AUTOSAR XML (schema 00050)
package /FCADT/ComponentTypes
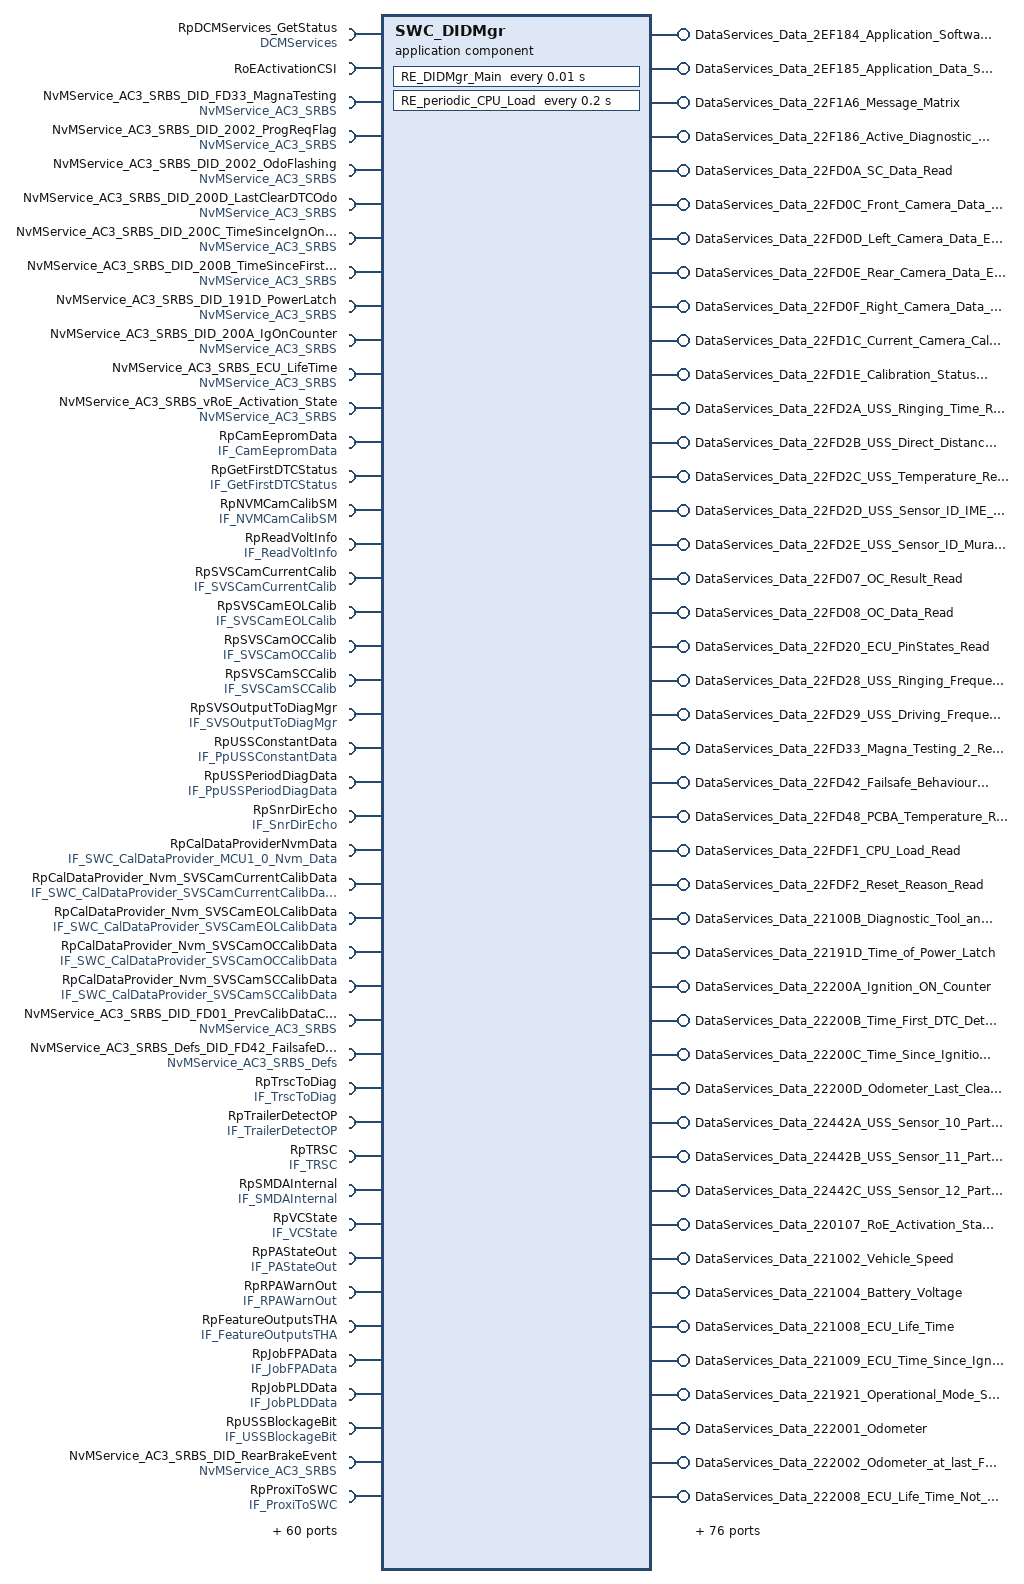
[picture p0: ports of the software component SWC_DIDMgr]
  application sw component type SWC_DIDMgr
    67 x provide port:
      DataServices_Data_2EF184_Application_Software_Fingerprint_writing_information: server-com-spec{operation=WriteData, queue-length=1}, provided-interface=DataServices_Data_2EF184_Application_Software_Fingerprint_writing_information
      DataServices_Data_2EF185_Application_Data_Software_Fingerprint_Writing_Information: server-com-spec{operation=WriteData, queue-length=1}, provided-interface=DataServices_Data_2EF185_Application_Data_Software_Fingerprint_Writing_Information
      DataServices_Data_22F1A6_Message_Matrix: server-com-spec{operation=ReadData, queue-length=1}, provided-interface=DataServices_Data_22F1A6_Message_Matrix
      DataServices_Data_22F186_Active_Diagnostic_Session: server-com-spec{operation=ReadData, queue-length=1}, provided-interface=DataServices_Data_22F186_Active_Diagnostic_Session
      DataServices_Data_22FD0A_SC_Data_Read: provided-com-specs=[{operation=ReadData, queue-length=1}, {operation=WriteData, queue-length=1}], provided-interface=DataServices_Data_22FD0A_SC_Data_Read
      DataServices_Data_22FD0C_Front_Camera_Data_EEPROM_Read: server-com-spec{operation=ReadData, queue-length=1}, provided-interface=DataServices_Data_22FD0C_Front_Camera_Data_EEPROM_Read
      DataServices_Data_22FD0D_Left_Camera_Data_EEPROM_Read: server-com-spec{operation=ReadData, queue-length=1}, provided-interface=DataServices_Data_22FD0D_Left_Camera_Data_EEPROM_Read
      DataServices_Data_22FD0E_Rear_Camera_Data_EEPROM_Read: server-com-spec{operation=ReadData, queue-length=1}, provided-interface=DataServices_Data_22FD0E_Rear_Camera_Data_EEPROM_Read
      DataServices_Data_22FD0F_Right_Camera_Data_EEPROM_Read: server-com-spec{operation=ReadData, queue-length=1}, provided-interface=DataServices_Data_22FD0F_Right_Camera_Data_EEPROM_Read
      DataServices_Data_22FD1C_Current_Camera_Calibration_Data_Read: server-com-spec{operation=ReadData, queue-length=1}, provided-interface=DataServices_Data_22FD1C_Current_Camera_Calibration_Data_Read
      DataServices_Data_22FD1E_Calibration_Status_Read: server-com-spec{operation=ReadData, queue-length=1}, provided-interface=DataServices_Data_22FD1E_Calibration_Status_Read
      DataServices_Data_22FD2A_USS_Ringing_Time_Read: server-com-spec{operation=ReadData, queue-length=1}, provided-interface=DataServices_Data_22FD2A_USS_Ringing_Time_Read
      DataServices_Data_22FD2B_USS_Direct_Distance_0xFD2B_Read: server-com-spec{operation=ReadData, queue-length=1}, provided-interface=DataServices_Data_22FD2B_USS_Direct_Distance_0xFD2B_Read
      DataServices_Data_22FD2C_USS_Temperature_Read: server-com-spec{operation=ReadData, queue-length=1}, provided-interface=DataServices_Data_22FD2C_USS_Temperature_Read
      DataServices_Data_22FD2D_USS_Sensor_ID_IME_SN_Read: server-com-spec{operation=ReadData, queue-length=1}, provided-interface=DataServices_Data_22FD2D_USS_Sensor_ID_IME_SN_Read
      DataServices_Data_22FD2E_USS_Sensor_ID_Murata_SN_Read: server-com-spec{operation=ReadData, queue-length=1}, provided-interface=DataServices_Data_22FD2E_USS_Sensor_ID_Murata_SN_Read
      DataServices_Data_22FD07_OC_Result_Read: server-com-spec{operation=ReadData, queue-length=1}, provided-interface=DataServices_Data_22FD07_OC_Result_Read
      DataServices_Data_22FD08_OC_Data_Read: provided-com-specs=[{operation=ReadData, queue-length=1}, {operation=WriteData, queue-length=1}], provided-interface=DataServices_Data_22FD08_OC_Data_Read
      DataServices_Data_22FD20_ECU_PinStates_Read: server-com-spec{operation=ReadData, queue-length=1}, provided-interface=DataServices_Data_22FD20_ECU_PinStates_Read
      DataServices_Data_22FD28_USS_Ringing_Frequency_Read: server-com-spec{operation=ReadData, queue-length=1}, provided-interface=DataServices_Data_22FD28_USS_Ringing_Frequency_Read
      DataServices_Data_22FD29_USS_Driving_Frequency_Read: server-com-spec{operation=ReadData, queue-length=1}, provided-interface=DataServices_Data_22FD29_USS_Driving_Frequency_Read
      DataServices_Data_22FD33_Magna_Testing_2_Read: provided-com-specs=[{operation=ReadData, queue-length=1}, {operation=WriteData, queue-length=1}], provided-interface=DataServices_Data_22FD33_Magna_Testing_2_Read
      DataServices_Data_22FD42_Failsafe_Behaviour_Read: provided-com-specs=[{operation=ReadData, queue-length=1}, {operation=WriteData, queue-length=1}], provided-interface=DataServices_Data_22FD42_Failsafe_Behaviour_Read
      DataServices_Data_22FD48_PCBA_Temperature_Read: server-com-spec{operation=ReadData, queue-length=1}, provided-interface=DataServices_Data_22FD48_PCBA_Temperature_Read
      DataServices_Data_22FDF1_CPU_Load_Read: server-com-spec{operation=ReadData, queue-length=1}, provided-interface=DataServices_Data_22FDF1_CPU_Load_Read
      DataServices_Data_22FDF2_Reset_Reason_Read: server-com-spec{operation=ReadData, queue-length=1}, provided-interface=DataServices_Data_22FDF2_Reset_Reason_Read
      DataServices_Data_22100B_Diagnostic_Tool_and_Session_Status: server-com-spec{operation=ReadData, queue-length=1}, provided-interface=DataServices_Data_22100B_Diagnostic_Tool_and_Session_Status
      DataServices_Data_22191D_Time_of_Power_Latch: server-com-spec{operation=ReadData, queue-length=1}, provided-interface=DataServices_Data_22191D_Time_of_Power_Latch
      DataServices_Data_22200A_Ignition_ON_Counter: server-com-spec{operation=ReadData, queue-length=1}, provided-interface=DataServices_Data_22200A_Ignition_ON_Counter
      DataServices_Data_22200B_Time_First_DTC_Detection: server-com-spec{operation=ReadData, queue-length=1}, provided-interface=DataServices_Data_22200B_Time_First_DTC_Detection
      DataServices_Data_22200C_Time_Since_Ignition_ON_of_first_DTC_Detection: server-com-spec{operation=ReadData, queue-length=1}, provided-interface=DataServices_Data_22200C_Time_Since_Ignition_ON_of_first_DTC_Detection
      DataServices_Data_22200D_Odometer_Last_Clear_Data_Trouble_Code_DTC: server-com-spec{operation=ReadData, queue-length=1}, provided-interface=DataServices_Data_22200D_Odometer_Last_Clear_Data_Trouble_Code_DTC
      DataServices_Data_22442A_USS_Sensor_10_Part_Number_Read: server-com-spec{operation=ReadData, queue-length=1}, provided-interface=DataServices_Data_22442A_USS_Sensor_10_Part_Number_Read
      DataServices_Data_22442B_USS_Sensor_11_Part_Number_Read: server-com-spec{operation=ReadData, queue-length=1}, provided-interface=DataServices_Data_22442B_USS_Sensor_11_Part_Number_Read
      DataServices_Data_22442C_USS_Sensor_12_Part_Number_Read: server-com-spec{operation=ReadData, queue-length=1}, provided-interface=DataServices_Data_22442C_USS_Sensor_12_Part_Number_Read
      DataServices_Data_220107_RoE_Activation_State: provided-com-specs=[{operation=ReadData, queue-length=1}, {operation=WriteData, queue-length=1}], provided-interface=DataServices_Data_220107_RoE_Activation_State
      DataServices_Data_221002_Vehicle_Speed: server-com-spec{operation=ReadData, queue-length=1}, provided-interface=DataServices_Data_221002_Vehicle_Speed
      DataServices_Data_221004_Battery_Voltage: server-com-spec{operation=ReadData, queue-length=1}, provided-interface=DataServices_Data_221004_Battery_Voltage
      DataServices_Data_221008_ECU_Life_Time: server-com-spec{operation=ReadData, queue-length=1}, provided-interface=DataServices_Data_221008_ECU_Life_Time
      DataServices_Data_221009_ECU_Time_Since_Ignition_ON: server-com-spec{operation=ReadData, queue-length=1}, provided-interface=DataServices_Data_221009_ECU_Time_Since_Ignition_ON
      DataServices_Data_221921_Operational_Mode_Status: server-com-spec{operation=ReadData, queue-length=1}, provided-interface=DataServices_Data_221921_Operational_Mode_Status
      DataServices_Data_222001_Odometer: server-com-spec{operation=ReadData, queue-length=1}, provided-interface=DataServices_Data_222001_Odometer
      DataServices_Data_222002_Odometer_at_last_Flash_programming: server-com-spec{operation=ReadData, queue-length=1}, provided-interface=DataServices_Data_222002_Odometer_at_last_Flash_programming
      DataServices_Data_222008_ECU_Life_Time_Not_Volatile_Memory: server-com-spec{operation=ReadData, queue-length=1}, provided-interface=DataServices_Data_222008_ECU_Life_Time_Not_Volatile_Memory
      DataServices_Data_222010_Programming_Status: server-com-spec{operation=ReadData, queue-length=1}, provided-interface=DataServices_Data_222010_Programming_Status
      DataServices_Data_222945_Flow_Control_Test: provided-com-specs=[{operation=ReadData, queue-length=1}, {operation=WriteData, queue-length=1}], provided-interface=DataServices_Data_222945_Flow_Control_Test
      DataServices_Data_224421_USS_Sensor_1_Part_Number_Read: server-com-spec{operation=ReadData, queue-length=1}, provided-interface=DataServices_Data_224421_USS_Sensor_1_Part_Number_Read
      DataServices_Data_224422_USS_Sensor2_Part_Number_Read: server-com-spec{operation=ReadData, queue-length=1}, provided-interface=DataServices_Data_224422_USS_Sensor2_Part_Number_Read
      DataServices_Data_224423_USS_Sensor_3_Part_Number_Read: server-com-spec{operation=ReadData, queue-length=1}, provided-interface=DataServices_Data_224423_USS_Sensor_3_Part_Number_Read
      DataServices_Data_224424_USS_Sensor_4_Part_Number_Read: server-com-spec{operation=ReadData, queue-length=1}, provided-interface=DataServices_Data_224424_USS_Sensor_4_Part_Number_Read
      DataServices_Data_224425_USS_Sensor_5_Part_Number_Read: server-com-spec{operation=ReadData, queue-length=1}, provided-interface=DataServices_Data_224425_USS_Sensor_5_Part_Number_Read
      DataServices_Data_224426_USS_Sensor_6_Part_Number_Read: server-com-spec{operation=ReadData, queue-length=1}, provided-interface=DataServices_Data_224426_USS_Sensor_6_Part_Number_Read
      DataServices_Data_224427_USS_Sensor_7_Part_Number_Read: server-com-spec{operation=ReadData, queue-length=1}, provided-interface=DataServices_Data_224427_USS_Sensor_7_Part_Number_Read
      DataServices_Data_224428_USS_Sensor_8_Part_Number_Read: server-com-spec{operation=ReadData, queue-length=1}, provided-interface=DataServices_Data_224428_USS_Sensor_8_Part_Number_Read
      DataServices_Data_224429_USS_Sensor_9_Part_Number_Read: server-com-spec{operation=ReadData, queue-length=1}, provided-interface=DataServices_Data_224429_USS_Sensor_9_Part_Number_Read
      DataServices_Data_224451_EOL_Calibration_State_Read: server-com-spec{operation=ReadData, queue-length=1}, provided-interface=DataServices_Data_224451_EOL_Calibration_State_Read
      DataServices_Data_225100_SPM_status_Read: server-com-spec{operation=ReadData, queue-length=1}, provided-interface=DataServices_Data_225100_SPM_status_Read
      DataServices_Data_225300_Rear_Braking_Event_1_Read: server-com-spec{operation=ReadData, queue-length=1}, provided-interface=DataServices_Data_225300_Rear_Braking_Event_1_Read
      DataServices_Data_225301_Rear_Braking_Event_2_Read: server-com-spec{operation=ReadData, queue-length=1}, provided-interface=DataServices_Data_225301_Rear_Braking_Event_2_Read
      DataServices_Data_225302_Rear_Braking_Event_3_Read: server-com-spec{operation=ReadData, queue-length=1}, provided-interface=DataServices_Data_225302_Rear_Braking_Event_3_Read
      DataServices_Data_225303_SPM_Event_Abort_1_Read: server-com-spec{operation=ReadData, queue-length=1}, provided-interface=DataServices_Data_225303_SPM_Event_Abort_1_Read
      DataServices_Data_225304_SPM_Event_Abort_2_Read: server-com-spec{operation=ReadData, queue-length=1}, provided-interface=DataServices_Data_225304_SPM_Event_Abort_2_Read
      DataServices_Data_225500_Trailer_Sense_and_Drive_Function_Data_Read: server-com-spec{operation=ReadData, queue-length=1}, provided-interface=DataServices_Data_225500_Trailer_Sense_and_Drive_Function_Data_Read
      DataServices_Data_225501_Trailer_coupler_sense_detection_Function_Data_Read: server-com-spec{operation=ReadData, queue-length=1}, provided-interface=DataServices_Data_225501_Trailer_coupler_sense_detection_Function_Data_Read
      PpECUTimeSinceIGON: nonqueued-sender-com-spec{data-element=ECUTimeStamp_IGON, init-value=0}, provided-interface=IF_ECUTimeSince_IGON
      PpECUTimeStamp: nonqueued-sender-com-spec{data-element=ECUTimeStamp, init-value=0}, provided-interface=IF_ECUTimeStamp
      PpIgOnCounter: nonqueued-sender-com-spec{data-element=IGCounter, init-value=0}, provided-interface=IF_IGON_Counter
    require port RpDCMServices_GetStatus: required-interface=DCMServices
      required-com-specs:
        GetSesCtrlType
        GetRequestKind
        SetActiveDiagnostic
        GetSecurityLevel
        ResetToDefaultSession
        GetActiveProtocol
    require port RoEActivationCSI: required-com-specs=[WriteData, ReadData], required-interface=RoEActivationCSI
    provide port DataServices_Data_22FD01_Previous_Camera_Calibration_Data: server-com-spec{operation=ReadData, queue-length=1}, provided-interface=DataServices_Data_22FD01_Previous_Camera_Calibration_Data
    provide port DataServices_Data_22FD00_Plant_Camera_Calibration_Data: provided-com-specs=[{operation=WriteData, queue-length=1}, {operation=ReadData, queue-length=1}], provided-interface=DataServices_Data_22FD00_Plant_Camera_Calibration_Data
    provide port DataServices_Data_225305_SPM_Event_Abort_3_Read: server-com-spec{operation=ReadData, queue-length=1}, provided-interface=DataServices_Data_225305_SPM_Event_Abort_3_Read
    29 x require port:
      NvMService_AC3_SRBS_DID_FD33_MagnaTesting: required-com-specs=[WriteBlock, SetRamBlockStatus, ReadBlock, InvalidateNvBlock, GetErrorStatus, EraseBlock], required-interface=NvMService_AC3_SRBS
      NvMService_AC3_SRBS_DID_2002_ProgReqFlag: required-com-specs=[WriteBlock, SetRamBlockStatus, ReadBlock, InvalidateNvBlock, GetErrorStatus, EraseBlock], required-interface=NvMService_AC3_SRBS
      NvMService_AC3_SRBS_DID_2002_OdoFlashing: required-com-specs=[WriteBlock, SetRamBlockStatus, ReadBlock, InvalidateNvBlock, GetErrorStatus, EraseBlock], required-interface=NvMService_AC3_SRBS
      NvMService_AC3_SRBS_DID_200D_LastClearDTCOdo: required-com-specs=[WriteBlock, SetRamBlockStatus, ReadBlock, InvalidateNvBlock, GetErrorStatus, EraseBlock], required-interface=NvMService_AC3_SRBS
      NvMService_AC3_SRBS_DID_200C_TimeSinceIgnOnFirstDTC: required-com-specs=[WriteBlock, SetRamBlockStatus, ReadBlock, InvalidateNvBlock, GetErrorStatus, EraseBlock], required-interface=NvMService_AC3_SRBS
      NvMService_AC3_SRBS_DID_200B_TimeSinceFirstDTC: required-com-specs=[WriteBlock, SetRamBlockStatus, ReadBlock, InvalidateNvBlock, GetErrorStatus, EraseBlock], required-interface=NvMService_AC3_SRBS
      NvMService_AC3_SRBS_DID_191D_PowerLatch: required-com-specs=[WriteBlock, SetRamBlockStatus, ReadBlock, InvalidateNvBlock, GetErrorStatus, EraseBlock], required-interface=NvMService_AC3_SRBS
      NvMService_AC3_SRBS_DID_200A_IgOnCounter: required-com-specs=[WriteBlock, SetRamBlockStatus, ReadBlock, InvalidateNvBlock, GetErrorStatus, EraseBlock], required-interface=NvMService_AC3_SRBS
      NvMService_AC3_SRBS_ECU_LifeTime: required-com-specs=[WriteBlock, SetRamBlockStatus, ReadBlock, InvalidateNvBlock, GetErrorStatus, EraseBlock], required-interface=NvMService_AC3_SRBS
      NvMService_AC3_SRBS_vRoE_Activation_State: required-com-specs=[WriteBlock, SetRamBlockStatus, ReadBlock, InvalidateNvBlock, GetErrorStatus, EraseBlock], required-interface=NvMService_AC3_SRBS
      RpCamEepromData: nonqueued-receiver-com-spec{data-element=Svs_CamEepromDataArray_t, filter=data-filter-type=ALWAYS}, required-interface=IF_CamEepromData
      RpGetFirstDTCStatus: nonqueued-receiver-com-spec{data-element=DeFirstDTCStatus, filter=data-filter-type=ALWAYS}, required-interface=IF_GetFirstDTCStatus
      RpNVMCamCalibSM: nonqueued-receiver-com-spec{data-element=TbSVS_e_SVSOutputToNVMCamCalibSM_t, filter=data-filter-type=ALWAYS}, required-interface=IF_NVMCamCalibSM
      RpReadVoltInfo: client-com-spec=GetVoltageInfo, required-interface=IF_ReadVoltInfo
      RpSVSCamCurrentCalib: nonqueued-receiver-com-spec{data-element=TbSVS_S_SVSCamCurrentCalibDataToNVM_t, filter=data-filter-type=ALWAYS}, required-interface=IF_SVSCamCurrentCalib
      RpSVSCamEOLCalib: nonqueued-receiver-com-spec{data-element=TbSVS_S_SVSCamEOLCalibDataToNVM_t, filter=data-filter-type=ALWAYS}, required-interface=IF_SVSCamEOLCalib
      RpSVSCamOCCalib: nonqueued-receiver-com-spec{data-element=TbSVS_S_SVSCamOCCalibDataToNVM_t, filter=data-filter-type=ALWAYS}, required-interface=IF_SVSCamOCCalib
      RpSVSCamSCCalib: nonqueued-receiver-com-spec{data-element=TbSVS_S_SVSCamSCCalibDataToNVM_t, filter=data-filter-type=ALWAYS}, required-interface=IF_SVSCamSCCalib
      RpSVSOutputToDiagMgr: nonqueued-receiver-com-spec{data-element=TbSVS_e_SVSOutputToDiagMgrCamCalib_t, filter=data-filter-type=ALWAYS}, required-interface=IF_SVSOutputToDiagMgr
      RpUSSConstantData: nonqueued-receiver-com-spec{data-element=US_S_USSConstantData_t, filter=data-filter-type=ALWAYS}, required-interface=IF_PpUSSConstantData
      RpUSSPeriodDiagData: nonqueued-receiver-com-spec{data-element=US_S_USSPeriodDiagData_t, filter=data-filter-type=ALWAYS}, required-interface=IF_PpUSSPeriodDiagData
      RpSnrDirEcho: nonqueued-receiver-com-spec{data-element=US_S_SnrDirEcho_t, filter=data-filter-type=ALWAYS}, required-interface=IF_SnrDirEcho
      RpCalDataProviderNvmData: nonqueued-receiver-com-spec{data-element=CalData_mcu1_0, filter=data-filter-type=ALWAYS}, required-interface=IF_SWC_CalDataProvider_MCU1_0_Nvm_Data
      RpCalDataProvider_Nvm_SVSCamCurrentCalibData: client-com-spec=WriteBlock, required-interface=IF_SWC_CalDataProvider_SVSCamCurrentCalibData
      RpCalDataProvider_Nvm_SVSCamEOLCalibData: client-com-spec=WriteBlock, required-interface=IF_SWC_CalDataProvider_SVSCamEOLCalibData
      RpCalDataProvider_Nvm_SVSCamOCCalibData: client-com-spec=WriteBlock, required-interface=IF_SWC_CalDataProvider_SVSCamOCCalibData
      RpCalDataProvider_Nvm_SVSCamSCCalibData: client-com-spec=WriteBlock, required-interface=IF_SWC_CalDataProvider_SVSCamSCCalibData
      NvMService_AC3_SRBS_DID_FD01_PrevCalibDataCopy: required-com-specs=[WriteBlock, SetRamBlockStatus, ReadBlock, InvalidateNvBlock, GetErrorStatus, EraseBlock], required-interface=NvMService_AC3_SRBS
      NvMService_AC3_SRBS_Defs_DID_FD42_FailsafeDebug: required-com-specs=[EraseBlock, InvalidateNvBlock, RestoreBlockDefaults, WriteBlock, ReadBlock, SetRamBlockStatus, GetErrorStatus], required-interface=NvMService_AC3_SRBS_Defs
    provide port PpFailsafeDebug: nonqueued-sender-com-spec{data-element=Debugflag, init-value=0}, provided-interface=IF_FailsafeDebug
    23 x require port:
      RpTrscToDiag: nonqueued-receiver-com-spec{data-element=TRSCtoDiagMgr_t, filter=data-filter-type=ALWAYS}, required-interface=IF_TrscToDiag
      RpTrailerDetectOP: nonqueued-receiver-com-spec{data-element=TrailerDetection_Output_DID_t, filter=data-filter-type=ALWAYS}, required-interface=IF_TrailerDetectOP
      RpTRSC: nonqueued-receiver-com-spec=data-element=ME_VehOut_TRSC_t, required-interface=IF_TRSC
      RpSMDAInternal: nonqueued-receiver-com-spec=data-element=TbAP_SMDAInternalOut_t, required-interface=IF_SMDAInternal
      RpVCState: nonqueued-receiver-com-spec=data-element=TbAP_VCStateOut_t, required-interface=IF_VCState
      RpPAStateOut: nonqueued-receiver-com-spec=data-element=TbAP_PAStateOut_t, required-interface=IF_PAStateOut
      RpRPAWarnOut: nonqueued-receiver-com-spec=data-element=TbAP_RPAWarnOut_t, required-interface=IF_RPAWarnOut
      RpFeatureOutputsTHA: nonqueued-receiver-com-spec=data-element=TbTHASmVc_FeatureOutputs_t, required-interface=IF_FeatureOutputsTHA
      RpJobFPAData: nonqueued-receiver-com-spec{data-element=IJobFPAOutput_t, filter=data-filter-type=ALWAYS}, required-interface=IF_JobFPAData
      RpJobPLDData: nonqueued-receiver-com-spec{data-element=IJobPLDOutput_t, filter=data-filter-type=ALWAYS}, required-interface=IF_JobPLDData
      RpUSSBlockageBit: nonqueued-receiver-com-spec{data-element=US_S_BlockageBit_t, filter=data-filter-type=ALWAYS}, required-interface=IF_USSBlockageBit
      NvMService_AC3_SRBS_DID_RearBrakeEvent: required-com-specs=[WriteBlock, SetRamBlockStatus, ReadBlock, InvalidateNvBlock, GetErrorStatus, EraseBlock], required-interface=NvMService_AC3_SRBS
      RpProxiToSWC: required-interface=IF_ProxiToSWC
        required-com-specs:
          data-element=TyreSz_u16, filter=data-filter-type=ALWAYS
          data-element=SurroundViewCam_u8, filter=data-filter-type=ALWAYS
          data-element=Fullautomaticparking, filter=data-filter-type=ALWAYS
          data-element=PRX_CanNod27_b, filter=data-filter-type=ALWAYS
          data-element=Parkwithstop_u8, filter=data-filter-type=ALWAYS
          data-element=Trailerhitchassist_u8, filter=data-filter-type=ALWAYS
          data-element=PAMConfig_u8, filter=data-filter-type=ALWAYS
          data-element=Pamtuningset, filter=data-filter-type=ALWAYS
      NvMService_AC3_SRBS_DID_SPMAbrtEvent: required-com-specs=[WriteBlock, SetRamBlockStatus, ReadBlock, InvalidateNvBlock, GetErrorStatus, EraseBlock], required-interface=NvMService_AC3_SRBS
      RpScreenRequest: nonqueued-receiver-com-spec{data-element=ScreenRequest_t, filter=data-filter-type=ALWAYS}, required-interface=IF_ScreenRequest
      RpSvsToVCAN: nonqueued-receiver-com-spec{data-element=SvsToVCAN_t, filter=data-filter-type=ALWAYS, init-value=fields=[IeSVS_b_SPMScrnReq:0, IeSVS_b_ImgDefeatReqSts:0, IeSVS_b_MoreCamsReqSts:0, IeSVS_b_AUXCamReqSts:0, IeSVS_e_DispView2:0]}, required-interface=IF_SvsToVCAN
      RpCryptoArray: client-com-spec=CryptoArray, required-interface=IF_CryptoArray
      RpCpuLoadMcu2_1: nonqueued-receiver-com-spec{data-element=CpuLoadMcu2_1_t, filter=data-filter-type=ALWAYS, init-value=fields=CpluLoad_MCU2_1_u32:0}, required-interface=IF_CpuLoadMcu2_1
      RpCpuLoadMcu2_0: nonqueued-receiver-com-spec{data-element=CpuLoadMcu2_0_t, filter=data-filter-type=ALWAYS, init-value=fields=CpluLoad_MCU2_0_u32:0}, required-interface=IF_CpuLoadMcu2_0
      RpUSSErrorDiagData: nonqueued-receiver-com-spec=data-element=US_S_USSErrorDiagData_t, required-interface=IF_USSErrorDiagData
      RpPointDistOpBuff: nonqueued-receiver-com-spec{data-element=US_S_PointDistOutputBuff_t, filter=data-filter-type=ALWAYS, init-value=fields=[timestamp:0, minDist:16 x 0, midDist:12 x 0]}, required-interface=IF_PointDistOpBuff
      RpJobTHADetOutput: nonqueued-receiver-com-spec{data-element=JobTHADetOutput_t, filter=data-filter-type=ALWAYS}, required-interface=IF_JobTHADetOutput
      RpSvsToTHA: nonqueued-receiver-com-spec{data-element=SvsToTHA_t, filter=data-filter-type=ALWAYS}, required-interface=IF_SvsToTHA
    provide port DataServices_Data_22FD86_Functional_Settings_Read: provided-com-specs=[{operation=WriteData, queue-length=1}, {operation=ReadData, queue-length=1}], provided-interface=DataServices_Data_22FD86_Functional_Settings_Read
    4 x require port:
      RpError_CS_B: client-com-spec=ReportErrorStatus1_0_B, required-interface=P_Error_CS
      RpError_CS_QM: client-com-spec=ReportErrorStatus1_0_QM, required-interface=P_Error_CS
      NvMService_AC3_SRBS_DID_FD86_FunctionalSettings: required-com-specs=[WriteBlock, SetRamBlockStatus, ReadBlock, InvalidateNvBlock, GetErrorStatus, EraseBlock], required-interface=NvMService_AC3_SRBS
      RpTbTHASmVcDiag: nonqueued-receiver-com-spec{data-element=TbTHASmVc_DiagMgr_t, filter=data-filter-type=ALWAYS}, required-interface=IF_TbTHASmVcDiag
    provide port DataServices_Data_22FD46_Camera_Power_Supply_Read: server-com-spec{operation=ReadData, queue-length=1}, provided-interface=DataServices_Data_22FD46_Camera_Power_Supply_Read
    require port RpCamCsData: nonqueued-receiver-com-spec{data-element=CAM_CS_Curr_Monitor_t, filter=data-filter-type=ALWAYS}, required-interface=IF_CamCsData
    require port RpUssPowerData: nonqueued-receiver-com-spec{data-element=UssPower, filter=data-filter-type=ALWAYS, init-value=fields=[v_USS_PWR_A_MON_f32:0, v_USS_PWR_B_MON_f32:0, v_USS_PWR_C_MON_f32:0, v_USS_PWR_IS1_MON_MON_f32:[0, 0], v_USS_PWR_IS2_MON_MON_f32:0]}, required-interface=IF_UssPowerData
    26 x provide port:
      DataServices_Data_2F5001_Gear_Position_Read: provided-interface=DataServices_Data_2F5001_Gear_Position_Read
        provided-com-specs:
          operation=ShortTermAdjustment, queue-length=1
          operation=ReturnControlToECU, queue-length=1
          operation=ReadData, queue-length=1
      DataServices_Data_225102_FD_CAN14_Rx_Signals_Read: server-com-spec{operation=ReadData, queue-length=1}, provided-interface=DataServices_Data_225102_FD_CAN14_Rx_Signals_Read
      DataServices_Data_225103_FD_CAN2_Rx_Signals_Read: server-com-spec{operation=ReadData, queue-length=1}, provided-interface=DataServices_Data_225103_FD_CAN2_Rx_Signals_Read
      DataServices_Data_225104_FD_CAN14_Tx_Signals_Read: server-com-spec{operation=ReadData, queue-length=1}, provided-interface=DataServices_Data_225104_FD_CAN14_Tx_Signals_Read
      DataServices_Data_225105_FD_CAN2_Tx_Signals_Read: server-com-spec{operation=ReadData, queue-length=1}, provided-interface=DataServices_Data_225105_FD_CAN2_Tx_Signals_Read
      DataServices_Data_2EFD4E_Reset_NVM_Write: server-com-spec{operation=WriteData, queue-length=1}, provided-interface=DataServices_Data_2EFD4E_Reset_NVM_Write
      DataServices_Data_22FD47_SoC_Temperature_0xFD47_Read: server-com-spec{operation=ReadData, queue-length=1}, provided-interface=DataServices_Data_22FD47_SoC_Temperature_0xFD47_Read
      DataServices_Data_22FD49_SoC_Die_Temperature_ID_0xFD49_Read: server-com-spec{operation=ReadData, queue-length=1}, provided-interface=DataServices_Data_22FD49_SoC_Die_Temperature_ID_0xFD49_Read
      DataServices_Data_22FD60_ECU_Software_Status_Read: server-com-spec{operation=ReadData, queue-length=1}, provided-interface=DataServices_Data_22FD60_ECU_Software_Status_Read
      DataServices_Data_22FD62_ASIL_QM_Fault_Status_Read: server-com-spec{operation=ReadData, queue-length=1}, provided-interface=DataServices_Data_22FD62_ASIL_QM_Fault_Status_Read
      DataServices_Data_22FD64_ASIL_B_Fault_Status_Read: server-com-spec{operation=ReadData, queue-length=1}, provided-interface=DataServices_Data_22FD64_ASIL_B_Fault_Status_Read
      DataServices_Data_22FDF0_ECU_shutdown_process_Read: provided-com-specs=[{operation=WriteData, queue-length=1}, {operation=ReadData, queue-length=1}], provided-interface=DataServices_Data_22FDF0_ECU_shutdown_process_Read
      DataServices_Data_222026_CAN_Overrun_Counters: server-com-spec{operation=ReadData, queue-length=1}, provided-interface=DataServices_Data_222026_CAN_Overrun_Counters
      DataServices_Data_222939_FDCAN2_BUS_Network_WakeUp_Reason: server-com-spec{operation=ReadData, queue-length=1}, provided-interface=DataServices_Data_222939_FDCAN2_BUS_Network_WakeUp_Reason
      DataServices_Data_2E2023_PROXI_Data: server-com-spec{operation=WriteData, queue-length=1}, provided-interface=DataServices_Data_2E2023_PROXI_Data
      DataServices_Data_22F1A1_Configuration_Code: server-com-spec{operation=ReadData, queue-length=1}, provided-interface=DataServices_Data_22F1A1_Configuration_Code
      DataServices_Data_22F1B0_VIN_Current: server-com-spec{operation=ReadData, queue-length=1}, provided-interface=DataServices_Data_22F1B0_VIN_Current
      DataServices_Data_22F190_VIN_Original: server-com-spec{operation=ReadData, queue-length=1}, provided-interface=DataServices_Data_22F190_VIN_Original
      DataServices_Data_22FD61_Vehicle_Variant_Coding_Data_Read: server-com-spec{operation=ReadData, queue-length=1}, provided-interface=DataServices_Data_22FD61_Vehicle_Variant_Coding_Data_Read
      DataServices_Data_22102A_Check_EOL_Configuration_Data: server-com-spec{operation=ReadData, queue-length=1}, provided-interface=DataServices_Data_22102A_Check_EOL_Configuration_Data
      DataServices_Data_22292E_PROXI_Write_Counter: server-com-spec{operation=ReadData, queue-length=1}, provided-interface=DataServices_Data_22292E_PROXI_Write_Counter
      DataServices_Data_220103_VIN_Lock_Status: server-com-spec{operation=ReadData, queue-length=1}, provided-interface=DataServices_Data_220103_VIN_Lock_Status
      DataServices_Data_222013_VIN_Lock_State_Read: server-com-spec{operation=ReadData, queue-length=1}, provided-interface=DataServices_Data_222013_VIN_Lock_State_Read
      DataServices_Data_222024_Read_ECU_PROXI_Data: provided-com-specs=[{operation=ReadDataLength, queue-length=1}, {operation=ReadData, queue-length=1}], provided-interface=DataServices_Data_222024_Read_ECU_PROXI_Data
      DataServices_Data_225201_Plant_Mode_Status_Read: server-com-spec{operation=ReadData, queue-length=1}, provided-interface=DataServices_Data_225201_Plant_Mode_Status_Read
      DataServices_Data_22F10B_ECU_Qualification: server-com-spec{operation=ReadData, queue-length=1}, provided-interface=DataServices_Data_22F10B_ECU_Qualification
    require port NvMService_AC3_SRBS_DID_FDF0_SleepProcess: required-com-specs=[WriteBlock, SetRamBlockStatus, ReadBlock, InvalidateNvBlock, GetErrorStatus, EraseBlock], required-interface=NvMService_AC3_SRBS
    require port NvMService_AC3_SRBS_DID_2939_WakeupReason: required-com-specs=[WriteBlock, SetRamBlockStatus, ReadBlock, InvalidateNvBlock, GetErrorStatus, EraseBlock], required-interface=NvMService_AC3_SRBS
    provide port PpSleepProcessState: nonqueued-sender-com-spec{data-element=status, init-value=0}, provided-interface=IF_SleepProcessState
    require port Rp2023_ProxiData: client-com-spec=WriteData, required-interface=IF_2023_ProxiData
    require port RpVariantData: nonqueued-receiver-com-spec{data-element=Variant, filter=data-filter-type=ALWAYS}, required-interface=IF_VariantData
    require port RpProxiConfigData: nonqueued-receiver-com-spec{data-element=ProxiData, filter=data-filter-type=ALWAYS}, required-interface=IF_ProxiConfigData
    provide port PpGearPosition: provided-com-specs=[{data-element=GearValue, init-value=0}, {data-element=ShortTermAdjActiveFlag_b, init-value=0}], provided-interface=IF_GearPosition
    7 x require port:
      RpVINData: required-interface=IF_VINData
        required-com-specs:
          data-element=VINOriginalData, filter=data-filter-type=ALWAYS
          data-element=VINCurrentData, filter=data-filter-type=ALWAYS
          data-element=VINOdoCounter, filter=data-filter-type=ALWAYS
          data-element=VINLockStatus, filter=data-filter-type=ALWAYS
      RpPlantMode: nonqueued-receiver-com-spec{data-element=Status, filter=data-filter-type=ALWAYS}, required-interface=IF_PlantMode
      RpProxiErrorData: nonqueued-receiver-com-spec{data-element=Error, filter=data-filter-type=ALWAYS, init-value=fields=[ErrorFound:[0, 0, 0], ByteWithError:[0, 0, 0], BitInformationMask:[0, 0, 0]]}, required-interface=IF_ProxiErrorData
      RpToSwcSafeFD02Rx: required-interface=IF_FromComSafeFD02Rx
        required-com-specs:
          data-element=Active_Park_Mode, filter=data-filter-type=ALWAYS, init-value=0
          data-element=Active_Park_Prox_Chime, filter=data-filter-type=ALWAYS, init-value=0
          data-element=APARequestSts, filter=data-filter-type=ALWAYS, init-value=0
          data-element=Backup_Cam_Delay, filter=data-filter-type=ALWAYS, init-value=0
          data-element=Brk_Stat, filter=data-filter-type=ALWAYS, init-value=0
          data-element=CmdIgnSts, filter=data-filter-type=ALWAYS, init-value=0
          data-element=DriverDoorSts, filter=data-filter-type=ALWAYS, init-value=0
          data-element=DynamicGrid, filter=data-filter-type=ALWAYS, init-value=1
          data-element=ExternalTemperature, filter=data-filter-type=ALWAYS, init-value=0
          data-element=FT_PAMRequestSts, filter=data-filter-type=ALWAYS, init-value=0
          data-element=Fwrd_Cam_Guidelines, filter=data-filter-type=ALWAYS, init-value=0
          data-element=GearEngaged, filter=data-filter-type=ALWAYS, init-value=0
          data-element=HAS_Status_C2, filter=data-filter-type=ALWAYS, init-value=0
          data-element=LanguageSelection, filter=data-filter-type=ALWAYS, init-value=0
          data-element=LatAcceleration_BSM, filter=data-filter-type=ALWAYS, init-value=4095
          data-element=LHRDoorSts, filter=data-filter-type=ALWAYS, init-value=0
          data-element=LongAcceleration_BSM, filter=data-filter-type=ALWAYS, init-value=4095
          data-element=LwsAngle, filter=data-filter-type=ALWAYS, init-value=0
          data-element=LwsAngleType, filter=data-filter-type=ALWAYS, init-value=0
          data-element=LwsSpeed, filter=data-filter-type=ALWAYS, init-value=0
          data-element=MRM_STATUS_C2, filter=data-filter-type=ALWAYS, init-value=0
          data-element=PamChimeVolumeFront, filter=data-filter-type=ALWAYS, init-value=1
          data-element=PamChimeVolumeRear, filter=data-filter-type=ALWAYS, init-value=1
          data-element=PAMRequestSts, filter=data-filter-type=ALWAYS, init-value=0
          data-element=PsngrDoorSts, filter=data-filter-type=ALWAYS, init-value=0
          data-element=Rear_Brk_Asst, filter=data-filter-type=ALWAYS, init-value=0
          data-element=RHatchSts, filter=data-filter-type=ALWAYS, init-value=0
          data-element=RHRDoorSts, filter=data-filter-type=ALWAYS, init-value=0
          data-element=ShiftLeverPosition, filter=data-filter-type=ALWAYS, init-value=0
          data-element=SVC_Guidelines, filter=data-filter-type=ALWAYS, init-value=0
          data-element=TargetGear, filter=data-filter-type=ALWAYS, init-value=15
          data-element=TCASERANGESTATUS, filter=data-filter-type=ALWAYS, init-value=0
          data-element=TGW_CAMERA_DISP_STAT, filter=data-filter-type=ALWAYS, init-value=0
          data-element=TrailerConnectionSts, filter=data-filter-type=ALWAYS, init-value=0
          data-element=TRANS_ADAS_Inhibit, filter=data-filter-type=ALWAYS, init-value=0
          data-element=TransmissionSailingSts, filter=data-filter-type=ALWAYS, init-value=0
          data-element=VehicleSpeedVSOSig, filter=data-filter-type=ALWAYS, init-value=0
          data-element=YawRate_BSM, filter=data-filter-type=ALWAYS, init-value=4095
          data-element=VIN_MSG, filter=data-filter-type=ALWAYS
          data-element=VIN_DATA, filter=data-filter-type=ALWAYS
          data-element=RR_Lvl_Adj, filter=data-filter-type=ALWAYS
          data-element=RR_Lvl, filter=data-filter-type=ALWAYS
          data-element=RL_Lvl_Adj, filter=data-filter-type=ALWAYS
          data-element=RL_Lvl, filter=data-filter-type=ALWAYS
          data-element=HU_TRSC_EnableBtn_Sts, filter=data-filter-type=ALWAYS
          data-element=GearEngagedForDisplay, filter=data-filter-type=ALWAYS
          data-element=FR_Lvl_Adj, filter=data-filter-type=ALWAYS
          data-element=FR_Lvl, filter=data-filter-type=ALWAYS
          data-element=FL_Lvl_Adj, filter=data-filter-type=ALWAYS
          data-element=FL_Lvl, filter=data-filter-type=ALWAYS
          data-element=ESS_ENG_ST_W, filter=data-filter-type=ALWAYS
          data-element=EngineSts_W, filter=data-filter-type=ALWAYS
          data-element=ECM_TRSC_Resp, filter=data-filter-type=ALWAYS
          data-element=ECM_THA_Resp, filter=data-filter-type=ALWAYS
          data-element=ASCM_SysFail, filter=data-filter-type=ALWAYS
          data-element=ASCM_Stat, filter=data-filter-type=ALWAYS
          data-element=PdlPosActual, filter=data-filter-type=ALWAYS
          data-element=THA_SteeringTouchStat, filter=data-filter-type=ALWAYS
          data-element=EPS_THA_SteeringTorqueResp, filter=data-filter-type=ALWAYS
          data-element=EPS_THA_DriverTorqueOverride, filter=data-filter-type=ALWAYS
          data-element=EPS_SteeringTouq_Resp, filter=data-filter-type=ALWAYS
          data-element=EPS_SteeringTouchStat, filter=data-filter-type=ALWAYS
          data-element=ShiftLeverPositionReq, filter=data-filter-type=ALWAYS
          data-element=Shifter_ADAS_Inhibit, filter=data-filter-type=ALWAYS
          data-element=ITBM_TrlrStat, filter=data-filter-type=ALWAYS
          data-element=CM_TCH_Y_COORD, filter=data-filter-type=ALWAYS
          data-element=CM_TCH_X_COORD, filter=data-filter-type=ALWAYS
          data-element=CM_TCH_STAT, filter=data-filter-type=ALWAYS
          data-element=CameraDisplaySts2, filter=data-filter-type=ALWAYS
      RpToSwcSafeFD14Rx: required-interface=IF_FromComSafeFD14Rx
        required-com-specs:
          data-element=FD14_ACC_Systemsts, filter=data-filter-type=ALWAYS, init-value=0
          data-element=FD14_Brk_Stat, filter=data-filter-type=ALWAYS, init-value=0
          data-element=FD14_BrkPdl_Stat, filter=data-filter-type=ALWAYS, init-value=3
          data-element=FD14_BrkTrq, filter=data-filter-type=ALWAYS, init-value=32767
          data-element=FD14_BrkTrq_Driver, filter=data-filter-type=ALWAYS, init-value=32767
          data-element=FD14_BSM_THA_Brk_Resp, filter=data-filter-type=ALWAYS, init-value=0
          data-element=FD14_EPBSts, filter=data-filter-type=ALWAYS, init-value=0
          data-element=FD14_EPS_HandsOnRecognition, filter=data-filter-type=ALWAYS, init-value=0
          data-element=FD14_ESC_TRSC_Brk_Resp, filter=data-filter-type=ALWAYS, init-value=0
          data-element=FD14_ExternalBrkRequestsDisabled, filter=data-filter-type=ALWAYS, init-value=0
          data-element=FD14_HAS_Status, filter=data-filter-type=ALWAYS, init-value=0
          data-element=FD14_LatAcceleration_BSM, filter=data-filter-type=ALWAYS, init-value=4095
          data-element=FD14_LatAccelerationFailSts_BSM, filter=data-filter-type=ALWAYS, init-value=0
          data-element=FD14_LatAccelerationOffset_BSM, filter=data-filter-type=ALWAYS, init-value=255
          data-element=FD14_LHF_FastPulseCounter, filter=data-filter-type=ALWAYS, init-value=0
          data-element=FD14_LHF_Spin, filter=data-filter-type=ALWAYS, init-value=0
          data-element=FD14_LHF_WheelSensorFailSts, filter=data-filter-type=ALWAYS, init-value=0
          data-element=FD14_LHFWheelSpeed, filter=data-filter-type=ALWAYS, init-value=0
          data-element=FD14_LHR_FastPulseCounter, filter=data-filter-type=ALWAYS, init-value=0
          data-element=FD14_LHR_Spin, filter=data-filter-type=ALWAYS, init-value=0
          data-element=FD14_LHR_WheelSensorFailSts, filter=data-filter-type=ALWAYS, init-value=0
          data-element=FD14_LHRWheelSpeed, filter=data-filter-type=ALWAYS, init-value=0
          data-element=FD14_LongAcceleration_BSM, filter=data-filter-type=ALWAYS, init-value=4095
          data-element=FD14_LongAccelerationFailSts_BSM, filter=data-filter-type=ALWAYS, init-value=0
          data-element=FD14_LongAccelerationOffset_BSM, filter=data-filter-type=ALWAYS, init-value=255
          data-element=FD14_LwsAngle, filter=data-filter-type=ALWAYS, init-value=0
          data-element=FD14_LwsAngleType, filter=data-filter-type=ALWAYS, init-value=0
          data-element=FD14_LwsSpeed, filter=data-filter-type=ALWAYS, init-value=0
          data-element=FD14_PAM_Brk_Rq_RspSts, filter=data-filter-type=ALWAYS, init-value=0
          data-element=FD14_ParkingGearShiftReq_BSM, filter=data-filter-type=ALWAYS, init-value=0
          data-element=FD14_ParkingInterventionSts, filter=data-filter-type=ALWAYS, init-value=0
          data-element=FD14_REF_VEH_SPEED, filter=data-filter-type=ALWAYS, init-value=1023
          data-element=FD14_RHF_FastPulseCounter, filter=data-filter-type=ALWAYS, init-value=0
          data-element=FD14_RHF_Spin, filter=data-filter-type=ALWAYS, init-value=0
          data-element=FD14_RHF_WheelSensorFailSts, filter=data-filter-type=ALWAYS, init-value=0
          data-element=FD14_RHFWheelSpeed, filter=data-filter-type=ALWAYS, init-value=0
          data-element=FD14_RHR_FastPulseCounter, filter=data-filter-type=ALWAYS, init-value=0
          data-element=FD14_RHR_Spin, filter=data-filter-type=ALWAYS, init-value=0
          data-element=FD14_RHR_WheelSensorFailSts, filter=data-filter-type=ALWAYS, init-value=0
          data-element=FD14_RHRWheelSpeed, filter=data-filter-type=ALWAYS, init-value=0
          data-element=FD14_Slope, filter=data-filter-type=ALWAYS, init-value=0
          data-element=FD14_SPM_Lat_Ctrl_ResponseSts, filter=data-filter-type=ALWAYS, init-value=0
          data-element=FD14_Steering_Column_Torque, filter=data-filter-type=ALWAYS, init-value=0
          data-element=FD14_VehicleSpeedVSOSig, filter=data-filter-type=ALWAYS, init-value=0
          data-element=FD14_VehicleSpeedVSOSig_B2, filter=data-filter-type=ALWAYS, init-value=0
          data-element=FD14_VehicleStandStillSts, filter=data-filter-type=ALWAYS, init-value=1
          data-element=FD14_YawRate_BSM, filter=data-filter-type=ALWAYS, init-value=4095
          data-element=FD14_YawRateFailSts_BSM, filter=data-filter-type=ALWAYS, init-value=0
          data-element=FD14_ESS_ENG_ST_W, filter=data-filter-type=ALWAYS
          data-element=FD14_EngineSts_W, filter=data-filter-type=ALWAYS
          data-element=FD14_ECM_TRSC_Resp, filter=data-filter-type=ALWAYS
          data-element=FD14_ECM_THA_Resp, filter=data-filter-type=ALWAYS
          data-element=FD14_PdlPosActual, filter=data-filter-type=ALWAYS
          data-element=FD14_THA_SteeringTouchStat, filter=data-filter-type=ALWAYS
          data-element=FD14_EPS_THA_SteeringTorqueResp, filter=data-filter-type=ALWAYS
          data-element=FD14_EPS_THA_DriverTorqueOverride, filter=data-filter-type=ALWAYS
          data-element=FD14_EPS_SteeringTouq_Resp, filter=data-filter-type=ALWAYS
          data-element=FD14_EPS_SteeringTouchStat, filter=data-filter-type=ALWAYS
      RpToSwcFD14Rx: required-interface=IF_FromComFD14Rx
        required-com-specs:
          data-element=FD14_Accel_Pedal_Override, filter=data-filter-type=ALWAYS, init-value=0
          data-element=FD14_DriverReq_AxleTrq_Enabled_BSM, filter=data-filter-type=ALWAYS, init-value=0
          data-element=FD14_PPPA_TrqEnblRq_Allowed, filter=data-filter-type=ALWAYS, init-value=0
      RpToSwcFD02Rx: required-interface=IF_FromComFD02Rx
        required-com-specs:
          data-element=Altitude_RMSE_C2, filter=data-filter-type=ALWAYS, init-value=255
          data-element=Battery_Volt_1, filter=data-filter-type=ALWAYS, init-value=0
          data-element=BSM_THA_Brk_Resp, filter=data-filter-type=ALWAYS, init-value=0
          data-element=CurrentCanNMState_FD01_BCM, filter=data-filter-type=ALWAYS, init-value=0
          data-element=CurrentCanNMState_FD01_SGW, filter=data-filter-type=ALWAYS, init-value=0
          data-element=CurrentCanNMState_FD02_BCM, filter=data-filter-type=ALWAYS, init-value=0
          data-element=CurrentCanNMState_FD02_BSM2, filter=data-filter-type=ALWAYS, init-value=0
          data-element=CurrentCanNMState_FD02_CADM2, filter=data-filter-type=ALWAYS, init-value=0
          data-element=CurrentCanNMState_FD02_EPS, filter=data-filter-type=ALWAYS, init-value=0
          data-element=CurrentCanNMState_FD02_ORC, filter=data-filter-type=ALWAYS, init-value=0
          data-element=CurrentCanNMState_FD02_SGW, filter=data-filter-type=ALWAYS, init-value=0
          data-element=CurrentCanNMState_FD02_TRLR_REV, filter=data-filter-type=ALWAYS, init-value=0
          data-element=CurrentCanNMState_FD03_BCM, filter=data-filter-type=ALWAYS, init-value=0
          data-element=CurrentCanNMState_FD03_SGW, filter=data-filter-type=ALWAYS, init-value=0
          data-element=CurrentCanNMState_FD04_BCM, filter=data-filter-type=ALWAYS, init-value=0
          data-element=CurrentCanNMState_FD08_SGW, filter=data-filter-type=ALWAYS, init-value=0
          data-element=CurrentCanNMState_FD11_SGW, filter=data-filter-type=ALWAYS, init-value=0
          data-element=CurrentFailSts_FD01_BCM, filter=data-filter-type=ALWAYS, init-value=0
          data-element=CurrentFailSts_FD01_SGW, filter=data-filter-type=ALWAYS, init-value=0
          data-element=CurrentFailSts_FD02_BCM, filter=data-filter-type=ALWAYS, init-value=0
          data-element=CurrentFailSts_FD02_BSM2, filter=data-filter-type=ALWAYS, init-value=0
          data-element=CurrentFailSts_FD02_CADM2, filter=data-filter-type=ALWAYS, init-value=0
          data-element=CurrentFailSts_FD02_EPS, filter=data-filter-type=ALWAYS, init-value=0
          data-element=CurrentFailSts_FD02_ORC, filter=data-filter-type=ALWAYS, init-value=0
          data-element=CurrentFailSts_FD02_SGW, filter=data-filter-type=ALWAYS, init-value=0
          data-element=CurrentFailSts_FD02_TRLR_REV, filter=data-filter-type=ALWAYS, init-value=0
          data-element=CurrentFailSts_FD03_BCM, filter=data-filter-type=ALWAYS, init-value=0
          data-element=CurrentFailSts_FD03_SGW, filter=data-filter-type=ALWAYS, init-value=0
          data-element=CurrentFailSts_FD04_BCM, filter=data-filter-type=ALWAYS, init-value=0
          data-element=CurrentFailSts_FD08_SGW, filter=data-filter-type=ALWAYS, init-value=0
          data-element=CurrentFailSts_FD11_SGW, filter=data-filter-type=ALWAYS, init-value=0
          data-element=DeltaTimestamp_IMUdata, filter=data-filter-type=ALWAYS, init-value=255
          data-element=DES_FD01_BCM, filter=data-filter-type=ALWAYS, init-value=0
          data-element=DES_FD01_SGW, filter=data-filter-type=ALWAYS, init-value=0
          data-element=DES_FD02_BCM, filter=data-filter-type=ALWAYS, init-value=0
          data-element=DES_FD02_BSM2, filter=data-filter-type=ALWAYS, init-value=0
          data-element=DES_FD02_CADM2, filter=data-filter-type=ALWAYS, init-value=0
          data-element=DES_FD02_EPS, filter=data-filter-type=ALWAYS, init-value=0
          data-element=DES_FD02_ORC, filter=data-filter-type=ALWAYS, init-value=0
          data-element=DES_FD02_SGW, filter=data-filter-type=ALWAYS, init-value=0
          data-element=DES_FD02_TRLR_REV, filter=data-filter-type=ALWAYS, init-value=0
          data-element=DES_FD03_BCM, filter=data-filter-type=ALWAYS, init-value=0
          data-element=DES_FD03_SGW, filter=data-filter-type=ALWAYS, init-value=0
          data-element=DES_FD04_BCM, filter=data-filter-type=ALWAYS, init-value=0
          data-element=DES_FD08_SGW, filter=data-filter-type=ALWAYS, init-value=0
          data-element=DES_FD11_SGW, filter=data-filter-type=ALWAYS, init-value=0
          data-element=Digit_{01..11}, filter=data-filter-type=ALWAYS, init-value=0
          data-element=EOL_FD01_BCM, filter=data-filter-type=ALWAYS, init-value=0
          data-element=EOL_FD01_SGW, filter=data-filter-type=ALWAYS, init-value=0
          data-element=EOL_FD02_BCM, filter=data-filter-type=ALWAYS, init-value=0
          data-element=EOL_FD02_BSM2, filter=data-filter-type=ALWAYS, init-value=0
          data-element=EOL_FD02_CADM2, filter=data-filter-type=ALWAYS, init-value=0
          data-element=EOL_FD02_EPS, filter=data-filter-type=ALWAYS, init-value=0
          data-element=EOL_FD02_ORC, filter=data-filter-type=ALWAYS, init-value=0
          data-element=EOL_FD02_SGW, filter=data-filter-type=ALWAYS, init-value=0
          data-element=EOL_FD02_TRLR_REV, filter=data-filter-type=ALWAYS, init-value=0
          data-element=EOL_FD03_BCM, filter=data-filter-type=ALWAYS, init-value=0
          data-element=EOL_FD03_SGW, filter=data-filter-type=ALWAYS, init-value=0
          data-element=EOL_FD04_BCM, filter=data-filter-type=ALWAYS, init-value=0
          data-element=EOL_FD08_SGW, filter=data-filter-type=ALWAYS, init-value=0
          data-element=EOL_FD11_SGW, filter=data-filter-type=ALWAYS, init-value=0
          data-element=EPBSts, filter=data-filter-type=ALWAYS, init-value=0
          data-element=GenericFailSts_FD01_BCM, filter=data-filter-type=ALWAYS, init-value=0
          data-element=GenericFailSts_FD01_SGW, filter=data-filter-type=ALWAYS, init-value=0
          data-element=GenericFailSts_FD02_BCM, filter=data-filter-type=ALWAYS, init-value=0
          data-element=GenericFailSts_FD02_BSM2, filter=data-filter-type=ALWAYS, init-value=0
          data-element=GenericFailSts_FD02_CADM2, filter=data-filter-type=ALWAYS, init-value=0
          data-element=GenericFailSts_FD02_EPS, filter=data-filter-type=ALWAYS, init-value=0
          data-element=GenericFailSts_FD02_ORC, filter=data-filter-type=ALWAYS, init-value=0
          data-element=GenericFailSts_FD02_SGW, filter=data-filter-type=ALWAYS, init-value=0
          data-element=GenericFailSts_FD02_TRLR_REV, filter=data-filter-type=ALWAYS, init-value=0
          data-element=GenericFailSts_FD03_BCM, filter=data-filter-type=ALWAYS, init-value=0
          data-element=GenericFailSts_FD03_SGW, filter=data-filter-type=ALWAYS, init-value=0
          data-element=GenericFailSts_FD04_BCM, filter=data-filter-type=ALWAYS, init-value=0
          data-element=GenericFailSts_FD08_SGW, filter=data-filter-type=ALWAYS, init-value=0
          data-element=GenericFailSts_FD11_SGW, filter=data-filter-type=ALWAYS, init-value=0
          data-element=Heading_Angle_C2, filter=data-filter-type=ALWAYS, init-value=65535
          data-element=IgnitionOnCounter, filter=data-filter-type=ALWAYS, init-value=0
          data-element=LatAcceleration_C2, filter=data-filter-type=ALWAYS, init-value=4095
          data-element=LatAccelerationOffset_BSM, filter=data-filter-type=ALWAYS, init-value=255
          data-element=Latitude_RMSE_C2, filter=data-filter-type=ALWAYS, init-value=255
          data-element=LHF_FastPulseCounter, filter=data-filter-type=ALWAYS, init-value=0
          data-element=LHF_Spin, filter=data-filter-type=ALWAYS, init-value=0
          data-element=LHFWheelSpeed, filter=data-filter-type=ALWAYS, init-value=0
          data-element=LHR_FastPulseCounter, filter=data-filter-type=ALWAYS, init-value=0
          data-element=LHR_Spin, filter=data-filter-type=ALWAYS, init-value=0
          data-element=LHRWheelSpeed, filter=data-filter-type=ALWAYS, init-value=0
          data-element=LongAcceleration_C2, filter=data-filter-type=ALWAYS, init-value=4095
          data-element=LongAccelerationOffset_BSM, filter=data-filter-type=ALWAYS, init-value=255
          data-element=Longitude_RMSE_C2, filter=data-filter-type=ALWAYS, init-value=255
          data-element=OperationalModeSts, filter=data-filter-type=ALWAYS, init-value=0
          data-element=Pitch_RMSE_C2, filter=data-filter-type=ALWAYS, init-value=255
          data-element=PitchRate_C2, filter=data-filter-type=ALWAYS, init-value=4095
          data-element=PreviousCanNMState_FD01_BCM, filter=data-filter-type=ALWAYS, init-value=0
          data-element=PreviousCanNMState_FD01_SGW, filter=data-filter-type=ALWAYS, init-value=0
          data-element=PreviousCanNMState_FD02_BCM, filter=data-filter-type=ALWAYS, init-value=0
          data-element=PreviousCanNMState_FD02_BSM2, filter=data-filter-type=ALWAYS, init-value=0
          data-element=PreviousCanNMState_FD02_CADM2, filter=data-filter-type=ALWAYS, init-value=0
          data-element=PreviousCanNMState_FD02_EPS, filter=data-filter-type=ALWAYS, init-value=0
          data-element=PreviousCanNMState_FD02_ORC, filter=data-filter-type=ALWAYS, init-value=0
          data-element=PreviousCanNMState_FD02_SGW, filter=data-filter-type=ALWAYS, init-value=0
          data-element=PreviousCanNMState_FD02_TRLR_REV, filter=data-filter-type=ALWAYS, init-value=0
          data-element=PreviousCanNMState_FD03_BCM, filter=data-filter-type=ALWAYS, init-value=0
          data-element=PreviousCanNMState_FD03_SGW, filter=data-filter-type=ALWAYS, init-value=0
          data-element=PreviousCanNMState_FD04_BCM, filter=data-filter-type=ALWAYS, init-value=0
          data-element=PreviousCanNMState_FD08_SGW, filter=data-filter-type=ALWAYS, init-value=0
          data-element=PreviousCanNMState_FD11_SGW, filter=data-filter-type=ALWAYS, init-value=0
          data-element=REF_VEH_SPEED, filter=data-filter-type=ALWAYS, init-value=1023
          data-element=RemStActvSts, filter=data-filter-type=ALWAYS, init-value=0
          data-element=RHF_FastPulseCounter, filter=data-filter-type=ALWAYS, init-value=0
          data-element=RHF_Spin, filter=data-filter-type=ALWAYS, init-value=0
          data-element=RHFWheelSpeed, filter=data-filter-type=ALWAYS, init-value=0
          data-element=RHR_FastPulseCounter, filter=data-filter-type=ALWAYS, init-value=0
          data-element=RHR_Spin, filter=data-filter-type=ALWAYS, init-value=0
          data-element=RHRWheelSpeed, filter=data-filter-type=ALWAYS, init-value=0
          data-element=Roll_RMSE_C2, filter=data-filter-type=ALWAYS, init-value=255
          data-element=RollRate_C2, filter=data-filter-type=ALWAYS, init-value=4095
          data-element=SBR1RowDriverSeatSts, filter=data-filter-type=ALWAYS, init-value=3
          data-element=StayActiveSource_FD01_BCM, filter=data-filter-type=ALWAYS, init-value=0
          data-element=StayActiveSource_FD01_SGW, filter=data-filter-type=ALWAYS, init-value=0
          data-element=StayActiveSource_FD02_BCM, filter=data-filter-type=ALWAYS, init-value=0
          data-element=StayActiveSource_FD02_BSM2, filter=data-filter-type=ALWAYS, init-value=0
          data-element=StayActiveSource_FD02_CADM2, filter=data-filter-type=ALWAYS, init-value=0
          data-element=StayActiveSource_FD02_EPS, filter=data-filter-type=ALWAYS, init-value=0
          data-element=StayActiveSource_FD02_ORC, filter=data-filter-type=ALWAYS, init-value=0
          data-element=StayActiveSource_FD02_SGW, filter=data-filter-type=ALWAYS, init-value=0
          data-element=StayActiveSource_FD02_TRLR_REV, filter=data-filter-type=ALWAYS, init-value=0
          data-element=StayActiveSource_FD03_BCM, filter=data-filter-type=ALWAYS, init-value=0
          data-element=StayActiveSource_FD03_SGW, filter=data-filter-type=ALWAYS, init-value=0
          data-element=StayActiveSource_FD04_BCM, filter=data-filter-type=ALWAYS, init-value=0
          data-element=StayActiveSource_FD08_SGW, filter=data-filter-type=ALWAYS, init-value=0
          data-element=StayActiveSource_FD11_SGW, filter=data-filter-type=ALWAYS, init-value=0
          data-element=TotalOdometer, filter=data-filter-type=ALWAYS, init-value=0
          data-element=TRSC_CenterBtn_Sts, filter=data-filter-type=ALWAYS, init-value=0
          data-element=TRSC_EnableBtn_Sts, filter=data-filter-type=ALWAYS, init-value=0
          data-element=TRSC_RawKnob, filter=data-filter-type=ALWAYS, init-value=0
          data-element=TurnIndicatorSts, filter=data-filter-type=ALWAYS, init-value=0
          data-element=VehicleStandStillSts, filter=data-filter-type=ALWAYS, init-value=1
          data-element=VerticalAcceleration_C2, filter=data-filter-type=ALWAYS, init-value=4095
          data-element=WakeupSource_FD01_ADCM, filter=data-filter-type=ALWAYS, init-value=0
          data-element=WakeupSource_FD01_BCM, filter=data-filter-type=ALWAYS, init-value=0
          data-element=WakeupSource_FD01_SGW, filter=data-filter-type=ALWAYS, init-value=0
          data-element=WakeupSource_FD02_BCM, filter=data-filter-type=ALWAYS, init-value=0
          data-element=WakeupSource_FD02_BSM2, filter=data-filter-type=ALWAYS, init-value=0
          data-element=WakeupSource_FD02_CADM2, filter=data-filter-type=ALWAYS, init-value=0
          data-element=WakeupSource_FD02_EPS, filter=data-filter-type=ALWAYS, init-value=0
          data-element=WakeupSource_FD02_ORC, filter=data-filter-type=ALWAYS, init-value=0
          data-element=WakeupSource_FD02_SGW, filter=data-filter-type=ALWAYS, init-value=0
          data-element=WakeupSource_FD02_TRLR_REV, filter=data-filter-type=ALWAYS, init-value=0
          data-element=WakeupSource_FD03_BCM, filter=data-filter-type=ALWAYS, init-value=0
          data-element=WakeupSource_FD03_SGW, filter=data-filter-type=ALWAYS, init-value=0
          data-element=WakeupSource_FD04_BCM, filter=data-filter-type=ALWAYS, init-value=0
          data-element=WakeupSource_FD08_SGW, filter=data-filter-type=ALWAYS, init-value=0
          data-element=WakeupSource_FD11_SGW, filter=data-filter-type=ALWAYS, init-value=0
          data-element=YawRate_C2, filter=data-filter-type=ALWAYS, init-value=4095
          data-element=YawRate_RMSE_C2, filter=data-filter-type=ALWAYS, init-value=255
    provide port DataServices_Data_225107_Front_Sensor_HealthBlockage_LiveDetection_Check_Read: server-com-spec{operation=ReadData, queue-length=1}, provided-interface=DataServices_Data_225107_Front_Sensor_HealthBlockage_LiveDetection_Check_Read
    provide port DataServices_Data_225109_Rear_Sensor_HealthBlockage_LiveDetection_Check_Read: server-com-spec{operation=ReadData, queue-length=1}, provided-interface=DataServices_Data_225109_Rear_Sensor_HealthBlockage_LiveDetection_Check_Read
    provide port DataServices_Data_22FD4A_Ultrasonic_Sensors_Power_supply_and_Current_Level_Read: server-com-spec{operation=ReadData, queue-length=1}, provided-interface=DataServices_Data_22FD4A_Ultrasonic_Sensors_Power_supply_and_Current_Level_Read
    8 x require port:
      RpToSwcFD02Tx: required-interface=IF_ToSwcFD02Tx
        required-com-specs:
          data-element=CurrentCanNMState_FD02_PAM, filter=data-filter-type=ALWAYS, init-value=0
          data-element=CurrentFailSts_FD02_PAM, filter=data-filter-type=ALWAYS, init-value=0
          data-element=DES_FD02_PAM, filter=data-filter-type=ALWAYS, init-value=0
          data-element=Digit_{01..11}_PAM, filter=data-filter-type=ALWAYS, init-value=0
          data-element=EOL_FD02_PAM, filter=data-filter-type=ALWAYS, init-value=0
          data-element=GenericFailSts_FD02_PAM, filter=data-filter-type=ALWAYS, init-value=0
          {data-element=N_PDU, filter=data-filter-type=ALWAYS, init-value=[rule-based-values={rule=FILL_UNTIL_END, rule-arguments=0}]}
          data-element=PreviousCanNMState_FD02_PAM, filter=data-filter-type=ALWAYS, init-value=0
          {data-element=StayActiveSource_FD02_PAM, filter=data-filter-type=ALWAYS, init-value=[rule-based-values={rule=FILL_UNTIL_END, rule-arguments=0}]}
          data-element=THA_EPB_Req, filter=data-filter-type=ALWAYS, init-value=0
          data-element=THA_Speed_Limit, filter=data-filter-type=ALWAYS, init-value=0
          data-element=THA_SpeedLimit_Req, filter=data-filter-type=ALWAYS, init-value=0
          data-element=THA_STAT, filter=data-filter-type=ALWAYS, init-value=0
          data-element=THA_SteeringDamping, filter=data-filter-type=ALWAYS, init-value=78.125
          data-element=THA_SteeringTorqueInfo, filter=data-filter-type=ALWAYS, init-value=0
          data-element=THA_SteeringTorqueReq, filter=data-filter-type=ALWAYS, init-value=0
          data-element=Trailer_Angle, filter=data-filter-type=ALWAYS, init-value=0
          data-element=Trailer_Angle_Sign, filter=data-filter-type=ALWAYS, init-value=0
          data-element=Trailer_Calibration, filter=data-filter-type=ALWAYS, init-value=0
          data-element=TrlrHitchLight_Cntrl, filter=data-filter-type=ALWAYS, init-value=0
          data-element=TRSC_PopupDisp_Info, filter=data-filter-type=ALWAYS, init-value=0
          data-element=TRSC_SpeedLimit_Req, filter=data-filter-type=ALWAYS, init-value=0
          data-element=TRSC_STAT, filter=data-filter-type=ALWAYS, init-value=1
          data-element=TRSC_SteeringDamping, filter=data-filter-type=ALWAYS, init-value=100
          data-element=TRSC_SteeringTorqueInfo, filter=data-filter-type=ALWAYS, init-value=0
          data-element=TRSC_SteeringTorqueReq, filter=data-filter-type=ALWAYS, init-value=0
          data-element=TRSC_VehicleStop_Req, filter=data-filter-type=ALWAYS, init-value=3
          data-element=TRSCMoreCamRQSts, filter=data-filter-type=ALWAYS, init-value=0
          data-element=WakeupSource_FD02_PAM, filter=data-filter-type=ALWAYS, init-value=0
          data-element=TRSC_PopupDisp_Info2, filter=data-filter-type=ALWAYS, init-value=0
      RpToSwcFD14Tx: required-interface=IF_ToSwcFD14Tx
        required-com-specs:
          data-element=FD14_TRSC_VehicleStop_Req, filter=data-filter-type=ALWAYS
          data-element=FD14_TRSC_SteeringTorqueReq, filter=data-filter-type=ALWAYS
          data-element=FD14_TRSC_SteeringTorqueInfo, filter=data-filter-type=ALWAYS
          data-element=FD14_TRSC_SteeringDamping, filter=data-filter-type=ALWAYS
          data-element=FD14_TRSC_STAT, filter=data-filter-type=ALWAYS
          data-element=FD14_TRSC_SpeedLimit_Req, filter=data-filter-type=ALWAYS
          data-element=FD14_THA_SteeringTorqueReq, filter=data-filter-type=ALWAYS
          data-element=FD14_THA_SteeringTorqueInfo, filter=data-filter-type=ALWAYS
          data-element=FD14_THA_SteeringDamping, filter=data-filter-type=ALWAYS
          data-element=FD14_THA_STAT, filter=data-filter-type=ALWAYS
          data-element=FD14_THA_SpeedLimit_Req, filter=data-filter-type=ALWAYS
          data-element=FD14_THA_Speed_Limit, filter=data-filter-type=ALWAYS
          data-element=FD14_THA_EPB_Req, filter=data-filter-type=ALWAYS
      RpToSwcSafeFD02Tx: required-interface=IF_ToSwcSafeFD02Tx
        required-com-specs:
          data-element=TRSC_LED_Stat, filter=data-filter-type=ALWAYS
          data-element=SPMSystemFault, filter=data-filter-type=ALWAYS
          data-element=SPMFailSts, filter=data-filter-type=ALWAYS
          data-element=SPMControlSts, filter=data-filter-type=ALWAYS
          data-element=SPM_Screen_Rqst, filter=data-filter-type=ALWAYS
          data-element=SPM_LedControlSts, filter=data-filter-type=ALWAYS
          data-element=RR_PAM_StopControlSts, filter=data-filter-type=ALWAYS
          data-element=RR_PAM_Dist, filter=data-filter-type=ALWAYS
          data-element=RR_PAM_Brk_RqSts, filter=data-filter-type=ALWAYS
          data-element=RearSensorSts, filter=data-filter-type=ALWAYS
          data-element=PPPA_TurnIndicatorRqst, filter=data-filter-type=ALWAYS
          data-element=ParkingManeuverActive, filter=data-filter-type=ALWAYS
          data-element=PAMSystemFault, filter=data-filter-type=ALWAYS
          data-element=PAM_Volume, filter=data-filter-type=ALWAYS
          data-element=PAM_PopUpRqst, filter=data-filter-type=ALWAYS
          data-element=PAM_Off_Status_2BT, filter=data-filter-type=ALWAYS
          data-element=PAM_Off_Status, filter=data-filter-type=ALWAYS
          data-element=PAM_LedControlSts, filter=data-filter-type=ALWAYS
          data-element=PAM_CHIME_TYPE, filter=data-filter-type=ALWAYS
          data-element=PAM_CHIME_REP_RATESts, filter=data-filter-type=ALWAYS
          data-element=MoreCamsRQSts, filter=data-filter-type=ALWAYS
          data-element=ImageDefeatRQSts, filter=data-filter-type=ALWAYS
          data-element=HMICode, filter=data-filter-type=ALWAYS
          data-element=Graphic_RHR, filter=data-filter-type=ALWAYS
          data-element=Graphic_RHF, filter=data-filter-type=ALWAYS
          data-element=Graphic_LHR, filter=data-filter-type=ALWAYS
          data-element=Graphic_LHF, filter=data-filter-type=ALWAYS
          data-element=Graphic_CHR, filter=data-filter-type=ALWAYS
          data-element=Graphic_CHF, filter=data-filter-type=ALWAYS
          data-element=FT_PAM_LedControlSts, filter=data-filter-type=ALWAYS
          data-element=FrontSensorSts, filter=data-filter-type=ALWAYS
          data-element=DisplayView2, filter=data-filter-type=ALWAYS
          data-element=ChimeActivation_RHR, filter=data-filter-type=ALWAYS
          data-element=ChimeActivation_RHF, filter=data-filter-type=ALWAYS
          data-element=ChimeActivation_LHR, filter=data-filter-type=ALWAYS
          data-element=ChimeActivation_LHF, filter=data-filter-type=ALWAYS
          data-element=AUXCamsRQSts, filter=data-filter-type=ALWAYS
          data-element=Alert_RHR, filter=data-filter-type=ALWAYS
          data-element=Alert_RHF, filter=data-filter-type=ALWAYS
          data-element=Alert_LHR, filter=data-filter-type=ALWAYS
          data-element=Alert_LHF, filter=data-filter-type=ALWAYS
          data-element=Alert_CHR, filter=data-filter-type=ALWAYS
          data-element=Alert_CHF, filter=data-filter-type=ALWAYS
          data-element=MAC_ADAS_FD_LANES_2, filter=data-filter-type=ALWAYS
          data-element=MAC_ADAS_FD_LANES_1, filter=data-filter-type=ALWAYS
          data-element=Line_4_Type, filter=data-filter-type=ALWAYS
          data-element=Line_4_Start_Range, filter=data-filter-type=ALWAYS
          data-element=Line_4_Offset, filter=data-filter-type=ALWAYS
          data-element=Line_4_Heading, filter=data-filter-type=ALWAYS
          data-element=Line_4_End_Range, filter=data-filter-type=ALWAYS
          data-element=Line_4_Curvature_Rate, filter=data-filter-type=ALWAYS
          data-element=Line_4_Curvature, filter=data-filter-type=ALWAYS
          data-element=Line_4_Confidence, filter=data-filter-type=ALWAYS
          data-element=Line_3_Type, filter=data-filter-type=ALWAYS
          data-element=Line_3_Start_Range, filter=data-filter-type=ALWAYS
          data-element=Line_3_Offset, filter=data-filter-type=ALWAYS
          data-element=Line_3_Heading, filter=data-filter-type=ALWAYS
          data-element=Line_3_End_Range, filter=data-filter-type=ALWAYS
          data-element=Line_3_Curvature_Rate, filter=data-filter-type=ALWAYS
          data-element=Line_3_Curvature, filter=data-filter-type=ALWAYS
          data-element=Line_3_Confidence, filter=data-filter-type=ALWAYS
          data-element=Line_2_Type, filter=data-filter-type=ALWAYS
          data-element=Line_2_Start_Range, filter=data-filter-type=ALWAYS
          data-element=Line_2_Offset, filter=data-filter-type=ALWAYS
          data-element=Line_2_Heading, filter=data-filter-type=ALWAYS
          data-element=Line_2_End_Range, filter=data-filter-type=ALWAYS
          data-element=Line_2_Curvature_Rate, filter=data-filter-type=ALWAYS
          data-element=Line_2_Curvature, filter=data-filter-type=ALWAYS
          data-element=Line_2_Confidence, filter=data-filter-type=ALWAYS
          data-element=Line_1_Type, filter=data-filter-type=ALWAYS
          data-element=Line_1_Start_Range, filter=data-filter-type=ALWAYS
          data-element=Line_1_Offset, filter=data-filter-type=ALWAYS
          data-element=Line_1_Heading, filter=data-filter-type=ALWAYS
          data-element=Line_1_End_Range, filter=data-filter-type=ALWAYS
          data-element=Line_1_Curvature_Rate, filter=data-filter-type=ALWAYS
          data-element=Line_1_Curvature, filter=data-filter-type=ALWAYS
          data-element=Line_1_Confidence, filter=data-filter-type=ALWAYS
          data-element=Health_Lane_Detection, filter=data-filter-type=ALWAYS
          data-element=Health_Front_Object_Detection, filter=data-filter-type=ALWAYS
          data-element=Frame_Index_Lanes_2, filter=data-filter-type=ALWAYS
          data-element=Frame_Index_Lanes_1, filter=data-filter-type=ALWAYS
          data-element=FOD_Confidence, filter=data-filter-type=ALWAYS
          data-element=Cntr_ADAS_FD_LANES_2, filter=data-filter-type=ALWAYS
          data-element=Cntr_ADAS_FD_LANES_1, filter=data-filter-type=ALWAYS
          data-element=Camera_Status, filter=data-filter-type=ALWAYS
          data-element=Segment_8_Y2, filter=data-filter-type=ALWAYS
          data-element=Segment_8_Y1, filter=data-filter-type=ALWAYS
          data-element=Segment_8_X2, filter=data-filter-type=ALWAYS
          data-element=Segment_8_X1, filter=data-filter-type=ALWAYS
          data-element=Segment_8_ID, filter=data-filter-type=ALWAYS
          data-element=Segment_8_Confidence, filter=data-filter-type=ALWAYS
          data-element=Segment_7_Y2, filter=data-filter-type=ALWAYS
          data-element=Segment_7_Y1, filter=data-filter-type=ALWAYS
          data-element=Segment_7_X2, filter=data-filter-type=ALWAYS
          data-element=Segment_7_X1, filter=data-filter-type=ALWAYS
          data-element=Segment_7_ID, filter=data-filter-type=ALWAYS
          data-element=Segment_7_Confidence, filter=data-filter-type=ALWAYS
          data-element=Segment_6_Y2, filter=data-filter-type=ALWAYS
          data-element=Segment_6_Y1, filter=data-filter-type=ALWAYS
          data-element=Segment_6_X2, filter=data-filter-type=ALWAYS
          data-element=Segment_6_X1, filter=data-filter-type=ALWAYS
          data-element=Segment_6_ID, filter=data-filter-type=ALWAYS
          data-element=Segment_6_Confidence, filter=data-filter-type=ALWAYS
          data-element=Segment_5_Y2, filter=data-filter-type=ALWAYS
          data-element=Segment_5_Y1, filter=data-filter-type=ALWAYS
          data-element=Segment_5_X2, filter=data-filter-type=ALWAYS
          data-element=Segment_5_X1, filter=data-filter-type=ALWAYS
          data-element=Segment_5_ID, filter=data-filter-type=ALWAYS
          data-element=Segment_5_Confidence, filter=data-filter-type=ALWAYS
          data-element=Segment_4_Y2, filter=data-filter-type=ALWAYS
          data-element=Segment_4_Y1, filter=data-filter-type=ALWAYS
          data-element=Segment_4_X2, filter=data-filter-type=ALWAYS
          data-element=Segment_4_X1, filter=data-filter-type=ALWAYS
          data-element=Segment_4_ID, filter=data-filter-type=ALWAYS
          data-element=Segment_4_Confidence, filter=data-filter-type=ALWAYS
          data-element=Segment_3_Y2, filter=data-filter-type=ALWAYS
          data-element=Segment_3_Y1, filter=data-filter-type=ALWAYS
          data-element=Segment_3_X2, filter=data-filter-type=ALWAYS
          data-element=Segment_3_X1, filter=data-filter-type=ALWAYS
          data-element=Segment_3_ID, filter=data-filter-type=ALWAYS
          data-element=Segment_3_Confidence, filter=data-filter-type=ALWAYS
          data-element=Segment_2_Y2, filter=data-filter-type=ALWAYS
          data-element=Segment_2_Y1, filter=data-filter-type=ALWAYS
          data-element=Segment_2_X2, filter=data-filter-type=ALWAYS
          data-element=Segment_2_X1, filter=data-filter-type=ALWAYS
          data-element=Segment_2_ID, filter=data-filter-type=ALWAYS
          data-element=Segment_2_Confidence, filter=data-filter-type=ALWAYS
          data-element=Segment_1_Y2, filter=data-filter-type=ALWAYS
          data-element=Segment_1_Y1, filter=data-filter-type=ALWAYS
          data-element=Segment_1_X2, filter=data-filter-type=ALWAYS
          data-element=Segment_1_X1, filter=data-filter-type=ALWAYS
          data-element=Segment_1_ID, filter=data-filter-type=ALWAYS
          data-element=Segment_1_Confidence, filter=data-filter-type=ALWAYS
          data-element=Reserved_for_functional_safety, filter=data-filter-type=ALWAYS
      RpToSwcSafeFD14Tx: required-interface=IF_ToSwcSafeFD14Tx
        required-com-specs:
          data-element=FD14_TorqueOverlaySteeringReq_SPM, filter=data-filter-type=ALWAYS
          data-element=FD14_SPM_Lat_Ctrl_RequestSts, filter=data-filter-type=ALWAYS
          data-element=FD14_RR_PAM_Dist, filter=data-filter-type=ALWAYS
          data-element=FD14_RR_PAM_Brk_RqSts, filter=data-filter-type=ALWAYS
          data-element=FD14_PPPA_TargetDistance, filter=data-filter-type=ALWAYS
          data-element=FD14_PPPA_StandstillRqst, filter=data-filter-type=ALWAYS
          data-element=FD14_PPPA_MaxSpeed, filter=data-filter-type=ALWAYS
          data-element=FD14_PPPA_JerkDecelMin, filter=data-filter-type=ALWAYS
          data-element=FD14_PPPA_JerkDecelMax, filter=data-filter-type=ALWAYS
          data-element=FD14_PPPA_JerkAccelMin, filter=data-filter-type=ALWAYS
          data-element=FD14_PPPA_JerkAccelMax, filter=data-filter-type=ALWAYS
          data-element=FD14_PPPA_Interface_BSM, filter=data-filter-type=ALWAYS
          data-element=FD14_PPPA_DecelMin, filter=data-filter-type=ALWAYS
          data-element=FD14_PPPA_DecelMax, filter=data-filter-type=ALWAYS
          data-element=FD14_PPPA_AccelMin, filter=data-filter-type=ALWAYS
          data-element=FD14_PPPA_AccelMax, filter=data-filter-type=ALWAYS
          data-element=FD14_ParkingGearShiftReq, filter=data-filter-type=ALWAYS
          data-element=FD14_ManoeuvrePhase, filter=data-filter-type=ALWAYS
          data-element=FD14_Segment_8_Y2, filter=data-filter-type=ALWAYS
          data-element=FD14_Segment_8_Y1, filter=data-filter-type=ALWAYS
          data-element=FD14_Segment_8_X2, filter=data-filter-type=ALWAYS
          data-element=FD14_Segment_8_X1, filter=data-filter-type=ALWAYS
          data-element=FD14_Segment_8_ID, filter=data-filter-type=ALWAYS
          data-element=FD14_Segment_8_Confidence, filter=data-filter-type=ALWAYS
          data-element=FD14_Segment_7_Y2, filter=data-filter-type=ALWAYS
          data-element=FD14_Segment_7_Y1, filter=data-filter-type=ALWAYS
          data-element=FD14_Segment_7_X2, filter=data-filter-type=ALWAYS
          data-element=FD14_Segment_7_X1, filter=data-filter-type=ALWAYS
          data-element=FD14_Segment_7_ID, filter=data-filter-type=ALWAYS
          data-element=FD14_Segment_7_Confidence, filter=data-filter-type=ALWAYS
          data-element=FD14_Segment_6_Y2, filter=data-filter-type=ALWAYS
          data-element=FD14_Segment_6_Y1, filter=data-filter-type=ALWAYS
          data-element=FD14_Segment_6_X2, filter=data-filter-type=ALWAYS
          data-element=FD14_Segment_6_X1, filter=data-filter-type=ALWAYS
          data-element=FD14_Segment_6_ID, filter=data-filter-type=ALWAYS
          data-element=FD14_Segment_6_Confidence, filter=data-filter-type=ALWAYS
          data-element=FD14_Segment_5_Y2, filter=data-filter-type=ALWAYS
          data-element=FD14_Segment_5_Y1, filter=data-filter-type=ALWAYS
          data-element=FD14_Segment_5_X2, filter=data-filter-type=ALWAYS
          data-element=FD14_Segment_5_X1, filter=data-filter-type=ALWAYS
          data-element=FD14_Segment_5_ID, filter=data-filter-type=ALWAYS
          data-element=FD14_Segment_5_Confidence, filter=data-filter-type=ALWAYS
          data-element=FD14_Segment_4_Y2, filter=data-filter-type=ALWAYS
          data-element=FD14_Segment_4_Y1, filter=data-filter-type=ALWAYS
          data-element=FD14_Segment_4_X2, filter=data-filter-type=ALWAYS
          data-element=FD14_Segment_4_X1, filter=data-filter-type=ALWAYS
          data-element=FD14_Segment_4_ID, filter=data-filter-type=ALWAYS
          data-element=FD14_Segment_4_Confidence, filter=data-filter-type=ALWAYS
          data-element=FD14_Segment_3_Y2, filter=data-filter-type=ALWAYS
          data-element=FD14_Segment_3_Y1, filter=data-filter-type=ALWAYS
          data-element=FD14_Segment_3_X2, filter=data-filter-type=ALWAYS
          data-element=FD14_Segment_3_X1, filter=data-filter-type=ALWAYS
          data-element=FD14_Segment_3_ID, filter=data-filter-type=ALWAYS
          data-element=FD14_Segment_3_Confidence, filter=data-filter-type=ALWAYS
          data-element=FD14_Segment_2_Y2, filter=data-filter-type=ALWAYS
          data-element=FD14_Segment_2_Y1, filter=data-filter-type=ALWAYS
          data-element=FD14_Segment_2_X2, filter=data-filter-type=ALWAYS
          data-element=FD14_Segment_2_X1, filter=data-filter-type=ALWAYS
          data-element=FD14_Segment_2_ID, filter=data-filter-type=ALWAYS
          data-element=FD14_Segment_2_Confidence, filter=data-filter-type=ALWAYS
          data-element=FD14_Segment_1_Y2, filter=data-filter-type=ALWAYS
          data-element=FD14_Segment_1_Y1, filter=data-filter-type=ALWAYS
          data-element=FD14_Segment_1_X2, filter=data-filter-type=ALWAYS
          data-element=FD14_Segment_1_X1, filter=data-filter-type=ALWAYS
          data-element=FD14_Segment_1_ID, filter=data-filter-type=ALWAYS
          data-element=FD14_Segment_1_Confidence, filter=data-filter-type=ALWAYS
          data-element=FD14_Reserved_for_functional_safety, filter=data-filter-type=ALWAYS
          data-element=FD14_ParkingManeuverActive, filter=data-filter-type=ALWAYS
          data-element=FD14_MAC_ADAS_FD_LANES_2, filter=data-filter-type=ALWAYS
          data-element=FD14_MAC_ADAS_FD_LANES_1, filter=data-filter-type=ALWAYS
          data-element=FD14_Line_4_Type, filter=data-filter-type=ALWAYS
          data-element=FD14_Line_4_Start_Range, filter=data-filter-type=ALWAYS
          data-element=FD14_Line_4_Offset, filter=data-filter-type=ALWAYS
          data-element=FD14_Line_4_Heading, filter=data-filter-type=ALWAYS
          data-element=FD14_Line_4_End_Range, filter=data-filter-type=ALWAYS
          data-element=FD14_Line_4_Curvature_Rate, filter=data-filter-type=ALWAYS
          data-element=FD14_Line_4_Curvature, filter=data-filter-type=ALWAYS
          data-element=FD14_Line_4_Confidence, filter=data-filter-type=ALWAYS
          data-element=FD14_Line_3_Type, filter=data-filter-type=ALWAYS
          data-element=FD14_Line_3_Start_Range, filter=data-filter-type=ALWAYS
          data-element=FD14_Line_3_Offset, filter=data-filter-type=ALWAYS
          data-element=FD14_Line_3_Heading, filter=data-filter-type=ALWAYS
          data-element=FD14_Line_3_End_Range, filter=data-filter-type=ALWAYS
          data-element=FD14_Line_3_Curvature_Rate, filter=data-filter-type=ALWAYS
          data-element=FD14_Line_3_Curvature, filter=data-filter-type=ALWAYS
          data-element=FD14_Line_3_Confidence, filter=data-filter-type=ALWAYS
          data-element=FD14_Line_2_Type, filter=data-filter-type=ALWAYS
          data-element=FD14_Line_2_Start_Range, filter=data-filter-type=ALWAYS
          data-element=FD14_Line_2_Offset, filter=data-filter-type=ALWAYS
          data-element=FD14_Line_2_Heading, filter=data-filter-type=ALWAYS
          data-element=FD14_Line_2_End_Range, filter=data-filter-type=ALWAYS
          data-element=FD14_Line_2_Curvature_Rate, filter=data-filter-type=ALWAYS
          data-element=FD14_Line_2_Curvature, filter=data-filter-type=ALWAYS
          data-element=FD14_Line_2_Confidence, filter=data-filter-type=ALWAYS
          data-element=FD14_Line_1_Type, filter=data-filter-type=ALWAYS
          data-element=FD14_Line_1_Start_Range, filter=data-filter-type=ALWAYS
          data-element=FD14_Line_1_Offset, filter=data-filter-type=ALWAYS
          data-element=FD14_Line_1_Heading, filter=data-filter-type=ALWAYS
          data-element=FD14_Line_1_End_Range, filter=data-filter-type=ALWAYS
          data-element=FD14_Line_1_Curvature_Rate, filter=data-filter-type=ALWAYS
          data-element=FD14_Line_1_Curvature, filter=data-filter-type=ALWAYS
          data-element=FD14_Line_1_Confidence, filter=data-filter-type=ALWAYS
          data-element=FD14_Health_Lane_Detection, filter=data-filter-type=ALWAYS
          data-element=FD14_Health_Front_Object_Detection, filter=data-filter-type=ALWAYS
          data-element=FD14_Frame_Index_Lanes_2, filter=data-filter-type=ALWAYS
          data-element=FD14_Frame_Index_Lanes_1, filter=data-filter-type=ALWAYS
          data-element=FD14_FOD_Confidence, filter=data-filter-type=ALWAYS
          data-element=FD14_Cntr_ADAS_FD_LANES_2, filter=data-filter-type=ALWAYS
          data-element=FD14_Cntr_ADAS_FD_LANES_1, filter=data-filter-type=ALWAYS
          data-element=FD14_Camera_Status, filter=data-filter-type=ALWAYS
      RpMEProxi: nonqueued-receiver-com-spec{data-element=ME_Proxi_MPU1_0_to_MCU1_0_t, filter=data-filter-type=ALWAYS}, required-interface=IF_MEProxi
      RpIpcTxData: client-com-spec=IPC_Write_v, required-interface=IF_IpcTxData
      RpCamSerENStat: nonqueued-receiver-com-spec{data-element=Cam_and_Ser_EN_Status_t, filter=data-filter-type=ALWAYS}, required-interface=IF_CamSerENStat
      RpClearDTCSettingStatus: client-com-spec=ClearDTCSettingStatus, required-interface=IF_ClearDTCSettingStatus
    provide port DataServices_Data_22FD65_FuSa_Module_Status_Read: server-com-spec{operation=ReadData, queue-length=1}, provided-interface=DataServices_Data_22FD65_FuSa_Module_Status_Read
    4 x require port:
      RpMPUFaultStatus: nonqueued-receiver-com-spec{data-element=Sts, filter=data-filter-type=ALWAYS, init-value=[0, 0]}, required-interface=IF_MPUFaultStatus
      RpSDLFaultstatus: nonqueued-receiver-com-spec{data-element=Sts, filter=data-filter-type=ALWAYS, init-value=14 x 0}, required-interface=IF_SDLFaultstatus
      RpPMICFaultstatus: nonqueued-receiver-com-spec{data-element=Sts, filter=data-filter-type=ALWAYS, init-value=8 x 0}, required-interface=IF_PMICFaultstatus
      RpWDGFaultStatus: nonqueued-receiver-com-spec{data-element=Sts, filter=data-filter-type=ALWAYS, init-value=[0, 0]}, required-interface=IF_WDGFaultStatus
    provide port Pp_NVM_Write_ProxiConfigTable: server-com-spec{operation=ProxiconfigTable_Nvm_write_confirmation, queue-length=1}, provided-interface=IF_NVM_Write_ProxiConfigTable
    require port RpErrors_B: nonqueued-receiver-com-spec{data-element=Errors_B, init-value=constant-reference=init_Errors_B}, required-interface=P_Errors_B_SR
    require port RpErrors_QM: nonqueued-receiver-com-spec{data-element=Errors_QM, init-value=constant-reference=init_Errors_QM}, required-interface=P_Errors_QM_SR
    require port RpSecureAuthenticationStatus: client-com-spec=Get_ADAStatus, required-interface=IF_SecureAuthenticationStatus
    5 x provide port:
      PpFailsafeAction: nonqueued-sender-com-spec{data-element=FailSafe_State, init-value=0}, provided-interface=IF_FailsafeAction
      DataServices_Data_22FD43_Active_Safe_State_Read: server-com-spec{operation=ReadData, queue-length=1}, provided-interface=DataServices_Data_22FD43_Active_Safe_State_Read
      DataServices_Data_22FD44_Error_Flags_Read: server-com-spec{operation=ReadData, queue-length=1}, provided-interface=DataServices_Data_22FD44_Error_Flags_Read
      DataServices_Data_22FD66_Camera_occlusion_and_low_light_status_Read: server-com-spec{operation=ReadData, queue-length=1}, provided-interface=DataServices_Data_22FD66_Camera_occlusion_and_low_light_status_Read
      DataServices_Data_22FD67_Camera_DLD_Status_Read: server-com-spec{operation=ReadData, queue-length=1}, provided-interface=DataServices_Data_22FD67_Camera_DLD_Status_Read
    require port Rp_DLDOutput: nonqueued-receiver-com-spec{data-element=JobDLDOutput_t, filter=data-filter-type=ALWAYS, init-value=fields=[IeDLD_e_FrCamSts:0, IeDLD_e_RrCamSts:0, IeDLD_e_RyCamSts:0, IeDLD_e_LyCamSts:0, IeDLD_p_FrCamOcclnPerc:0, IeDLD_p_FrCamLoLumPerc:0, IeDLD_p_RrCamOcclnPerc:0, IeDLD_p_RrCamLoLumPerc:0, IeDLD_p_LyCamOcclnPerc:0, IeDLD_p_LyCamLoLumPerc:0, IeDLD_p_RyCamOcclnPerc:0, IeDLD_p_RyCamLoLumPerc:0, IeDLD_b_FrCamOcclnSts:0, IeDLD_b_FrCamLoLumSts:0, IeDLD_b_RrCamOcclnSts:0, IeDLD_b_RrCamLoLumSts:0, IeDLD_b_LyCamOcclnSts:0, IeDLD_b_LyCamLoLumSts:0, IeDLD_b_RyCamOcclnSts:0, IeDLD_b_RyCamLoLumSts:0]}, required-interface=IF_DLDOutput
    require port RpSafeState2RSTReason: nonqueued-receiver-com-spec{data-element=FaultEnum_u16, filter=data-filter-type=ALWAYS, init-value=0}, required-interface=IF_SafeState2Reason
    require port Rp_SafeState_SR: nonqueued-receiver-com-spec{data-element=SafeStateOp, filter=data-filter-type=ALWAYS, init-value=constant-reference=init_SafeStateOp}, required-interface=P_SafeState_SR
    provide port PpResetNvmFlag: nonqueued-sender-com-spec{data-element=V_ResetNvmFlag_b, init-value=0}, provided-interface=IF_ResetNvmFlag
    require port NvMService_AC3_SRBS_DID_FD74_PHY_TuningErr: required-com-specs=[WriteBlock, SetRamBlockStatus, ReadBlock, InvalidateNvBlock, GetErrorStatus, EraseBlock], required-interface=NvMService_AC3_SRBS
    require port NvMService_AC3_SRBS_DID_FD74_BuffMarkCompErr: required-com-specs=[WriteBlock, SetRamBlockStatus, ReadBlock, InvalidateNvBlock, GetErrorStatus, EraseBlock], required-interface=NvMService_AC3_SRBS
    provide port DataServices_Data_22FD74_PHY_Tunning_Error_And_Buffer_Mark_Error_Read: server-com-spec{operation=ReadData, queue-length=1}, provided-interface=DataServices_Data_22FD74_PHY_Tunning_Error_And_Buffer_Mark_Error_Read
    require port RpVIN_MessageFault: required-interface=IF_VIN_MessageFault
      required-com-specs:
        data-element=VIN_InvalidValueFlag, filter=data-filter-type=ALWAYS, init-value=0
        data-element=VIN_MissingMessageFlag, filter=data-filter-type=ALWAYS, init-value=0
    provide port Pp_PlantOdoData: nonqueued-sender-com-spec{data-element=PlantOdoData, init-value=0}, provided-interface=IF_PlantOdoData
    provide port DataServices_Data_22FDF7_Intrinsic_Camera_NvM_Data_Read: server-com-spec{operation=ReadData, queue-length=1}, provided-interface=DataServices_Data_22FDF7_Intrinsic_Camera_NvM_Data_Read
    provide port DataServices_Data_22FDF6_RunTimeStatsData_Read: server-com-spec{operation=ReadData, queue-length=1}, provided-interface=DataServices_Data_22FDF6_RunTimeStatsData_Read
    require port RpIntrinsicCameraSN: client-com-spec=Readblock, required-interface=IF_IntrinsicCameraSN
    provide port PpPerformanceStatsEnable: provided-com-specs=[{data-element=RunTimeStatsEnable, init-value=0}, StackUsageStatsEnable], provided-interface=IF_PerformanceStatsEnable
    5 x require port:
      RpRunTimeStatCSData: client-com-spec=Cdd_RunTimeStatQM_GetData, required-interface=IF_RunTimeStat_CSData
      RpRunTimeStats_MCU2_0: nonqueued-receiver-com-spec{data-element=RunTimeStats_MCU2_0_t, filter=data-filter-type=ALWAYS, init-value=fields=[en_Task_BSWTaskTime:10 x 0, en_Task_APPTaskTime:6 x 0]}, required-interface=IF_RunTimeStats_MCU2_0
      RpRunTimeStats_MCU2_1: nonqueued-receiver-com-spec{data-element=RunTimeStats_MCU2_1_t, filter=data-filter-type=ALWAYS, init-value=fields=[en_Task_BSWTaskTime:14 x 0, en_Task_APPTaskTime:[0, 0, 0, 0], en_Task_SAFETYTaskTime:[0, 0, 0, 0]]}, required-interface=IF_RunTimeStats_MCU2_1
      RpRunTimeStats_MPU1_0: nonqueued-receiver-com-spec{data-element=RunTimeStats_MPU1_0_t, filter=data-filter-type=ALWAYS, init-value=fields=[APA_Runtime:0, CALSM_Runtime:0, CALSMThread_Runtime:0, DLDThread_Runtime:0, DLD_Runtime:0, PLDThread_Runtime:0, EOL_Runtime:0, EOLThread_Runtime:0, MOT_Runtime:0, OC_Runtime:0, OCThread_Runtime:0, OD_Runtime:0, ODThread_Runtime:0, OVL3D_Runtime:0, RenderThread_Runtime:0, TAD_Runtime:0, TADThread_Runtime:0, THA_Runtime:0, THAThread_Runtime:0, TIOVXThread_Runtime:0, TIOVX_Runtime:0, CameraCalib_Runtime:0, VideoInput_Runtime:0, AppM_Runtime:0, LogM_Runtime:0, KeepAlive_Runtime:0, ThreadMsgSndr_Runtime:0, SigM_Runtime:0, ThreadSigM_Runtime:0, Sys_Runtime:0, SysMon_Runtime:0, VarM_Runtime:0, AlgoViewThread_Runtime:0]}, required-interface=IF_RunTimeStats_MPU1_0
      RpUssTunData: nonqueued-receiver-com-spec{data-element=UssTunningData_mcu2_1_t, filter=data-filter-type=ALWAYS, init-value=fields=UssTunningDataOut:3072 x 0}, required-interface=IF_UssTunningData_mcu2_1
    provide port DataServices_Data_22FD04_USS_Sensor_tuning_values_Read: provided-interface=DataServices_Data_22FD04_USS_Sensor_tuning_values_Read
      provided-com-specs:
        operation=WriteData, queue-length=1
        operation=ReadDataLength, queue-length=1
        operation=ReadData, queue-length=1
    require port RpCalibRoutineTrigger: nonqueued-receiver-com-spec{data-element=routine_b, filter=data-filter-type=ALWAYS, init-value=0}, required-interface=IF_CalibRoutineTrigger
    require port RpPreviousCamData: nonqueued-receiver-com-spec{data-element=Data, filter=data-filter-type=ALWAYS, init-value=fields=[calibrated:0, {short-label=data, fields=[{short-label=CamFrontCurrent, fields=[{short-label=CamCalibData_STM, fields=[{short-label=calibdata, fields=[Pitch_f32:0, Yaw_f32:0, Roll_f32:0, CalibStatus_e:0, NewValueAvailable_b:0, OverwriteStatus_b:0]}, X_f32:0, Y_f32:0, Z_f32:0, EOLIterationData_au8:5 x 0, Reserved_au8:7 x 0]}, CamCalibIDs_STM:0]}, {short-label=CamLeftCurrent, fields=[{short-label=CamCalibData_STM, fields=[{short-label=calibdata, fields=[Pitch_f32:0, Yaw_f32:0, Roll_f32:0, CalibStatus_e:0, NewValueAvailable_b:0, OverwriteStatus_b:0]}, X_f32:0, Y_f32:0, Z_f32:0, EOLIterationData_au8:5 x 0, Reserved_au8:7 x 0]}, CamCalibIDs_STM:0]}, {short-label=CamRearCurrent, fields=[{short-label=CamCalibData_STM, fields=[{short-label=calibdata, fields=[Pitch_f32:0, Yaw_f32:0, Roll_f32:0, CalibStatus_e:0, NewValueAvailable_b:0, OverwriteStatus_b:0]}, X_f32:0, Y_f32:0, Z_f32:0, EOLIterationData_au8:5 x 0, Reserved_au8:7 x 0]}, CamCalibIDs_STM:0]}, {short-label=CamRightCurrent, fields=[{short-label=CamCalibData_STM, fields=[{short-label=calibdata, fields=[Pitch_f32:0, Yaw_f32:0, Roll_f32:0, CalibStatus_e:0, NewValueAvailable_b:0, OverwriteStatus_b:0]}, X_f32:0, Y_f32:0, Z_f32:0, EOLIterationData_au8:5 x 0, Reserved_au8:7 x 0]}, CamCalibIDs_STM:0]}]}, PrevOdoValue:0]}, required-interface=IF_PreviousCamData
    provide port DataServices_Data_22FDF8_StackUsage_Read: server-com-spec{operation=ReadData, queue-length=1}, provided-interface=DataServices_Data_22FDF8_StackUsage_Read
    require port RpGetTaskStackUsage: client-com-spec=Data, required-interface=IF_GetTaskStackUsage
    require port RpStackUsage_MCU2_1: nonqueued-receiver-com-spec{data-element=StackUsage_MCU2_1_t, filter=data-filter-type=ALWAYS, init-value=fields=[en_Task_BSWTaskTime:6 x 0, en_Task_APPTaskTime:[0, 0], en_Task_SAFETYTaskTime:[0, 0]]}, required-interface=IF_StackUsage_MCU2_1
    require port RpStackUsage_MCU2_0: nonqueued-receiver-com-spec{data-element=StackUsage_MCU2_0_t, filter=data-filter-type=ALWAYS, init-value=fields=[en_Task_BSWTaskTime:5 x 0, en_Task_APPTaskTime:[0, 0, 0]]}, required-interface=IF_StackUsage_MCU2_0
    provide port DataServices_Data_22FDF5_PerformanceStatEnable_Read: provided-com-specs=[{operation=WriteData, queue-length=1}, {operation=ReadData, queue-length=1}], provided-interface=DataServices_Data_22FDF5_PerformanceStatEnable_Read
    behavior SWC_DIDMgr_InternalBehavior: data-type-mapping=DataTypeMappings_DEV, handle-termination-and-restart=NO-SUPPORT
      ar-typed-per-instance-memorys:
        19 x data:
          DID_FD33_MagnaTesting_MirrorBlock: sw-calibration-access=READ-ONLY, type=Dcm_Data10ByteType
          DID_2002_ProgReqFlag_MirrorBlock: sw-calibration-access=READ-ONLY, type=uint8
          DID_2002_OdoFlashing_MirrorBlock: sw-calibration-access=READ-ONLY, type=uint16
          DID_200D_LastClearDTCOdo_MirrorBlock: sw-calibration-access=READ-ONLY, type=uint16
          DID_200C_TimeSinceIgnOnFirstDTC_MirrorBlock: sw-calibration-access=READ-ONLY, type=uint16
          DID_200B_TimeSinceFirstDTC_MirrorBlock: sw-calibration-access=READ-ONLY, type=uint32
          DID_191D_PowerLatch_MirrorBlock: sw-calibration-access=READ-ONLY, type=uint8
          DID_200A_IgOnCounter_MirrorBlock: sw-calibration-access=READ-ONLY, type=uint16
          ECU_LifeTime_MirrorBlock: sw-calibration-access=READ-ONLY, type=uint32
          vRoE_Activation_State_MirrorBlock: sw-calibration-access=READ-ONLY, type=uint8
          DID_FD01_PrevCalibDataCopy_MirrorBlock: sw-calibration-access=READ-ONLY, type=TbSVS_S_SVSCamCurrentCalibData_t
          DID_FD42_FailsafeDebug_MirrorBlock: sw-calibration-access=READ-ONLY, type=uint8, init-value=0
          DID_RearBrakeEvent_MirrorBlock: sw-calibration-access=READ-ONLY, type=RearBrkEvent_t
          DID_SPMAbrtEvent_MirrorBlock: sw-calibration-access=READ-ONLY, type=SPMAbrtEvent_t
          DID_FD86_FunctionalSettings_MirrorBlock: sw-calibration-access=READ-WRITE, type=FunctionalSettings_t
          DID_FDF0_SleepProcess_MirrorBlock: sw-calibration-access=READ-ONLY, type=uint8
          DID_2939_WakeupReason_MirrorBlock: sw-calibration-access=READ-ONLY, type=Arr_20Byte
          DID_FD74_PHY_TuningErr_MirrorBlock: sw-calibration-access=READ-ONLY, type=uint16
          DID_FD74_BuffMarkCompErr_MirrorBlock: sw-calibration-access=READ-ONLY, type=uint16
      init event InitEvent: start-on-event=RE_DIDMgr_Init
      timing event TMT_RE_DIDMgr_Main: start-on-event=RE_DIDMgr_Main, period=0.01
      116 x operation invoked event:
        OIT_DataServices_Data_22FD0A_SC_Data_Read_WriteData_DataServices_Data_22FD0A_SC_Data_Read_WriteData: start-on-event=DataServices_Data_22FD0A_SC_Data_Read_WriteData, operation=DataServices_Data_22FD0A_SC_Data_Read.WriteData
        OIT_DataServices_Data_22FD0A_SC_Data_Read_ReadData_DataServices_Data_22FD0A_SC_Data_Read_ReadData: start-on-event=DataServices_Data_22FD0A_SC_Data_Read_ReadData, operation=DataServices_Data_22FD0A_SC_Data_Read.ReadData
        OIT_DataServices_Data_225500_Trailer_Sense_and_Drive_Function_Data_Read_ReadData_DataServices_Data_225500_Trailer_Sense_E83018E8: start-on-event=DataServices_Data_225500_Trailer_Sense_and_Drive_Function_Data_Read_ReadData, operation=DataServices_Data_225500_Trailer_Sense_and_Drive_Function_Data_Read.ReadData
        OIT_DataServices_Data_222945_Flow_Control_Test_WriteData_DataServices_Data_222945_Flow_Control_Test_WriteData: start-on-event=DataServices_Data_222945_Flow_Control_Test_WriteData, operation=DataServices_Data_222945_Flow_Control_Test.WriteData
        OIT_DataServices_Data_222945_Flow_Control_Test_ReadData_DataServices_Data_222945_Flow_Control_Test_ReadData: start-on-event=DataServices_Data_222945_Flow_Control_Test_ReadData, operation=DataServices_Data_222945_Flow_Control_Test.ReadData
        OIT_DataServices_Data_225303_SPM_Event_Abort_1_Read_ReadData_DataServices_Data_225303_SPM_Event_Abort_1_Read_ReadData: start-on-event=DataServices_Data_225303_SPM_Event_Abort_1_Read_ReadData, operation=DataServices_Data_225303_SPM_Event_Abort_1_Read.ReadData
        OIT_DataServices_Data_22191D_Time_of_Power_Latch_ReadData_DataServices_Data_22191D_Time_of_Power_Latch_ReadData: start-on-event=DataServices_Data_22191D_Time_of_Power_Latch_ReadData, operation=DataServices_Data_22191D_Time_of_Power_Latch.ReadData
        OIT_DataServices_Data_22100B_Diagnostic_Tool_and_Session_Status_ReadData_DataServices_Data_22100B_Diagnostic_Tool_and_SeEC373C63: start-on-event=DataServices_Data_22100B_Diagnostic_Tool_and_Session_Status_ReadData, operation=DataServices_Data_22100B_Diagnostic_Tool_and_Session_Status.ReadData
        OIT_DataServices_Data_224451_EOL_Calibration_State_Read_ReadData_DataServices_Data_224451_EOL_Calibration_State_Read_ReadData: start-on-event=DataServices_Data_224451_EOL_Calibration_State_Read_ReadData, operation=DataServices_Data_224451_EOL_Calibration_State_Read.ReadData
        OIT_DataServices_Data_22FD1C_Current_Camera_Calibration_Data_Read_ReadData_DataServices_Data_22FD1C_Current_Camera_Calib7322D735: start-on-event=DataServices_Data_22FD1C_Current_Camera_Calibration_Data_Read_ReadData, operation=DataServices_Data_22FD1C_Current_Camera_Calibration_Data_Read.ReadData
        OIT_DataServices_Data_225304_SPM_Event_Abort_2_Read_ReadData_DataServices_Data_225304_SPM_Event_Abort_2_Read_ReadData: start-on-event=DataServices_Data_225304_SPM_Event_Abort_2_Read_ReadData, operation=DataServices_Data_225304_SPM_Event_Abort_2_Read.ReadData
        OIT_DataServices_Data_22FD2D_USS_Sensor_ID_IME_SN_Read_ReadData_DataServices_Data_22FD2D_USS_Sensor_ID_IME_SN_Read_ReadData: start-on-event=DataServices_Data_22FD2D_USS_Sensor_ID_IME_SN_Read_ReadData, operation=DataServices_Data_22FD2D_USS_Sensor_ID_IME_SN_Read.ReadData
        OIT_DataServices_Data_22FD0D_Left_Camera_Data_EEPROM_Read_ReadData_DataServices_Data_22FD0D_Left_Camera_Data_EEPROM_Read4E8FB1F6: start-on-event=DataServices_Data_22FD0D_Left_Camera_Data_EEPROM_Read_ReadData, operation=DataServices_Data_22FD0D_Left_Camera_Data_EEPROM_Read.ReadData
        OIT_DataServices_Data_22200D_Odometer_Last_Clear_Data_Trouble_Code_DTC_ReadData_DataServices_Data_22200D_Odometer_Last_CAB3EB535: start-on-event=DataServices_Data_22200D_Odometer_Last_Clear_Data_Trouble_Code_DTC_ReadData, operation=DataServices_Data_22200D_Odometer_Last_Clear_Data_Trouble_Code_DTC.ReadData
        OIT_DataServices_Data_22FD0F_Right_Camera_Data_EEPROM_Read_ReadData_DataServices_Data_22FD0F_Right_Camera_Data_EEPROM_ReEFE5497E: start-on-event=DataServices_Data_22FD0F_Right_Camera_Data_EEPROM_Read_ReadData, operation=DataServices_Data_22FD0F_Right_Camera_Data_EEPROM_Read.ReadData
        OIT_DataServices_Data_225301_Rear_Braking_Event_2_Read_ReadData_DataServices_Data_225301_Rear_Braking_Event_2_Read_ReadData: start-on-event=DataServices_Data_225301_Rear_Braking_Event_2_Read_ReadData, operation=DataServices_Data_225301_Rear_Braking_Event_2_Read.ReadData
        OIT_DataServices_Data_225302_Rear_Braking_Event_3_Read_ReadData_DataServices_Data_225302_Rear_Braking_Event_3_Read_ReadData: start-on-event=DataServices_Data_225302_Rear_Braking_Event_3_Read_ReadData, operation=DataServices_Data_225302_Rear_Braking_Event_3_Read.ReadData
        OIT_DataServices_Data_22FD08_OC_Data_Read_WriteData_DataServices_Data_22FD08_OC_Data_Read_WriteData: start-on-event=DataServices_Data_22FD08_OC_Data_Read_WriteData, operation=DataServices_Data_22FD08_OC_Data_Read.WriteData
        OIT_DataServices_Data_22FD08_OC_Data_Read_ReadData_DataServices_Data_22FD08_OC_Data_Read_ReadData: start-on-event=DataServices_Data_22FD08_OC_Data_Read_ReadData, operation=DataServices_Data_22FD08_OC_Data_Read.ReadData
        OIT_DataServices_Data_220107_RoE_Activation_State_WriteData_DataServices_Data_220107_RoE_Activation_State_WriteData: start-on-event=DataServices_Data_220107_RoE_Activation_State_WriteData, operation=DataServices_Data_220107_RoE_Activation_State.WriteData
        OIT_DataServices_Data_220107_RoE_Activation_State_ReadData_DataServices_Data_220107_RoE_Activation_State_ReadData: start-on-event=DataServices_Data_220107_RoE_Activation_State_ReadData, operation=DataServices_Data_220107_RoE_Activation_State.ReadData
        OIT_DataServices_Data_224423_USS_Sensor_3_Part_Number_Read_ReadData_DataServices_Data_224423_USS_Sensor_3_Part_Number_Re657984F2: start-on-event=DataServices_Data_224423_USS_Sensor_3_Part_Number_Read_ReadData, operation=DataServices_Data_224423_USS_Sensor_3_Part_Number_Read.ReadData
        OIT_DataServices_Data_222010_Programming_Status_ReadData_DataServices_Data_222010_Programming_Status_ReadData: start-on-event=DataServices_Data_222010_Programming_Status_ReadData, operation=DataServices_Data_222010_Programming_Status.ReadData
        OIT_DataServices_Data_221008_ECU_Life_Time_ReadData_DataServices_Data_221008_ECU_Life_Time_ReadData: start-on-event=DataServices_Data_221008_ECU_Life_Time_ReadData, operation=DataServices_Data_221008_ECU_Life_Time.ReadData
        OIT_DataServices_Data_22FD2C_USS_Temperature_Read_ReadData_DataServices_Data_22FD2C_USS_Temperature_Read_ReadData: start-on-event=DataServices_Data_22FD2C_USS_Temperature_Read_ReadData, operation=DataServices_Data_22FD2C_USS_Temperature_Read.ReadData
        OIT_DataServices_Data_22FD2B_USS_Direct_Distance_0xFD2B_Read_ReadData_DataServices_Data_22FD2B_USS_Direct_Distance_0xFD24FFDB917: start-on-event=DataServices_Data_22FD2B_USS_Direct_Distance_0xFD2B_Read_ReadData, operation=DataServices_Data_22FD2B_USS_Direct_Distance_0xFD2B_Read.ReadData
        OIT_DataServices_Data_22FD0E_Rear_Camera_Data_EEPROM_Read_ReadData_DataServices_Data_22FD0E_Rear_Camera_Data_EEPROM_Read8502B56C: start-on-event=DataServices_Data_22FD0E_Rear_Camera_Data_EEPROM_Read_ReadData, operation=DataServices_Data_22FD0E_Rear_Camera_Data_EEPROM_Read.ReadData
        OIT_DataServices_Data_22FD42_Failsafe_Behaviour_Read_WriteData_DataServices_Data_22FD42_Failsafe_Behaviour_Read_WriteData: start-on-event=DataServices_Data_22FD42_Failsafe_Behaviour_Read_WriteData, operation=DataServices_Data_22FD42_Failsafe_Behaviour_Read.WriteData
        OIT_DataServices_Data_22FD42_Failsafe_Behaviour_Read_ReadData_DataServices_Data_22FD42_Failsafe_Behaviour_Read_ReadData: start-on-event=DataServices_Data_22FD42_Failsafe_Behaviour_Read_ReadData, operation=DataServices_Data_22FD42_Failsafe_Behaviour_Read.ReadData
        OIT_DataServices_Data_22F186_Active_Diagnostic_Session_ReadData_DataServices_Data_22F186_Active_Diagnostic_Session_ReadData: start-on-event=DataServices_Data_22F186_Active_Diagnostic_Session_ReadData, operation=DataServices_Data_22F186_Active_Diagnostic_Session.ReadData
        OIT_DataServices_Data_22FDF1_CPU_Load_Read_ReadData_DataServices_Data_22FDF1_CPU_Load_Read_ReadData: start-on-event=DataServices_Data_22FDF1_CPU_Load_Read_ReadData, operation=DataServices_Data_22FDF1_CPU_Load_Read.ReadData
        OIT_DataServices_Data_22442A_USS_Sensor_10_Part_Number_Read_ReadData_DataServices_Data_22442A_USS_Sensor_10_Part_Number_0A97BE9D: start-on-event=DataServices_Data_22442A_USS_Sensor_10_Part_Number_Read_ReadData, operation=DataServices_Data_22442A_USS_Sensor_10_Part_Number_Read.ReadData
        OIT_DataServices_Data_22FD07_OC_Result_Read_ReadData_DataServices_Data_22FD07_OC_Result_Read_ReadData: start-on-event=DataServices_Data_22FD07_OC_Result_Read_ReadData, operation=DataServices_Data_22FD07_OC_Result_Read.ReadData
        OIT_DataServices_Data_22FD2E_USS_Sensor_ID_Murata_SN_Read_ReadData_DataServices_Data_22FD2E_USS_Sensor_ID_Murata_SN_Read372370D9: start-on-event=DataServices_Data_22FD2E_USS_Sensor_ID_Murata_SN_Read_ReadData, operation=DataServices_Data_22FD2E_USS_Sensor_ID_Murata_SN_Read.ReadData
        OIT_DataServices_Data_225300_Rear_Braking_Event_1_Read_ReadData_DataServices_Data_225300_Rear_Braking_Event_1_Read_ReadData: start-on-event=DataServices_Data_225300_Rear_Braking_Event_1_Read_ReadData, operation=DataServices_Data_225300_Rear_Braking_Event_1_Read.ReadData
        OIT_DataServices_Data_22442B_USS_Sensor_11_Part_Number_Read_ReadData_DataServices_Data_22442B_USS_Sensor_11_Part_Number_0694F5BE: start-on-event=DataServices_Data_22442B_USS_Sensor_11_Part_Number_Read_ReadData, operation=DataServices_Data_22442B_USS_Sensor_11_Part_Number_Read.ReadData
        OIT_DataServices_Data_224429_USS_Sensor_9_Part_Number_Read_ReadData_DataServices_Data_224429_USS_Sensor_9_Part_Number_Re165ED398: start-on-event=DataServices_Data_224429_USS_Sensor_9_Part_Number_Read_ReadData, operation=DataServices_Data_224429_USS_Sensor_9_Part_Number_Read.ReadData
        OIT_DataServices_Data_22FD0C_Front_Camera_Data_EEPROM_Read_ReadData_DataServices_Data_22FD0C_Front_Camera_Data_EEPROM_Re37809C69: start-on-event=DataServices_Data_22FD0C_Front_Camera_Data_EEPROM_Read_ReadData, operation=DataServices_Data_22FD0C_Front_Camera_Data_EEPROM_Read.ReadData
        OIT_DataServices_Data_225100_SPM_status_Read_ReadData_DataServices_Data_225100_SPM_status_Read_ReadData: start-on-event=DataServices_Data_225100_SPM_status_Read_ReadData, operation=DataServices_Data_225100_SPM_status_Read.ReadData
        OIT_DataServices_Data_22200B_Time_First_DTC_Detection_ReadData_DataServices_Data_22200B_Time_First_DTC_Detection_ReadData: start-on-event=DataServices_Data_22200B_Time_First_DTC_Detection_ReadData, operation=DataServices_Data_22200B_Time_First_DTC_Detection.ReadData
        OIT_DataServices_Data_224425_USS_Sensor_5_Part_Number_Read_ReadData_DataServices_Data_224425_USS_Sensor_5_Part_Number_Re4B9B49D4: start-on-event=DataServices_Data_224425_USS_Sensor_5_Part_Number_Read_ReadData, operation=DataServices_Data_224425_USS_Sensor_5_Part_Number_Read.ReadData
        OIT_DataServices_Data_22FD33_Magna_Testing_2_Read_WriteData_DataServices_Data_22FD33_Magna_Testing_2_Read_WriteData: start-on-event=DataServices_Data_22FD33_Magna_Testing_2_Read_WriteData, operation=DataServices_Data_22FD33_Magna_Testing_2_Read.WriteData
        OIT_DataServices_Data_22FD33_Magna_Testing_2_Read_ReadData_DataServices_Data_22FD33_Magna_Testing_2_Read_ReadData: start-on-event=DataServices_Data_22FD33_Magna_Testing_2_Read_ReadData, operation=DataServices_Data_22FD33_Magna_Testing_2_Read.ReadData
        OIT_DataServices_Data_22200C_Time_Since_Ignition_ON_of_first_DTC_Detection_ReadData_DataServices_Data_22200C_Time_Since_D8BD46AA: start-on-event=DataServices_Data_22200C_Time_Since_Ignition_ON_of_first_DTC_Detection_ReadData, operation=DataServices_Data_22200C_Time_Since_Ignition_ON_of_first_DTC_Detection.ReadData
        OIT_DataServices_Data_224421_USS_Sensor_1_Part_Number_Read_ReadData_DataServices_Data_224421_USS_Sensor_1_Part_Number_Re7F27C010: start-on-event=DataServices_Data_224421_USS_Sensor_1_Part_Number_Read_ReadData, operation=DataServices_Data_224421_USS_Sensor_1_Part_Number_Read.ReadData
        OIT_DataServices_Data_225501_Trailer_coupler_sense_detection_Function_Data_Read_ReadData_DataServices_Data_225501_TraileBF8A44A3: start-on-event=DataServices_Data_225501_Trailer_coupler_sense_detection_Function_Data_Read_ReadData, operation=DataServices_Data_225501_Trailer_coupler_sense_detection_Function_Data_Read.ReadData
        OIT_DataServices_Data_221002_Vehicle_Speed_ReadData_DataServices_Data_221002_Vehicle_Speed_ReadData: start-on-event=DataServices_Data_221002_Vehicle_Speed_ReadData, operation=DataServices_Data_221002_Vehicle_Speed.ReadData
        OIT_DataServices_Data_22FD48_PCBA_Temperature_Read_ReadData_DataServices_Data_22FD48_PCBA_Temperature_Read_ReadData: start-on-event=DataServices_Data_22FD48_PCBA_Temperature_Read_ReadData, operation=DataServices_Data_22FD48_PCBA_Temperature_Read.ReadData
        OIT_DataServices_Data_221004_Battery_Voltage_ReadData_DataServices_Data_221004_Battery_Voltage_ReadData: start-on-event=DataServices_Data_221004_Battery_Voltage_ReadData, operation=DataServices_Data_221004_Battery_Voltage.ReadData
        OIT_DataServices_Data_221921_Operational_Mode_Status_ReadData_DataServices_Data_221921_Operational_Mode_Status_ReadData: start-on-event=DataServices_Data_221921_Operational_Mode_Status_ReadData, operation=DataServices_Data_221921_Operational_Mode_Status.ReadData
        OIT_DataServices_Data_2EF185_Application_Data_Software_Fingerprint_Writing_Information_WriteData_DataServices_Data_2EF181B96142F: start-on-event=DataServices_Data_2EF185_Application_Data_Software_Fingerprint_Writing_Information_WriteData, operation=DataServices_Data_2EF185_Application_Data_Software_Fingerprint_Writing_Information.WriteData
        OIT_DataServices_Data_22FD20_ECU_PinStates_Read_ReadData_DataServices_Data_22FD20_ECU_PinStates_Read_ReadData: start-on-event=DataServices_Data_22FD20_ECU_PinStates_Read_ReadData, operation=DataServices_Data_22FD20_ECU_PinStates_Read.ReadData
        OIT_DataServices_Data_22FDF2_Reset_Reason_Read_ReadData_DataServices_Data_22FDF2_Reset_Reason_Read_ReadData: start-on-event=DataServices_Data_22FDF2_Reset_Reason_Read_ReadData, operation=DataServices_Data_22FDF2_Reset_Reason_Read.ReadData
        OIT_DataServices_Data_224426_USS_Sensor_6_Part_Number_Read_ReadData_DataServices_Data_224426_USS_Sensor_6_Part_Number_Re5CEA2F47: start-on-event=DataServices_Data_224426_USS_Sensor_6_Part_Number_Read_ReadData, operation=DataServices_Data_224426_USS_Sensor_6_Part_Number_Read.ReadData
        OIT_DataServices_Data_22FD2A_USS_Ringing_Time_Read_ReadData_DataServices_Data_22FD2A_USS_Ringing_Time_Read_ReadData: start-on-event=DataServices_Data_22FD2A_USS_Ringing_Time_Read_ReadData, operation=DataServices_Data_22FD2A_USS_Ringing_Time_Read.ReadData
        OIT_DataServices_Data_224428_USS_Sensor_8_Part_Number_Read_ReadData_DataServices_Data_224428_USS_Sensor_8_Part_Number_Re1B71F1E9: start-on-event=DataServices_Data_224428_USS_Sensor_8_Part_Number_Read_ReadData, operation=DataServices_Data_224428_USS_Sensor_8_Part_Number_Read.ReadData
        OIT_DataServices_Data_22200A_Ignition_ON_Counter_ReadData_DataServices_Data_22200A_Ignition_ON_Counter_ReadData: start-on-event=DataServices_Data_22200A_Ignition_ON_Counter_ReadData, operation=DataServices_Data_22200A_Ignition_ON_Counter.ReadData
        OIT_DataServices_Data_222001_Odometer_ReadData_DataServices_Data_222001_Odometer_ReadData: start-on-event=DataServices_Data_222001_Odometer_ReadData, operation=DataServices_Data_222001_Odometer.ReadData
        OIT_DataServices_Data_22F1A6_Message_Matrix_ReadData_DataServices_Data_22F1A6_Message_Matrix_ReadData: start-on-event=DataServices_Data_22F1A6_Message_Matrix_ReadData, operation=DataServices_Data_22F1A6_Message_Matrix.ReadData
        OIT_DataServices_Data_22442C_USS_Sensor_12_Part_Number_Read_ReadData_DataServices_Data_22442C_USS_Sensor_12_Part_Number_1D8D6E20: start-on-event=DataServices_Data_22442C_USS_Sensor_12_Part_Number_Read_ReadData, operation=DataServices_Data_22442C_USS_Sensor_12_Part_Number_Read.ReadData
        OIT_DataServices_Data_224427_USS_Sensor_7_Part_Number_Read_ReadData_DataServices_Data_224427_USS_Sensor_7_Part_Number_Re51C50D36: start-on-event=DataServices_Data_224427_USS_Sensor_7_Part_Number_Read_ReadData, operation=DataServices_Data_224427_USS_Sensor_7_Part_Number_Read.ReadData
        OIT_DataServices_Data_222008_ECU_Life_Time_Not_Volatile_Memory_ReadData_DataServices_Data_222008_ECU_Life_Time_Not_Volat846BD55C: start-on-event=DataServices_Data_222008_ECU_Life_Time_Not_Volatile_Memory_ReadData, operation=DataServices_Data_222008_ECU_Life_Time_Not_Volatile_Memory.ReadData
        OIT_DataServices_Data_22FD28_USS_Ringing_Frequency_Read_ReadData_DataServices_Data_22FD28_USS_Ringing_Frequency_Read_ReadData: start-on-event=DataServices_Data_22FD28_USS_Ringing_Frequency_Read_ReadData, operation=DataServices_Data_22FD28_USS_Ringing_Frequency_Read.ReadData
        OIT_DataServices_Data_222002_Odometer_at_last_Flash_programming_ReadData_DataServices_Data_222002_Odometer_at_last_Flash4ADEEA66: start-on-event=DataServices_Data_222002_Odometer_at_last_Flash_programming_ReadData, operation=DataServices_Data_222002_Odometer_at_last_Flash_programming.ReadData
        OIT_DataServices_Data_2EF184_Application_Software_Fingerprint_writing_information_WriteData_DataServices_Data_2EF184_App7A639748: start-on-event=DataServices_Data_2EF184_Application_Software_Fingerprint_writing_information_WriteData, operation=DataServices_Data_2EF184_Application_Software_Fingerprint_writing_information.WriteData
        OIT_DataServices_Data_22FD1E_Calibration_Status_Read_ReadData_DataServices_Data_22FD1E_Calibration_Status_Read_ReadData: start-on-event=DataServices_Data_22FD1E_Calibration_Status_Read_ReadData, operation=DataServices_Data_22FD1E_Calibration_Status_Read.ReadData
        OIT_DataServices_Data_224424_USS_Sensor_4_Part_Number_Read_ReadData_DataServices_Data_224424_USS_Sensor_4_Part_Number_Re46B46BA5: start-on-event=DataServices_Data_224424_USS_Sensor_4_Part_Number_Read_ReadData, operation=DataServices_Data_224424_USS_Sensor_4_Part_Number_Read.ReadData
        OIT_DataServices_Data_221009_ECU_Time_Since_Ignition_ON_ReadData_DataServices_Data_221009_ECU_Time_Since_Ignition_ON_ReadData: start-on-event=DataServices_Data_221009_ECU_Time_Since_Ignition_ON_ReadData, operation=DataServices_Data_221009_ECU_Time_Since_Ignition_ON.ReadData
        OIT_DataServices_Data_22FD29_USS_Driving_Frequency_Read_ReadData_DataServices_Data_22FD29_USS_Driving_Frequency_Read_ReadData: start-on-event=DataServices_Data_22FD29_USS_Driving_Frequency_Read_ReadData, operation=DataServices_Data_22FD29_USS_Driving_Frequency_Read.ReadData
        OIT_DataServices_Data_224422_USS_Sensor2_Part_Number_Read_ReadData_DataServices_Data_224422_USS_Sensor2_Part_Number_Read28F5A20D: start-on-event=DataServices_Data_224422_USS_Sensor2_Part_Number_Read_ReadData, operation=DataServices_Data_224422_USS_Sensor2_Part_Number_Read.ReadData
        OIT_DataServices_Data_225305_SPM_Event_Abort_3_Read_ReadData_DataServices_Data_225305_SPM_Event_Abort_3_Read_ReadData: start-on-event=DataServices_Data_225305_SPM_Event_Abort_3_Read_ReadData, operation=DataServices_Data_225305_SPM_Event_Abort_3_Read.ReadData
        OIT_DataServices_Data_22FD01_Previous_Camera_Calibration_Data_ReadData_DataServices_Data_22FD01_Previous_Camera_Calibrat30A23EA2: start-on-event=DataServices_Data_22FD01_Previous_Camera_Calibration_Data_ReadData, operation=DataServices_Data_22FD01_Previous_Camera_Calibration_Data.ReadData
        OIT_DataServices_Data_22FD00_Plant_Camera_Calibration_Data_WriteData_DataServices_Data_22FD00_Plant_Camera_Calibration_DDFED2A6F: start-on-event=DataServices_Data_22FD00_Plant_Camera_Calibration_Data_WriteData, operation=DataServices_Data_22FD00_Plant_Camera_Calibration_Data.WriteData
        OIT_DataServices_Data_22FD00_Plant_Camera_Calibration_Data_ReadData_DataServices_Data_22FD00_Plant_Camera_Calibration_Da707E5122: start-on-event=DataServices_Data_22FD00_Plant_Camera_Calibration_Data_ReadData, operation=DataServices_Data_22FD00_Plant_Camera_Calibration_Data.ReadData
        OIT_DataServices_Data_22FD86_Functional_Settings_Read_WriteData_DataServices_Data_22FD86_Functional_Settings_Read_WriteData: start-on-event=DataServices_Data_22FD86_Functional_Settings_Read_WriteData, operation=DataServices_Data_22FD86_Functional_Settings_Read.WriteData
        OIT_DataServices_Data_22FD86_Functional_Settings_Read_ReadData_DataServices_Data_22FD86_Functional_Settings_Read_ReadData: start-on-event=DataServices_Data_22FD86_Functional_Settings_Read_ReadData, operation=DataServices_Data_22FD86_Functional_Settings_Read.ReadData
        OIT_DataServices_Data_22FD46_Camera_Power_Supply_Read_ReadData_DataServices_Data_22FD46_Camera_Power_Supply_Read_ReadData: start-on-event=DataServices_Data_22FD46_Camera_Power_Supply_Read_ReadData, operation=DataServices_Data_22FD46_Camera_Power_Supply_Read.ReadData
        OIT_DataServices_Data_225102_FD_CAN14_Rx_Signals_Read_ReadData_DataServices_Data_225102_FD_CAN14_Rx_Signals_Read_ReadData: start-on-event=DataServices_Data_225102_FD_CAN14_Rx_Signals_Read_ReadData, operation=DataServices_Data_225102_FD_CAN14_Rx_Signals_Read.ReadData
        OIT_DataServices_Data_2F5001_Gear_Position_Read_ShortTermAdjustment_DataServices_Data_2F5001_Gear_Position_Read_ShortTer0D8CE892: start-on-event=DataServices_Data_2F5001_Gear_Position_Read_ShortTermAdjustment, operation=DataServices_Data_2F5001_Gear_Position_Read.ShortTermAdjustment
        OIT_DataServices_Data_2F5001_Gear_Position_Read_ReturnControlToECU_DataServices_Data_2F5001_Gear_Position_Read_ReturnConC4BEAF84: start-on-event=DataServices_Data_2F5001_Gear_Position_Read_ReturnControlToECU, operation=DataServices_Data_2F5001_Gear_Position_Read.ReturnControlToECU
        OIT_DataServices_Data_2F5001_Gear_Position_Read_ReadData_DataServices_Data_2F5001_Gear_Position_Read_ReadData: start-on-event=DataServices_Data_2F5001_Gear_Position_Read_ReadData, operation=DataServices_Data_2F5001_Gear_Position_Read.ReadData
        OIT_DataServices_Data_225105_FD_CAN2_Tx_Signals_Read_ReadData_DataServices_Data_225105_FD_CAN2_Tx_Signals_Read_ReadData: start-on-event=DataServices_Data_225105_FD_CAN2_Tx_Signals_Read_ReadData, operation=DataServices_Data_225105_FD_CAN2_Tx_Signals_Read.ReadData
        OIT_DataServices_Data_225103_FD_CAN2_Rx_Signals_Read_ReadData_DataServices_Data_225103_FD_CAN2_Rx_Signals_Read_ReadData: start-on-event=DataServices_Data_225103_FD_CAN2_Rx_Signals_Read_ReadData, operation=DataServices_Data_225103_FD_CAN2_Rx_Signals_Read.ReadData
        OIT_DataServices_Data_225104_FD_CAN14_Tx_Signals_Read_ReadData_DataServices_Data_225104_FD_CAN14_Tx_Signals_Read_ReadData: start-on-event=DataServices_Data_225104_FD_CAN14_Tx_Signals_Read_ReadData, operation=DataServices_Data_225104_FD_CAN14_Tx_Signals_Read.ReadData
        OIT_DataServices_Data_22FD62_ASIL_QM_Fault_Status_Read_ReadData_DataServices_Data_22FD62_ASIL_QM_Fault_Status_Read_ReadData: start-on-event=DataServices_Data_22FD62_ASIL_QM_Fault_Status_Read_ReadData, operation=DataServices_Data_22FD62_ASIL_QM_Fault_Status_Read.ReadData
        OIT_DataServices_Data_222939_FDCAN2_BUS_Network_WakeUp_Reason_ReadData_DataServices_Data_222939_FDCAN2_BUS_Network_WakeU283EDE76: start-on-event=DataServices_Data_222939_FDCAN2_BUS_Network_WakeUp_Reason_ReadData, operation=DataServices_Data_222939_FDCAN2_BUS_Network_WakeUp_Reason.ReadData
        OIT_DataServices_Data_22FD47_SoC_Temperature_0xFD47_Read_ReadData_DataServices_Data_22FD47_SoC_Temperature_0xFD47_Read_ReadData: start-on-event=DataServices_Data_22FD47_SoC_Temperature_0xFD47_Read_ReadData, operation=DataServices_Data_22FD47_SoC_Temperature_0xFD47_Read.ReadData
        OIT_DataServices_Data_22FD60_ECU_Software_Status_Read_ReadData_DataServices_Data_22FD60_ECU_Software_Status_Read_ReadData: start-on-event=DataServices_Data_22FD60_ECU_Software_Status_Read_ReadData, operation=DataServices_Data_22FD60_ECU_Software_Status_Read.ReadData
        OIT_DataServices_Data_22FD64_ASIL_B_Fault_Status_Read_ReadData_DataServices_Data_22FD64_ASIL_B_Fault_Status_Read_ReadData: start-on-event=DataServices_Data_22FD64_ASIL_B_Fault_Status_Read_ReadData, operation=DataServices_Data_22FD64_ASIL_B_Fault_Status_Read.ReadData
        OIT_DataServices_Data_2EFD4E_Reset_NVM_Write_WriteData_DataServices_Data_2EFD4E_Reset_NVM_Write_WriteData: start-on-event=DataServices_Data_2EFD4E_Reset_NVM_Write_WriteData, operation=DataServices_Data_2EFD4E_Reset_NVM_Write.WriteData
        OIT_DataServices_Data_22FD49_SoC_Die_Temperature_ID_0xFD49_Read_ReadData_DataServices_Data_22FD49_SoC_Die_Temperature_ID94F3268C: start-on-event=DataServices_Data_22FD49_SoC_Die_Temperature_ID_0xFD49_Read_ReadData, operation=DataServices_Data_22FD49_SoC_Die_Temperature_ID_0xFD49_Read.ReadData
        OIT_DataServices_Data_22FDF0_ECU_shutdown_process_Read_WriteData_DataServices_Data_22FDF0_ECU_shutdown_process_Read_WriteData: start-on-event=DataServices_Data_22FDF0_ECU_shutdown_process_Read_WriteData, operation=DataServices_Data_22FDF0_ECU_shutdown_process_Read.WriteData
        OIT_DataServices_Data_22FDF0_ECU_shutdown_process_Read_ReadData_DataServices_Data_22FDF0_ECU_shutdown_process_Read_ReadData: start-on-event=DataServices_Data_22FDF0_ECU_shutdown_process_Read_ReadData, operation=DataServices_Data_22FDF0_ECU_shutdown_process_Read.ReadData
        OIT_DataServices_Data_222026_CAN_Overrun_Counters_ReadData_DataServices_Data_222026_CAN_Overrun_Counters_ReadData: start-on-event=DataServices_Data_222026_CAN_Overrun_Counters_ReadData, operation=DataServices_Data_222026_CAN_Overrun_Counters.ReadData
        OIT_DataServices_Data_22102A_Check_EOL_Configuration_Data_ReadData_DataServices_Data_22102A_Check_EOL_Configuration_DataE77BC232: start-on-event=DataServices_Data_22102A_Check_EOL_Configuration_Data_ReadData, operation=DataServices_Data_22102A_Check_EOL_Configuration_Data.ReadData
        OIT_DataServices_Data_225201_Plant_Mode_Status_Read_ReadData_DataServices_Data_225201_Plant_Mode_Status_Read_ReadData: start-on-event=DataServices_Data_225201_Plant_Mode_Status_Read_ReadData, operation=DataServices_Data_225201_Plant_Mode_Status_Read.ReadData
        OIT_DataServices_Data_2E2023_PROXI_Data_WriteData_DataServices_Data_2E2023_PROXI_Data_WriteData: start-on-event=DataServices_Data_2E2023_PROXI_Data_WriteData, operation=DataServices_Data_2E2023_PROXI_Data.WriteData
        OIT_DataServices_Data_220103_VIN_Lock_Status_ReadData_DataServices_Data_220103_VIN_Lock_Status_ReadData: start-on-event=DataServices_Data_220103_VIN_Lock_Status_ReadData, operation=DataServices_Data_220103_VIN_Lock_Status.ReadData
        OIT_DataServices_Data_222013_VIN_Lock_State_Read_ReadData_DataServices_Data_222013_VIN_Lock_State_Read_ReadData: start-on-event=DataServices_Data_222013_VIN_Lock_State_Read_ReadData, operation=DataServices_Data_222013_VIN_Lock_State_Read.ReadData
        OIT_DataServices_Data_22F1A1_Configuration_Code_ReadData_DataServices_Data_22F1A1_Configuration_Code_ReadData: start-on-event=DataServices_Data_22F1A1_Configuration_Code_ReadData, operation=DataServices_Data_22F1A1_Configuration_Code.ReadData
        OIT_DataServices_Data_22F190_VIN_Original_ReadData_DataServices_Data_22F190_VIN_Original_ReadData: start-on-event=DataServices_Data_22F190_VIN_Original_ReadData, operation=DataServices_Data_22F190_VIN_Original.ReadData
        OIT_DataServices_Data_22FD61_Vehicle_Variant_Coding_Data_Read_ReadData_DataServices_Data_22FD61_Vehicle_Variant_Coding_D2830F7CB: start-on-event=DataServices_Data_22FD61_Vehicle_Variant_Coding_Data_Read_ReadData, operation=DataServices_Data_22FD61_Vehicle_Variant_Coding_Data_Read.ReadData
        OIT_DataServices_Data_22F1B0_VIN_Current_ReadData_DataServices_Data_22F1B0_VIN_Current_ReadData: start-on-event=DataServices_Data_22F1B0_VIN_Current_ReadData, operation=DataServices_Data_22F1B0_VIN_Current.ReadData
        OIT_DataServices_Data_222024_Read_ECU_PROXI_Data_ReadDataLength_DataServices_Data_222024_Read_ECU_PROXI_Data_ReadDataLength: start-on-event=DataServices_Data_222024_Read_ECU_PROXI_Data_ReadDataLength, operation=DataServices_Data_222024_Read_ECU_PROXI_Data.ReadDataLength
        OIT_DataServices_Data_222024_Read_ECU_PROXI_Data_ReadData_DataServices_Data_222024_Read_ECU_PROXI_Data_ReadData: start-on-event=DataServices_Data_222024_Read_ECU_PROXI_Data_ReadData, operation=DataServices_Data_222024_Read_ECU_PROXI_Data.ReadData
        OIT_DataServices_Data_22292E_PROXI_Write_Counter_ReadData_DataServices_Data_22292E_PROXI_Write_Counter_ReadData: start-on-event=DataServices_Data_22292E_PROXI_Write_Counter_ReadData, operation=DataServices_Data_22292E_PROXI_Write_Counter.ReadData
        OIT_DataServices_Data_22F10B_ECU_Qualification_ReadData_DataServices_Data_22F10B_ECU_Qualification_ReadData: start-on-event=DataServices_Data_22F10B_ECU_Qualification_ReadData, operation=DataServices_Data_22F10B_ECU_Qualification.ReadData
        OIT_DataServices_Data_22FD4A_Ultrasonic_Sensors_Power_supply_and_Current_Level_Read_ReadData_DataServices_Data_22FD4A_Ul8AA28754: start-on-event=DataServices_Data_22FD4A_Ultrasonic_Sensors_Power_supply_and_Current_Level_Read_ReadData, operation=DataServices_Data_22FD4A_Ultrasonic_Sensors_Power_supply_and_Current_Level_Read.ReadData
        OIT_DataServices_Data_225109_Rear_Sensor_HealthBlockage_LiveDetection_Check_Read_ReadData_DataServices_Data_225109_Rear_C4072654: start-on-event=DataServices_Data_225109_Rear_Sensor_HealthBlockage_LiveDetection_Check_Read_ReadData, operation=DataServices_Data_225109_Rear_Sensor_HealthBlockage_LiveDetection_Check_Read.ReadData
        OIT_DataServices_Data_225107_Front_Sensor_HealthBlockage_LiveDetection_Check_Read_ReadData_DataServices_Data_225107_FronE68E76DA: start-on-event=DataServices_Data_225107_Front_Sensor_HealthBlockage_LiveDetection_Check_Read_ReadData, operation=DataServices_Data_225107_Front_Sensor_HealthBlockage_LiveDetection_Check_Read.ReadData
        OIT_DataServices_Data_22FD65_FuSa_Module_Status_Read_ReadData_DataServices_Data_22FD65_FuSa_Module_Status_Read_ReadData: start-on-event=DataServices_Data_22FD65_FuSa_Module_Status_Read_ReadData, operation=DataServices_Data_22FD65_FuSa_Module_Status_Read.ReadData
        OIT_Pp_NVM_Write_ProxiConfigTable_ProxiconfigTable_Nvm_write_confirmation_Pp_NVM_Write_ProxiConfigTable_ProxiconfigTable9D6E03A4: start-on-event=Pp_NVM_Write_ProxiConfigTable_ProxiconfigTable_Nvm_write_confirmation, operation=Pp_NVM_Write_ProxiConfigTable.ProxiconfigTable_Nvm_write_confirmation
        OIT_DataServices_Data_22FD43_Active_Safe_State_Read_DataServices_Data_22FD43_Active_Safe_State_Read_ReadData: start-on-event=DataServices_Data_22FD43_Active_Safe_State_Read, operation=DataServices_Data_22FD43_Active_Safe_State_Read.ReadData
        OIT_Runnable_DataServices_Data_22FD44_Error_Flags_Read_ReadData: start-on-event=DataServices_Data_22FD44_Error_Flags_Read, operation=DataServices_Data_22FD44_Error_Flags_Read.ReadData
        OIT_DataServices_Data_22FD66_Camera_occlusion_and_low_light_status_Read_DataServices_Data_22FD66_Camera_occlusion_and_lo4CA3D059: start-on-event=DataServices_Data_22FD66_Camera_occlusion_and_low_light_status_Read, operation=DataServices_Data_22FD66_Camera_occlusion_and_low_light_status_Read.ReadData
        OIT_DataServices_Data_22FD67_Camera_DLD_Status_Read_DataServices_Data_22FD67_Camera_DLD_Status_Read_ReadData: start-on-event=DataServices_Data_22FD67_Camera_DLD_Status_Read, operation=DataServices_Data_22FD67_Camera_DLD_Status_Read.ReadData
      timing event TMT_RE_periodic_CPU_Load: start-on-event=RE_periodic_CPU_Load, period=0.2
      9 x operation invoked event:
        OIT_DataServices_Data_22FD74_PHY_Tunning_Error_And_Buffer_Mark_Error_Read_ReadData_DataServices_Data_22FD74_PHY_Tunning_6B125AB5: start-on-event=DataServices_Data_22FD74_PHY_Tunning_Error_And_Buffer_Mark_Error_Read_ReadData, operation=DataServices_Data_22FD74_PHY_Tunning_Error_And_Buffer_Mark_Error_Read.ReadData
        OIT_DataServices_Data_22FDF6_RunTimeStatsData_Read_ReadData_DataServices_Data_22FDF6_RunTimeStatsData_Read_ReadData: start-on-event=DataServices_Data_22FDF6_RunTimeStatsData_Read_ReadData, operation=DataServices_Data_22FDF6_RunTimeStatsData_Read.ReadData
        OIT_DataServices_Data_22FDF7_Intrinsic_Camera_NvM_Data_Read_ReadData_DataServices_Data_22FDF7_Intrinsic_Camera_NvM_Data_7AB8FFD0: start-on-event=DataServices_Data_22FDF7_Intrinsic_Camera_NvM_Data_Read_ReadData, operation=DataServices_Data_22FDF7_Intrinsic_Camera_NvM_Data_Read.ReadData
        OIT_DataServices_Data_22FD04_USS_Sensor_tuning_values_Read_WriteData_DataServices_Data_22FD04_USS_Sensor_tuning_values_R2092B5D3: start-on-event=DataServices_Data_22FD04_USS_Sensor_tuning_values_Read_WriteData, operation=DataServices_Data_22FD04_USS_Sensor_tuning_values_Read.WriteData
        OIT_DataServices_Data_22FD04_USS_Sensor_tuning_values_Read_ReadDataLength_DataServices_Data_22FD04_USS_Sensor_tuning_val2E882436: start-on-event=DataServices_Data_22FD04_USS_Sensor_tuning_values_Read_ReadDataLength, operation=DataServices_Data_22FD04_USS_Sensor_tuning_values_Read.ReadDataLength
        OIT_DataServices_Data_22FD04_USS_Sensor_tuning_values_Read_ReadData_DataServices_Data_22FD04_USS_Sensor_tuning_values_ReB9D99541: start-on-event=DataServices_Data_22FD04_USS_Sensor_tuning_values_Read_ReadData, operation=DataServices_Data_22FD04_USS_Sensor_tuning_values_Read.ReadData
        OIT_DataServices_Data_22FDF8_StackUsage_Read_ReadData_DataServices_Data_22FDF8_StackUsage_Read_ReadData: start-on-event=DataServices_Data_22FDF8_StackUsage_Read_ReadData, operation=DataServices_Data_22FDF8_StackUsage_Read.ReadData
        OIT_DataServices_Data_22FDF5_PerformanceStatEnable_Read_WriteData_DataServices_Data_22FDF5_PerformanceStatEnable_Read_WriteData: start-on-event=DataServices_Data_22FDF5_PerformanceStatEnable_Read_WriteData, operation=DataServices_Data_22FDF5_PerformanceStatEnable_Read.WriteData
        OIT_DataServices_Data_22FDF5_PerformanceStatEnable_Read_ReadData_DataServices_Data_22FDF5_PerformanceStatEnable_Read_ReadData: start-on-event=DataServices_Data_22FDF5_PerformanceStatEnable_Read_ReadData, operation=DataServices_Data_22FDF5_PerformanceStatEnable_Read.ReadData
      per-instance-parameters:
        20 x parameter data prototype, all with sw-calibration-access=READ-WRITE:
          DID_FD33_MagnaTesting_DefaultValue: type=Dcm_Data10ByteType, init-value=10 x 0
          DID_2002_ProgReqFlag_DefaultValue: type=uint8, init-value=0
          DID_2002_OdoFlashing_DefaultValue: type=uint16, init-value=0
          DID_200D_LastClearDTCOdo_DefaultValue: type=uint16, init-value=0
          DID_200C_TimeSinceIgnOnFirstDTC_DefaultValue: type=uint16, init-value=0
          DID_200B_TimeSinceFirstDTC_DefaultValue: type=uint32, init-value=0
          DID_191D_PowerLatch_DefaultValue: type=uint8, init-value=0
          DID_200A_IgOnCounter_DefaultValue: type=uint16, init-value=0
          ECU_LifeTime_DefaultValue: type=uint32, init-value=0
          vRoE_Activation_State_DefaultValue: type=uint8, init-value=0
          DID_FD01_PrevCalibDataCopy_DefaultValue: type=TbSVS_S_SVSCamCurrentCalibData_t, init-value=fields=[{short-label=CamFrontCurrent, fields=[{short-label=CamCalibData_STM, fields=[{short-label=calibdata, fields=[Pitch_f32:0, Yaw_f32:0, Roll_f32:0, CalibStatus_e:0, NewValueAvailable_b:0, OverwriteStatus_b:0]}, X_f32:0, Y_f32:0, Z_f32:0, EOLIterationData_au8:5 x 0, Reserved_au8:7 x 0]}, CamCalibIDs_STM:0]}, {short-label=CamLeftCurrent, fields=[{short-label=CamCalibData_STM, fields=[{short-label=calibdata, fields=[Pitch_f32:0, Yaw_f32:0, Roll_f32:0, CalibStatus_e:0, NewValueAvailable_b:0, OverwriteStatus_b:0]}, X_f32:0, Y_f32:0, Z_f32:0, EOLIterationData_au8:5 x 0, Reserved_au8:7 x 0]}, CamCalibIDs_STM:0]}, {short-label=CamRearCurrent, fields=[{short-label=CamCalibData_STM, fields=[{short-label=calibdata, fields=[Pitch_f32:0, Yaw_f32:0, Roll_f32:0, CalibStatus_e:0, NewValueAvailable_b:0, OverwriteStatus_b:0]}, X_f32:0, Y_f32:0, Z_f32:0, EOLIterationData_au8:5 x 0, Reserved_au8:7 x 0]}, CamCalibIDs_STM:0]}, {short-label=CamRightCurrent, fields=[{short-label=CamCalibData_STM, fields=[{short-label=calibdata, fields=[Pitch_f32:0, Yaw_f32:0, Roll_f32:0, CalibStatus_e:0, NewValueAvailable_b:0, OverwriteStatus_b:0]}, X_f32:0, Y_f32:0, Z_f32:0, EOLIterationData_au8:5 x 0, Reserved_au8:7 x 0]}, CamCalibIDs_STM:0]}]
          DID_FD42_FailsafeDebug_DefaultValue: type=uint8, init-value=0
          DID_RearBrakeEvent_DefaultValue: type=RearBrkEvent_t, init-value=fields=[BlockIdx_u8:0, RearBrkEvent_Arr:[fields=[Odometer_u16:0, GasPedalPosEvntStart_u16:0, StreeringWhlAngEvntStart_u16:0, VehicleSpeed_u16:0, ExtTemp_u8:0, DistToObjEvntStart_u16:0, DistToObjEvntEnd_u16:0], fields=[Odometer_u16:0, GasPedalPosEvntStart_u16:0, StreeringWhlAngEvntStart_u16:0, VehicleSpeed_u16:0, ExtTemp_u8:0, DistToObjEvntStart_u16:0, DistToObjEvntEnd_u16:0], fields=[Odometer_u16:0, GasPedalPosEvntStart_u16:0, StreeringWhlAngEvntStart_u16:0, VehicleSpeed_u16:0, ExtTemp_u8:0, DistToObjEvntStart_u16:0, DistToObjEvntEnd_u16:0]]]
          DID_SPMAbrtEvent_DefaultValue: type=SPMAbrtEvent_t, init-value=fields=[BlockIdx_u8:0, SPMAbrtEvent_Arr:[fields=[ManeuverType_u8:0, CurbDetected_u8:0, SideofVehicle_u8:0, Reserved_u8:0, MeasuredSlotSize_u16:0, SWA_State_u8:0, TTC_State_u8:0, YRS_State_u8:0, ExternalTemperature_u16:0, Reserved1_u8:0, CalculatedTireSize_u16:0, NumofManeuvers_u8:0, AbortCnd_u8:0], fields=[ManeuverType_u8:0, CurbDetected_u8:0, SideofVehicle_u8:0, Reserved_u8:0, MeasuredSlotSize_u16:0, SWA_State_u8:0, TTC_State_u8:0, YRS_State_u8:0, ExternalTemperature_u16:0, Reserved1_u8:0, CalculatedTireSize_u16:0, NumofManeuvers_u8:0, AbortCnd_u8:0], fields=[ManeuverType_u8:0, CurbDetected_u8:0, SideofVehicle_u8:0, Reserved_u8:0, MeasuredSlotSize_u16:0, SWA_State_u8:0, TTC_State_u8:0, YRS_State_u8:0, ExternalTemperature_u16:0, Reserved1_u8:0, CalculatedTireSize_u16:0, NumofManeuvers_u8:0, AbortCnd_u8:0]]]
          DID_FD86_FunctionalSettings_DefaultValue: type=FunctionalSettings_t, init-value=fields=[Oc_Control:1, Oc_Speedlimit:350, OC_ApplyResults:1, OC_Weighting:10, Framerate:30]
          DID_FDF0_SleepProcess_DefaultValue: type=uint8, init-value=0
          DID_2939_WakeupReason_DefaultValue: type=Arr_20Byte, init-value=20 x 0
          DID_FD42_FailsafeAction_DefaultValue: type=uint8, init-value=0
          DID_FD74_PHY_TuningErr_DefaultValue: type=uint16, init-value=0
          DID_FD74_BuffMarkCompErr_DefaultValue: type=uint16, init-value=0
      port-api-options:
        enable-take-address=false, error-handling=NO-TRANSFORMER-ERROR-HANDLING, indirect-api=false, port=DataServices_Data_220107_RoE_Activation_State
        enable-take-address=false, error-handling=NO-TRANSFORMER-ERROR-HANDLING, indirect-api=false, port=DataServices_Data_221002_Vehicle_Speed
        enable-take-address=false, error-handling=NO-TRANSFORMER-ERROR-HANDLING, indirect-api=false, port=DataServices_Data_221004_Battery_Voltage
        enable-take-address=false, error-handling=NO-TRANSFORMER-ERROR-HANDLING, indirect-api=false, port=DataServices_Data_221008_ECU_Life_Time
        enable-take-address=false, error-handling=NO-TRANSFORMER-ERROR-HANDLING, indirect-api=false, port=DataServices_Data_221009_ECU_Time_Since_Ignition_ON
        enable-take-address=false, error-handling=NO-TRANSFORMER-ERROR-HANDLING, indirect-api=false, port=DataServices_Data_22100B_Diagnostic_Tool_and_Session_Status
        enable-take-address=false, error-handling=NO-TRANSFORMER-ERROR-HANDLING, indirect-api=false, port=DataServices_Data_22191D_Time_of_Power_Latch
        enable-take-address=false, error-handling=NO-TRANSFORMER-ERROR-HANDLING, indirect-api=false, port=DataServices_Data_221921_Operational_Mode_Status
        enable-take-address=false, error-handling=NO-TRANSFORMER-ERROR-HANDLING, indirect-api=false, port=DataServices_Data_222001_Odometer
        enable-take-address=false, error-handling=NO-TRANSFORMER-ERROR-HANDLING, indirect-api=false, port=DataServices_Data_222002_Odometer_at_last_Flash_programming
        enable-take-address=false, error-handling=NO-TRANSFORMER-ERROR-HANDLING, indirect-api=false, port=DataServices_Data_222008_ECU_Life_Time_Not_Volatile_Memory
        enable-take-address=false, error-handling=NO-TRANSFORMER-ERROR-HANDLING, indirect-api=false, port=DataServices_Data_22200A_Ignition_ON_Counter
        enable-take-address=false, error-handling=NO-TRANSFORMER-ERROR-HANDLING, indirect-api=false, port=DataServices_Data_22200B_Time_First_DTC_Detection
        enable-take-address=false, error-handling=NO-TRANSFORMER-ERROR-HANDLING, indirect-api=false, port=DataServices_Data_22200C_Time_Since_Ignition_ON_of_first_DTC_Detection
        enable-take-address=false, error-handling=NO-TRANSFORMER-ERROR-HANDLING, indirect-api=false, port=DataServices_Data_22200D_Odometer_Last_Clear_Data_Trouble_Code_DTC
        enable-take-address=false, error-handling=NO-TRANSFORMER-ERROR-HANDLING, indirect-api=false, port=DataServices_Data_222010_Programming_Status
        enable-take-address=false, error-handling=NO-TRANSFORMER-ERROR-HANDLING, indirect-api=false, port=DataServices_Data_222945_Flow_Control_Test
        enable-take-address=false, error-handling=NO-TRANSFORMER-ERROR-HANDLING, indirect-api=false, port=DataServices_Data_224421_USS_Sensor_1_Part_Number_Read
        enable-take-address=false, error-handling=NO-TRANSFORMER-ERROR-HANDLING, indirect-api=false, port=DataServices_Data_224422_USS_Sensor2_Part_Number_Read
        enable-take-address=false, error-handling=NO-TRANSFORMER-ERROR-HANDLING, indirect-api=false, port=DataServices_Data_224423_USS_Sensor_3_Part_Number_Read
        enable-take-address=false, error-handling=NO-TRANSFORMER-ERROR-HANDLING, indirect-api=false, port=DataServices_Data_224424_USS_Sensor_4_Part_Number_Read
        enable-take-address=false, error-handling=NO-TRANSFORMER-ERROR-HANDLING, indirect-api=false, port=DataServices_Data_224425_USS_Sensor_5_Part_Number_Read
        enable-take-address=false, error-handling=NO-TRANSFORMER-ERROR-HANDLING, indirect-api=false, port=DataServices_Data_224426_USS_Sensor_6_Part_Number_Read
        enable-take-address=false, error-handling=NO-TRANSFORMER-ERROR-HANDLING, indirect-api=false, port=DataServices_Data_224427_USS_Sensor_7_Part_Number_Read
        enable-take-address=false, error-handling=NO-TRANSFORMER-ERROR-HANDLING, indirect-api=false, port=DataServices_Data_224428_USS_Sensor_8_Part_Number_Read
        enable-take-address=false, error-handling=NO-TRANSFORMER-ERROR-HANDLING, indirect-api=false, port=DataServices_Data_224429_USS_Sensor_9_Part_Number_Read
        enable-take-address=false, error-handling=NO-TRANSFORMER-ERROR-HANDLING, indirect-api=false, port=DataServices_Data_22442A_USS_Sensor_10_Part_Number_Read
        enable-take-address=false, error-handling=NO-TRANSFORMER-ERROR-HANDLING, indirect-api=false, port=DataServices_Data_22442B_USS_Sensor_11_Part_Number_Read
        enable-take-address=false, error-handling=NO-TRANSFORMER-ERROR-HANDLING, indirect-api=false, port=DataServices_Data_22442C_USS_Sensor_12_Part_Number_Read
        enable-take-address=false, error-handling=NO-TRANSFORMER-ERROR-HANDLING, indirect-api=false, port=DataServices_Data_224451_EOL_Calibration_State_Read
        enable-take-address=false, error-handling=NO-TRANSFORMER-ERROR-HANDLING, indirect-api=false, port=DataServices_Data_225100_SPM_status_Read
        enable-take-address=false, error-handling=NO-TRANSFORMER-ERROR-HANDLING, indirect-api=false, port=DataServices_Data_225300_Rear_Braking_Event_1_Read
        enable-take-address=false, error-handling=NO-TRANSFORMER-ERROR-HANDLING, indirect-api=false, port=DataServices_Data_225301_Rear_Braking_Event_2_Read
        enable-take-address=false, error-handling=NO-TRANSFORMER-ERROR-HANDLING, indirect-api=false, port=DataServices_Data_225302_Rear_Braking_Event_3_Read
        enable-take-address=false, error-handling=NO-TRANSFORMER-ERROR-HANDLING, indirect-api=false, port=DataServices_Data_225303_SPM_Event_Abort_1_Read
        enable-take-address=false, error-handling=NO-TRANSFORMER-ERROR-HANDLING, indirect-api=false, port=DataServices_Data_225304_SPM_Event_Abort_2_Read
        enable-take-address=false, error-handling=NO-TRANSFORMER-ERROR-HANDLING, indirect-api=false, port=DataServices_Data_225500_Trailer_Sense_and_Drive_Function_Data_Read
        enable-take-address=false, error-handling=NO-TRANSFORMER-ERROR-HANDLING, indirect-api=false, port=DataServices_Data_225501_Trailer_coupler_sense_detection_Function_Data_Read
        enable-take-address=false, error-handling=NO-TRANSFORMER-ERROR-HANDLING, indirect-api=false, port=DataServices_Data_22F186_Active_Diagnostic_Session
        enable-take-address=false, error-handling=NO-TRANSFORMER-ERROR-HANDLING, indirect-api=false, port=DataServices_Data_22F1A6_Message_Matrix
        enable-take-address=false, error-handling=NO-TRANSFORMER-ERROR-HANDLING, indirect-api=false, port=DataServices_Data_22FD07_OC_Result_Read
        enable-take-address=false, error-handling=NO-TRANSFORMER-ERROR-HANDLING, indirect-api=false, port=DataServices_Data_22FD08_OC_Data_Read
        enable-take-address=false, error-handling=NO-TRANSFORMER-ERROR-HANDLING, indirect-api=false, port=DataServices_Data_22FD0A_SC_Data_Read
        enable-take-address=false, error-handling=NO-TRANSFORMER-ERROR-HANDLING, indirect-api=false, port=DataServices_Data_22FD0C_Front_Camera_Data_EEPROM_Read
        enable-take-address=false, error-handling=NO-TRANSFORMER-ERROR-HANDLING, indirect-api=false, port=DataServices_Data_22FD0D_Left_Camera_Data_EEPROM_Read
        enable-take-address=false, error-handling=NO-TRANSFORMER-ERROR-HANDLING, indirect-api=false, port=DataServices_Data_22FD0E_Rear_Camera_Data_EEPROM_Read
        enable-take-address=false, error-handling=NO-TRANSFORMER-ERROR-HANDLING, indirect-api=false, port=DataServices_Data_22FD0F_Right_Camera_Data_EEPROM_Read
        enable-take-address=false, error-handling=NO-TRANSFORMER-ERROR-HANDLING, indirect-api=false, port=DataServices_Data_22FD1C_Current_Camera_Calibration_Data_Read
        enable-take-address=false, error-handling=NO-TRANSFORMER-ERROR-HANDLING, indirect-api=false, port=DataServices_Data_22FD1E_Calibration_Status_Read
        enable-take-address=false, error-handling=NO-TRANSFORMER-ERROR-HANDLING, indirect-api=false, port=DataServices_Data_22FD20_ECU_PinStates_Read
        enable-take-address=false, error-handling=NO-TRANSFORMER-ERROR-HANDLING, indirect-api=false, port=DataServices_Data_22FD28_USS_Ringing_Frequency_Read
        enable-take-address=false, error-handling=NO-TRANSFORMER-ERROR-HANDLING, indirect-api=false, port=DataServices_Data_22FD29_USS_Driving_Frequency_Read
        enable-take-address=false, error-handling=NO-TRANSFORMER-ERROR-HANDLING, indirect-api=false, port=DataServices_Data_22FD2A_USS_Ringing_Time_Read
        enable-take-address=false, error-handling=NO-TRANSFORMER-ERROR-HANDLING, indirect-api=false, port=DataServices_Data_22FD2B_USS_Direct_Distance_0xFD2B_Read
        enable-take-address=false, error-handling=NO-TRANSFORMER-ERROR-HANDLING, indirect-api=false, port=DataServices_Data_22FD2C_USS_Temperature_Read
        enable-take-address=false, error-handling=NO-TRANSFORMER-ERROR-HANDLING, indirect-api=false, port=DataServices_Data_22FD2D_USS_Sensor_ID_IME_SN_Read
        enable-take-address=false, error-handling=NO-TRANSFORMER-ERROR-HANDLING, indirect-api=false, port=DataServices_Data_22FD2E_USS_Sensor_ID_Murata_SN_Read
        enable-take-address=false, error-handling=NO-TRANSFORMER-ERROR-HANDLING, indirect-api=false, port=DataServices_Data_22FD33_Magna_Testing_2_Read
        enable-take-address=false, error-handling=NO-TRANSFORMER-ERROR-HANDLING, indirect-api=false, port=DataServices_Data_22FD42_Failsafe_Behaviour_Read
        enable-take-address=false, error-handling=NO-TRANSFORMER-ERROR-HANDLING, indirect-api=false, port=DataServices_Data_22FD48_PCBA_Temperature_Read
        enable-take-address=false, error-handling=NO-TRANSFORMER-ERROR-HANDLING, indirect-api=false, port=DataServices_Data_22FDF1_CPU_Load_Read
        enable-take-address=false, error-handling=NO-TRANSFORMER-ERROR-HANDLING, indirect-api=false, port=DataServices_Data_22FDF2_Reset_Reason_Read
        enable-take-address=false, error-handling=NO-TRANSFORMER-ERROR-HANDLING, indirect-api=false, port=DataServices_Data_2EF184_Application_Software_Fingerprint_writing_information
        enable-take-address=false, error-handling=NO-TRANSFORMER-ERROR-HANDLING, indirect-api=false, port=DataServices_Data_2EF185_Application_Data_Software_Fingerprint_Writing_Information
        enable-take-address=false, error-handling=NO-TRANSFORMER-ERROR-HANDLING, indirect-api=false, port=PpECUTimeSinceIGON
        enable-take-address=false, error-handling=NO-TRANSFORMER-ERROR-HANDLING, indirect-api=false, port=PpECUTimeStamp
        enable-take-address=false, error-handling=NO-TRANSFORMER-ERROR-HANDLING, indirect-api=false, port=PpIgOnCounter
        enable-take-address=false, error-handling=NO-TRANSFORMER-ERROR-HANDLING, indirect-api=false, port=RoEActivationCSI
        enable-take-address=false, error-handling=NO-TRANSFORMER-ERROR-HANDLING, indirect-api=false, port=RpDCMServices_GetStatus
      128 x runnable:
        RE_DIDMgr_Init
        RE_DIDMgr_Main
          data-receive-point-by-arguments:
            179 x access:
              REC_RpGetFirstDTCStatus_DeFirstDTCStatus: accessed-variable=RpGetFirstDTCStatus.DeFirstDTCStatus
              REC_RpSVSCamEOLCalib_TbSVS_S_SVSCamEOLCalibDataToNVM_t: accessed-variable=RpSVSCamEOLCalib.TbSVS_S_SVSCamEOLCalibDataToNVM_t
              REC_RpSVSCamOCCalib_TbSVS_S_SVSCamOCCalibDataToNVM_t: accessed-variable=RpSVSCamOCCalib.TbSVS_S_SVSCamOCCalibDataToNVM_t
              REC_RpSVSCamSCCalib_TbSVS_S_SVSCamSCCalibDataToNVM_t: accessed-variable=RpSVSCamSCCalib.TbSVS_S_SVSCamSCCalibDataToNVM_t
              REC_RpSVSOutputToDiagMgr_TbSVS_e_SVSOutputToDiagMgrCamCalib_t: accessed-variable=RpSVSOutputToDiagMgr.TbSVS_e_SVSOutputToDiagMgrCamCalib_t
              REC_RpUSSConstantData_US_S_USSConstantData_t: accessed-variable=RpUSSConstantData.US_S_USSConstantData_t
              REC_RpUSSPeriodDiagData_US_S_USSPeriodDiagData_t: accessed-variable=RpUSSPeriodDiagData.US_S_USSPeriodDiagData_t
              REC_RpSnrDirEcho_US_S_SnrDirEcho_t: accessed-variable=RpSnrDirEcho.US_S_SnrDirEcho_t
              REC_RpSVSCamCurrentCalib_TbSVS_S_SVSCamCurrentCalibDataToNVM_t: accessed-variable=RpSVSCamCurrentCalib.TbSVS_S_SVSCamCurrentCalibDataToNVM_t
              REC_RpCamEepromData_Svs_CamEepromDataArray_t: accessed-variable=RpCamEepromData.Svs_CamEepromDataArray_t
              REC_RpNVMCamCalibSM_TbSVS_e_SVSOutputToNVMCamCalibSM_t: accessed-variable=RpNVMCamCalibSM.TbSVS_e_SVSOutputToNVMCamCalibSM_t
              REC_RpCalDataProviderNvmData_CalData_mcu1_0: accessed-variable=RpCalDataProviderNvmData.CalData_mcu1_0
              REC_Rp_TrailerDetectOP_TrailerDetection_Output_DID_t: accessed-variable=RpTrailerDetectOP.TrailerDetection_Output_DID_t
              REC_Rp_TrscToDiag_TRSCtoDiagMgr_t: accessed-variable=RpTrscToDiag.TRSCtoDiagMgr_t
              REC_RpTRSC_ME_VehOut_TRSC_t: accessed-variable=RpTRSC.ME_VehOut_TRSC_t
              REC_RpSMDAInternal_TbAP_SMDAInternalOut_t: accessed-variable=RpSMDAInternal.TbAP_SMDAInternalOut_t
              REC_RpVCState_TbAP_VCStateOut_t: accessed-variable=RpVCState.TbAP_VCStateOut_t
              REC_RpPAStateOut_TbAP_PAStateOut_t: accessed-variable=RpPAStateOut.TbAP_PAStateOut_t
              REC_RpRPAWarnOut_TbAP_RPAWarnOut_t: accessed-variable=RpRPAWarnOut.TbAP_RPAWarnOut_t
              REC_RpFeatureOutputsTHA_TbTHASmVc_FeatureOutputs_t: accessed-variable=RpFeatureOutputsTHA.TbTHASmVc_FeatureOutputs_t
              REC_RpJobFPAData_IJobFPAOutput_t: accessed-variable=RpJobFPAData.IJobFPAOutput_t
              REC_RpJobPLDData_IJobPLDOutput_t: accessed-variable=RpJobPLDData.IJobPLDOutput_t
              REC_RpUSSBlockageBit_US_S_BlockageBit_t: accessed-variable=RpUSSBlockageBit.US_S_BlockageBit_t
              REC_RpScreenRequest_ScreenRequest_t: accessed-variable=RpScreenRequest.ScreenRequest_t
              REC_RpProxiToSWC_TyreSz_u16: accessed-variable=RpProxiToSWC.TyreSz_u16
              REC_RpSvsToVCAN_SvsToVCAN_t: accessed-variable=RpSvsToVCAN.SvsToVCAN_t
              REC_RpCpuLoadMcu2_0_CpuLoadMcu2_0_t: accessed-variable=RpCpuLoadMcu2_0.CpuLoadMcu2_0_t
              REC_RpCpuLoadMcu2_1_CpuLoadMcu2_1_t: accessed-variable=RpCpuLoadMcu2_1.CpuLoadMcu2_1_t
              REC_RpPointDistOpBuff_US_S_PointDistOutputBuff_t: accessed-variable=RpPointDistOpBuff.US_S_PointDistOutputBuff_t
              REC_RpUSSErrorDiagData_US_S_USSErrorDiagData_t: accessed-variable=RpUSSErrorDiagData.US_S_USSErrorDiagData_t
              REC_RpJobTHADetOutput_JobTHADetOutput_t: accessed-variable=RpJobTHADetOutput.JobTHADetOutput_t
              REC_RpSvsToTHA_SvsToTHA_t: accessed-variable=RpSvsToTHA.SvsToTHA_t
              REC_RpProxiToSWC_SurroundViewCam_u8: accessed-variable=RpProxiToSWC.SurroundViewCam_u8
              REC_RpTbTHASmVcDiag_TbTHASmVc_DiagMgr_t: accessed-variable=RpTbTHASmVcDiag.TbTHASmVc_DiagMgr_t
              REC_RpCamCsData_CAM_CS_Curr_Monitor_t: accessed-variable=RpCamCsData.CAM_CS_Curr_Monitor_t
              REC_RpUssPowerData_UssPower: accessed-variable=RpUssPowerData.UssPower
              REC_RpVariantData_Variant: accessed-variable=RpVariantData.Variant
              REC_RpProxiConfigData_ProxiData: accessed-variable=RpProxiConfigData.ProxiData
              REC_RpVINData_VINLockStatus: accessed-variable=RpVINData.VINLockStatus
              REC_RpVINData_VINOdoCounter: accessed-variable=RpVINData.VINOdoCounter
              REC_RpVINData_VINOriginalData: accessed-variable=RpVINData.VINOriginalData
              REC_RpPlantMode_Status: accessed-variable=RpPlantMode.Status
              REC_RpVINData_VINCurrentData: accessed-variable=RpVINData.VINCurrentData
              REC_RpProxiErrorData_Error: accessed-variable=RpProxiErrorData.Error
              REC_RpToSwcSafeFD02Rx_CmdIgnSts: accessed-variable=RpToSwcSafeFD02Rx.CmdIgnSts
              REC_RpToSwcSafeFD02Rx_ExternalTemperature: accessed-variable=RpToSwcSafeFD02Rx.ExternalTemperature
              REC_RpToSwcSafeFD14Rx_FD14_LwsAngle: accessed-variable=RpToSwcSafeFD14Rx.FD14_LwsAngle
              REC_RpToSwcSafeFD14Rx_FD14_VehicleSpeedVSOSig: accessed-variable=RpToSwcSafeFD14Rx.FD14_VehicleSpeedVSOSig
              REC_RpToSwcSafeFD14Rx_FD14_VehicleStandStillSts: accessed-variable=RpToSwcSafeFD14Rx.FD14_VehicleStandStillSts
              REC_RpToSwcSafeFD02Rx_ShiftLeverPosition: accessed-variable=RpToSwcSafeFD02Rx.ShiftLeverPosition
              REC_RpToSwcFD02Rx_OperationalModeSts: accessed-variable=RpToSwcFD02Rx.OperationalModeSts
              REC_RpToSwcFD02Rx_TotalOdometer: accessed-variable=RpToSwcFD02Rx.TotalOdometer
              REC_RpToSwcSafeFD14Rx_FD14_PAM_Brk_Rq_RspSts: accessed-variable=RpToSwcSafeFD14Rx.FD14_PAM_Brk_Rq_RspSts
              REC_RpToSwcSafeFD14Rx_FD14_LatAcceleration_BSM: accessed-variable=RpToSwcSafeFD14Rx.FD14_LatAcceleration_BSM
              REC_RpToSwcSafeFD14Rx_FD14_LatAccelerationFailSts_BSM: accessed-variable=RpToSwcSafeFD14Rx.FD14_LatAccelerationFailSts_BSM
              REC_RpToSwcSafeFD14Rx_FD14_LongAccelerationFailSts_BSM: accessed-variable=RpToSwcSafeFD14Rx.FD14_LongAccelerationFailSts_BSM
              REC_RpToSwcSafeFD14Rx_FD14_LongAcceleration_BSM: accessed-variable=RpToSwcSafeFD14Rx.FD14_LongAcceleration_BSM
              REC_RpToSwcSafeFD14Rx_FD14_YawRate_BSM: accessed-variable=RpToSwcSafeFD14Rx.FD14_YawRate_BSM
              REC_RpToSwcSafeFD14Rx_FD14_YawRateFailSts_BSM: accessed-variable=RpToSwcSafeFD14Rx.FD14_YawRateFailSts_BSM
              REC_RpToSwcSafeFD14Rx_FD14_EPS_HandsOnRecognition: accessed-variable=RpToSwcSafeFD14Rx.FD14_EPS_HandsOnRecognition
              REC_RpToSwcSafeFD14Rx_FD14_SPM_Lat_Ctrl_ResponseSts: accessed-variable=RpToSwcSafeFD14Rx.FD14_SPM_Lat_Ctrl_ResponseSts
              REC_RpToSwcSafeFD14Rx_FD14_Steering_Column_Torque: accessed-variable=RpToSwcSafeFD14Rx.FD14_Steering_Column_Torque
              REC_RpToSwcSafeFD14Rx_FD14_LHF_FastPulseCounter: accessed-variable=RpToSwcSafeFD14Rx.FD14_LHF_FastPulseCounter
              REC_RpToSwcSafeFD14Rx_FD14_LHF_Spin: accessed-variable=RpToSwcSafeFD14Rx.FD14_LHF_Spin
              REC_RpToSwcSafeFD14Rx_FD14_LHF_WheelSensorFailSts: accessed-variable=RpToSwcSafeFD14Rx.FD14_LHF_WheelSensorFailSts
              REC_RpToSwcSafeFD14Rx_FD14_LHR_FastPulseCounter: accessed-variable=RpToSwcSafeFD14Rx.FD14_LHR_FastPulseCounter
              REC_RpToSwcSafeFD14Rx_FD14_LHR_WheelSensorFailSts: accessed-variable=RpToSwcSafeFD14Rx.FD14_LHR_WheelSensorFailSts
              REC_RpToSwcSafeFD14Rx_FD14_RHF_FastPulseCounter: accessed-variable=RpToSwcSafeFD14Rx.FD14_RHF_FastPulseCounter
              REC_RpToSwcSafeFD14Rx_FD14_RHF_Spin: accessed-variable=RpToSwcSafeFD14Rx.FD14_RHF_Spin
              REC_RpToSwcSafeFD14Rx_FD14_RHF_WheelSensorFailSts: accessed-variable=RpToSwcSafeFD14Rx.FD14_RHF_WheelSensorFailSts
              REC_RpToSwcSafeFD14Rx_FD14_RHR_FastPulseCounter: accessed-variable=RpToSwcSafeFD14Rx.FD14_RHR_FastPulseCounter
              REC_RpToSwcSafeFD14Rx_FD14_RHR_WheelSensorFailSts: accessed-variable=RpToSwcSafeFD14Rx.FD14_RHR_WheelSensorFailSts
              REC_RpToSwcSafeFD14Rx_FD14_LHFWheelSpeed: accessed-variable=RpToSwcSafeFD14Rx.FD14_LHFWheelSpeed
              REC_RpToSwcSafeFD14Rx_FD14_LHRWheelSpeed: accessed-variable=RpToSwcSafeFD14Rx.FD14_LHRWheelSpeed
              REC_RpToSwcSafeFD14Rx_FD14_RHFWheelSpeed: accessed-variable=RpToSwcSafeFD14Rx.FD14_RHFWheelSpeed
              REC_RpToSwcSafeFD14Rx_FD14_RHRWheelSpeed: accessed-variable=RpToSwcSafeFD14Rx.FD14_RHRWheelSpeed
              REC_RpToSwcSafeFD14Rx_FD14_LwsAngleType: accessed-variable=RpToSwcSafeFD14Rx.FD14_LwsAngleType
              REC_RpToSwcSafeFD14Rx_FD14_LwsSpeed: accessed-variable=RpToSwcSafeFD14Rx.FD14_LwsSpeed
              REC_RpToSwcSafeFD14Rx_FD14_VehicleSpeedVSOSig_B2: accessed-variable=RpToSwcSafeFD14Rx.FD14_VehicleSpeedVSOSig_B2
              REC_RpToSwcFD02Rx_IgnitionOnCounter: accessed-variable=RpToSwcFD02Rx.IgnitionOnCounter
              REC_RpToSwcFD02Rx_TurnIndicatorSts: accessed-variable=RpToSwcFD02Rx.TurnIndicatorSts
              REC_RpToSwcSafeFD02Rx_PamChimeVolumeFront: accessed-variable=RpToSwcSafeFD02Rx.PamChimeVolumeFront
              REC_RpToSwcSafeFD02Rx_PamChimeVolumeRear: accessed-variable=RpToSwcSafeFD02Rx.PamChimeVolumeRear
              REC_RpToSwcFD02Rx_RemStActvSts: accessed-variable=RpToSwcFD02Rx.RemStActvSts
              REC_RpToSwcSafeFD02Rx_RHatchSts: accessed-variable=RpToSwcSafeFD02Rx.RHatchSts
              REC_RpToSwcSafeFD02Rx_VehicleSpeedVSOSig: accessed-variable=RpToSwcSafeFD02Rx.VehicleSpeedVSOSig
              REC_RpToSwcSafeFD02Rx_Rear_Brk_Asst: accessed-variable=RpToSwcSafeFD02Rx.Rear_Brk_Asst
              REC_RpToSwcSafeFD02Rx_TargetGear: accessed-variable=RpToSwcSafeFD02Rx.TargetGear
              REC_RpToSwcSafeFD02Rx_TCASERANGESTATUS: accessed-variable=RpToSwcSafeFD02Rx.TCASERANGESTATUS
              REC_RpToSwcSafeFD02Rx_LwsAngle: accessed-variable=RpToSwcSafeFD02Rx.LwsAngle
              REC_RpToSwcSafeFD02Rx_LwsSpeed: accessed-variable=RpToSwcSafeFD02Rx.LwsSpeed
              REC_RpToSwcSafeFD02Rx_APARequestSts: accessed-variable=RpToSwcSafeFD02Rx.APARequestSts
              REC_RpToSwcSafeFD02Rx_PAMRequestSts: accessed-variable=RpToSwcSafeFD02Rx.PAMRequestSts
              REC_RpToSwcSafeFD02Rx_TrailerConnectionSts: accessed-variable=RpToSwcSafeFD02Rx.TrailerConnectionSts
              REC_RpToSwcSafeFD02Rx_LanguageSelection: accessed-variable=RpToSwcSafeFD02Rx.LanguageSelection
              REC_RpToSwcSafeFD02Rx_Fwrd_Cam_Guidelines: accessed-variable=RpToSwcSafeFD02Rx.Fwrd_Cam_Guidelines
              REC_RpToSwcSafeFD02Rx_SVC_Guidelines: accessed-variable=RpToSwcSafeFD02Rx.SVC_Guidelines
              REC_RpToSwcSafeFD02Rx_TGW_CAMERA_DISP_STAT: accessed-variable=RpToSwcSafeFD02Rx.TGW_CAMERA_DISP_STAT
              REC_RpToSwcSafeFD02Rx_DriverDoorSts: accessed-variable=RpToSwcSafeFD02Rx.DriverDoorSts
              REC_RpToSwcSafeFD02Rx_LHRDoorSts: accessed-variable=RpToSwcSafeFD02Rx.LHRDoorSts
              REC_RpToSwcSafeFD02Rx_PsngrDoorSts: accessed-variable=RpToSwcSafeFD02Rx.PsngrDoorSts
              REC_RpToSwcSafeFD02Rx_RHRDoorSts: accessed-variable=RpToSwcSafeFD02Rx.RHRDoorSts
              REC_RpToSwcFD02Rx_EPBSts: accessed-variable=RpToSwcFD02Rx.EPBSts
              REC_RpToSwcSafeFD02Rx_Brk_Stat: accessed-variable=RpToSwcSafeFD02Rx.Brk_Stat
              REC_RpToSwcFD02Tx_CurrentFailSts_FD02_PAM: accessed-variable=RpToSwcFD02Tx.CurrentFailSts_FD02_PAM
              REC_RpToSwcFD02Tx_GenericFailSts_FD02_PAM: accessed-variable=RpToSwcFD02Tx.GenericFailSts_FD02_PAM
              REC_RpToSwcSafeFD02Tx_Alert_CHF: accessed-variable=RpToSwcSafeFD02Tx.Alert_CHF
              REC_RpToSwcSafeFD02Tx_Alert_CHR: accessed-variable=RpToSwcSafeFD02Tx.Alert_CHR
              REC_RpToSwcSafeFD02Tx_Alert_LHF: accessed-variable=RpToSwcSafeFD02Tx.Alert_LHF
              REC_RpToSwcSafeFD02Tx_Alert_LHR: accessed-variable=RpToSwcSafeFD02Tx.Alert_LHR
              REC_RpToSwcSafeFD02Tx_Alert_RHF: accessed-variable=RpToSwcSafeFD02Tx.Alert_RHF
              REC_RpToSwcSafeFD02Tx_Alert_RHR: accessed-variable=RpToSwcSafeFD02Tx.Alert_RHR
              REC_RpToSwcSafeFD02Tx_ChimeActivation_LHF: accessed-variable=RpToSwcSafeFD02Tx.ChimeActivation_LHF
              REC_RpToSwcSafeFD02Tx_ChimeActivation_LHR: accessed-variable=RpToSwcSafeFD02Tx.ChimeActivation_LHR
              REC_RpToSwcSafeFD02Tx_ChimeActivation_RHF: accessed-variable=RpToSwcSafeFD02Tx.ChimeActivation_RHF
              REC_RpToSwcSafeFD02Tx_ChimeActivation_RHR: accessed-variable=RpToSwcSafeFD02Tx.ChimeActivation_RHR
              REC_RpToSwcSafeFD02Tx_DisplayView2: accessed-variable=RpToSwcSafeFD02Tx.DisplayView2
              REC_RpToSwcSafeFD02Tx_FrontSensorSts: accessed-variable=RpToSwcSafeFD02Tx.FrontSensorSts
              REC_RpToSwcSafeFD02Tx_Graphic_CHF: accessed-variable=RpToSwcSafeFD02Tx.Graphic_CHF
              REC_RpToSwcSafeFD02Tx_Graphic_CHR: accessed-variable=RpToSwcSafeFD02Tx.Graphic_CHR
              REC_RpToSwcSafeFD02Tx_Graphic_LHF: accessed-variable=RpToSwcSafeFD02Tx.Graphic_LHF
              REC_RpToSwcSafeFD02Tx_Graphic_LHR: accessed-variable=RpToSwcSafeFD02Tx.Graphic_LHR
              REC_RpToSwcSafeFD02Tx_Graphic_RHF: accessed-variable=RpToSwcSafeFD02Tx.Graphic_RHF
              REC_RpToSwcSafeFD02Tx_Graphic_RHR: accessed-variable=RpToSwcSafeFD02Tx.Graphic_RHR
              REC_RpToSwcSafeFD02Tx_HMICode: accessed-variable=RpToSwcSafeFD02Tx.HMICode
              REC_RpToSwcSafeFD02Tx_ImageDefeatRQSts: accessed-variable=RpToSwcSafeFD02Tx.ImageDefeatRQSts
              REC_RpToSwcSafeFD02Tx_PAM_CHIME_REP_RATESts: accessed-variable=RpToSwcSafeFD02Tx.PAM_CHIME_REP_RATESts
              REC_RpToSwcSafeFD02Tx_PAM_CHIME_TYPE: accessed-variable=RpToSwcSafeFD02Tx.PAM_CHIME_TYPE
              REC_RpToSwcSafeFD02Tx_PAM_LedControlSts: accessed-variable=RpToSwcSafeFD02Tx.PAM_LedControlSts
              REC_RpToSwcSafeFD02Tx_PAM_Off_Status: accessed-variable=RpToSwcSafeFD02Tx.PAM_Off_Status
              REC_RpToSwcSafeFD02Tx_PAM_PopUpRqst: accessed-variable=RpToSwcSafeFD02Tx.PAM_PopUpRqst
              REC_RpToSwcSafeFD02Tx_PAM_Volume: accessed-variable=RpToSwcSafeFD02Tx.PAM_Volume
              REC_RpToSwcSafeFD02Tx_RR_PAM_Brk_RqSts: accessed-variable=RpToSwcSafeFD02Tx.RR_PAM_Brk_RqSts
              REC_RpToSwcSafeFD02Tx_SPM_LedControlSts: accessed-variable=RpToSwcSafeFD02Tx.SPM_LedControlSts
              REC_RpToSwcSafeFD02Tx_SPMControlSts: accessed-variable=RpToSwcSafeFD02Tx.SPMControlSts
              REC_RpToSwcSafeFD02Tx_SPMFailSts: accessed-variable=RpToSwcSafeFD02Tx.SPMFailSts
              REC_RpToSwcSafeFD02Tx_RR_PAM_Dist: accessed-variable=RpToSwcSafeFD02Tx.RR_PAM_Dist
              REC_RpToSwcSafeFD02Tx_RR_PAM_StopControlSts: accessed-variable=RpToSwcSafeFD02Tx.RR_PAM_StopControlSts
              REC_RpToSwcSafeFD02Tx_SPMSystemFault: accessed-variable=RpToSwcSafeFD02Tx.SPMSystemFault
              REC_RpToSwcSafeFD02Tx_SPM_Screen_Rqst: accessed-variable=RpToSwcSafeFD02Tx.SPM_Screen_Rqst
              REC_RpToSwcSafeFD02Tx_PAMSystemFault: accessed-variable=RpToSwcSafeFD02Tx.PAMSystemFault
              REC_RpToSwcSafeFD02Tx_RearSensorSts: accessed-variable=RpToSwcSafeFD02Tx.RearSensorSts
              REC_RpToSwcSafeFD14Tx_FD14_ManoeuvrePhase: accessed-variable=RpToSwcSafeFD14Tx.FD14_ManoeuvrePhase
              REC_RpToSwcSafeFD14Tx_FD14_RR_PAM_Brk_RqSts: accessed-variable=RpToSwcSafeFD14Tx.FD14_RR_PAM_Brk_RqSts
              REC_RpToSwcSafeFD14Tx_FD14_RR_PAM_Dist: accessed-variable=RpToSwcSafeFD14Tx.FD14_RR_PAM_Dist
              REC_RpToSwcSafeFD14Tx_FD14_SPM_Lat_Ctrl_RequestSts: accessed-variable=RpToSwcSafeFD14Tx.FD14_SPM_Lat_Ctrl_RequestSts
              REC_RpToSwcSafeFD14Tx_FD14_TorqueOverlaySteeringReq_SPM: accessed-variable=RpToSwcSafeFD14Tx.FD14_TorqueOverlaySteeringReq_SPM
              REC_RpMEProxi_ME_Proxi_MPU1_0_to_MCU1_0_t: accessed-variable=RpMEProxi.ME_Proxi_MPU1_0_to_MCU1_0_t
              REC_RpCamSerENStat_Cam_and_Ser_EN_Status_t: accessed-variable=RpCamSerENStat.Cam_and_Ser_EN_Status_t
              REC_RpMPUFaultStatus_Sts: accessed-variable=RpMPUFaultStatus.Sts
              REC_RpPMICFaultstatus_Sts: accessed-variable=RpPMICFaultstatus.Sts
              REC_RpSDLFaultstatus_Sts: accessed-variable=RpSDLFaultstatus.Sts
              REC_RpWDGFaultStatus_Sts: accessed-variable=RpWDGFaultStatus.Sts
              REC_RpToSwcSafeFD02Rx_ASCM_Stat: accessed-variable=RpToSwcSafeFD02Rx.ASCM_Stat
              REC_RpToSwcSafeFD02Rx_EngineSts_W: accessed-variable=RpToSwcSafeFD02Rx.EngineSts_W
              REC_RpToSwcSafeFD02Rx_VIN_DATA: accessed-variable=RpToSwcSafeFD02Rx.VIN_DATA
              REC_RpToSwcSafeFD02Rx_VIN_MSG: accessed-variable=RpToSwcSafeFD02Rx.VIN_MSG
              REC_RpToSwcSafeFD14Rx_FD14_ESS_ENG_ST_W: accessed-variable=RpToSwcSafeFD14Rx.FD14_ESS_ENG_ST_W
              REC_RpToSwcSafeFD14Rx_FD14_PdlPosActual: accessed-variable=RpToSwcSafeFD14Rx.FD14_PdlPosActual
              REC_RpToSwcSafeFD02Rx_CameraDisplaySts2: accessed-variable=RpToSwcSafeFD02Rx.CameraDisplaySts2
              REC_RpToSwcSafeFD02Rx_CM_TCH_STAT: accessed-variable=RpToSwcSafeFD02Rx.CM_TCH_STAT
              REC_RpToSwcSafeFD02Rx_CM_TCH_X_COORD: accessed-variable=RpToSwcSafeFD02Rx.CM_TCH_X_COORD
              REC_RpToSwcSafeFD02Rx_CM_TCH_Y_COORD: accessed-variable=RpToSwcSafeFD02Rx.CM_TCH_Y_COORD
              REC_R_Errors_B_Errors_B: accessed-variable=RpErrors_B.Errors_B
              REC_R_Errors_QM_Errors_QM: accessed-variable=RpErrors_QM.Errors_QM
              REC_RpToSwcSafeFD02Rx_GearEngaged: accessed-variable=RpToSwcSafeFD02Rx.GearEngaged
              REC_Rp_DLDOutput_JobDLDOutput_t: accessed-variable=Rp_DLDOutput.JobDLDOutput_t
              REC_RpSafeState2RSTReason_FaultEnum_u16: accessed-variable=RpSafeState2RSTReason.FaultEnum_u16
              REC_Rp_SafeState_SR_SafeStateOp: accessed-variable=Rp_SafeState_SR.SafeStateOp
              REC_Rp_VIN_MessageFault_VIN_InvalidValueFlag: accessed-variable=RpVIN_MessageFault.VIN_InvalidValueFlag
              REC_Rp_VIN_MessageFault_VIN_MissingMessageFlag: accessed-variable=RpVIN_MessageFault.VIN_MissingMessageFlag
              REC_RpRunTimeStats_MCU2_0_RunTimeStats_MCU2_0_t: accessed-variable=RpRunTimeStats_MCU2_0.RunTimeStats_MCU2_0_t
              REC_RpRunTimeStats_MCU2_1_RunTimeStats_MCU2_1_t: accessed-variable=RpRunTimeStats_MCU2_1.RunTimeStats_MCU2_1_t
              REC_RpRunTimeStats_MPU1_0_RunTimeStats_MPU1_0_t: accessed-variable=RpRunTimeStats_MPU1_0.RunTimeStats_MPU1_0_t
              REC_RpUssTunData_UssTunningData_mcu2_1_t: accessed-variable=RpUssTunData.UssTunningData_mcu2_1_t
              REC_RpCalibRoutineTrigger_routine_b: accessed-variable=RpCalibRoutineTrigger.routine_b
              REC_RpPreviousCamData_Data: accessed-variable=RpPreviousCamData.Data
              REC_RpStackUsage_MCU2_0_StackUsage_MCU2_0_t: accessed-variable=RpStackUsage_MCU2_0.StackUsage_MCU2_0_t
              REC_RpStackUsage_MCU2_1_StackUsage_MCU2_1_t: accessed-variable=RpStackUsage_MCU2_1.StackUsage_MCU2_1_t
          data-send-points:
            12 x access:
              SEND_PpECUTimeSinceIGON_ECUTimeStamp_IGON: accessed-variable=PpECUTimeSinceIGON.ECUTimeStamp_IGON
              SEND_PpECUTimeStamp_ECUTimeStamp: accessed-variable=PpECUTimeStamp.ECUTimeStamp
              SEND_PpIgOnCounter_IGCounter: accessed-variable=PpIgOnCounter.IGCounter
              SEND_PpSleepProcessState_status: accessed-variable=PpSleepProcessState.status
              SEND_PpGearPosition_GearValue: accessed-variable=PpGearPosition.GearValue
              SEND_PpGearPosition_ShortTermAdjActiveFlag_b: accessed-variable=PpGearPosition.ShortTermAdjActiveFlag_b
              SEND_PpFailsafeAction_FailSafe_State: accessed-variable=PpFailsafeAction.FailSafe_State
              SEND_PpFailsafeDebug_Debugflag: accessed-variable=PpFailsafeDebug.Debugflag
              SEND_PpResetNvmFlag_V_ResetNvmFlag_b: accessed-variable=PpResetNvmFlag.V_ResetNvmFlag_b
              SEND_Pp_PlantOdoData_PlantOdoData: accessed-variable=Pp_PlantOdoData.PlantOdoData
              SEND_PpPerformanceStatsEnable_RunTimeStatsEnable: accessed-variable=PpPerformanceStatsEnable.RunTimeStatsEnable
              SEND_PpPerformanceStatsEnable_StackUsageStatsEnable: accessed-variable=PpPerformanceStatsEnable.StackUsageStatsEnable
          40 x sync call:
            SC_NvMService_AC3_SRBS_vRoE_Activation_State_ReadBlock: operation=NvMService_AC3_SRBS_vRoE_Activation_State.ReadBlock
            SC_NvMService_AC3_SRBS_DID_191D_PowerLatch_SetRamBlockStatus: operation=NvMService_AC3_SRBS_DID_191D_PowerLatch.SetRamBlockStatus
            SC_NvMService_AC3_SRBS_DID_200A_IgOnCounter_SetRamBlockStatus: operation=NvMService_AC3_SRBS_DID_200A_IgOnCounter.SetRamBlockStatus
            SC_NvMService_AC3_SRBS_DID_200B_TimeSinceFirstDTC_SetRamBlockStatus: operation=NvMService_AC3_SRBS_DID_200B_TimeSinceFirstDTC.SetRamBlockStatus
            SC_NvMService_AC3_SRBS_DID_200C_TimeSinceIgnOnFirstDTC_SetRamBlockStatus: operation=NvMService_AC3_SRBS_DID_200C_TimeSinceIgnOnFirstDTC.SetRamBlockStatus
            SC_NvMService_AC3_SRBS_DID_200D_LastClearDTCOdo_SetRamBlockStatus: operation=NvMService_AC3_SRBS_DID_200D_LastClearDTCOdo.SetRamBlockStatus
            SC_NvMService_AC3_SRBS_DID_2002_OdoFlashing_SetRamBlockStatus: operation=NvMService_AC3_SRBS_DID_2002_OdoFlashing.SetRamBlockStatus
            SC_NvMService_AC3_SRBS_DID_2002_ProgReqFlag_SetRamBlockStatus: operation=NvMService_AC3_SRBS_DID_2002_ProgReqFlag.SetRamBlockStatus
            SC_NvMService_AC3_SRBS_DID_FD33_MagnaTesting_SetRamBlockStatus: operation=NvMService_AC3_SRBS_DID_FD33_MagnaTesting.SetRamBlockStatus
            SC_NvMService_AC3_SRBS_ECU_LifeTime_SetRamBlockStatus: operation=NvMService_AC3_SRBS_ECU_LifeTime.SetRamBlockStatus
            SC_NvMService_AC3_SRBS_vRoE_Activation_State_SetRamBlockStatus: operation=NvMService_AC3_SRBS_vRoE_Activation_State.SetRamBlockStatus
            SC_NvMService_AC3_SRBS_vRoE_Activation_State_WriteBlock: operation=NvMService_AC3_SRBS_vRoE_Activation_State.WriteBlock
            SC_RpReadVoltInfo_GetVoltageInfo: operation=RpReadVoltInfo.GetVoltageInfo
            SC_RoEActivationCSI_WriteData: operation=RoEActivationCSI.WriteData
            SC_RpDCMServices_GetStatus_GetSesCtrlType: operation=RpDCMServices_GetStatus.GetSesCtrlType
            SC_RpCalDataProvider_Nvm_SVSCamCurrentCalibData_WriteBlock: operation=RpCalDataProvider_Nvm_SVSCamCurrentCalibData.WriteBlock
            SC_RpCalDataProvider_Nvm_SVSCamEOLCalibData_WriteBlock: operation=RpCalDataProvider_Nvm_SVSCamEOLCalibData.WriteBlock
            SC_RpCalDataProvider_Nvm_SVSCamOCCalibData_WriteBlock: operation=RpCalDataProvider_Nvm_SVSCamOCCalibData.WriteBlock
            SC_RpCalDataProvider_Nvm_SVSCamSCCalibData_WriteBlock: operation=RpCalDataProvider_Nvm_SVSCamSCCalibData.WriteBlock
            SC_NvMService_AC3_SRBS_DID_FD01_PrevCalibDataCopy_SetRamBlockStatus: operation=NvMService_AC3_SRBS_DID_FD01_PrevCalibDataCopy.SetRamBlockStatus
            SC_NvMService_AC3_SRBS_DID_RearBrakeEvent_ReadBlock: operation=NvMService_AC3_SRBS_DID_RearBrakeEvent.ReadBlock
            SC_NvMService_AC3_SRBS_DID_RearBrakeEvent_WriteBlock: operation=NvMService_AC3_SRBS_DID_RearBrakeEvent.WriteBlock
            SC_NvMService_AC3_SRBS_DID_SPMAbrtEvent_ReadBlock: operation=NvMService_AC3_SRBS_DID_SPMAbrtEvent.ReadBlock
            SC_NvMService_AC3_SRBS_DID_SPMAbrtEvent_WriteBlock: operation=NvMService_AC3_SRBS_DID_SPMAbrtEvent.WriteBlock
            SC_IF_CryptoArray_CryptoArray: operation=RpCryptoArray.CryptoArray
            SC_RpError_CS_B_ReportErrorStatus1_0_B: operation=RpError_CS_B.ReportErrorStatus1_0_B
            SC_RpError_CS_QM_ReportErrorStatus1_0_QM: operation=RpError_CS_QM.ReportErrorStatus1_0_QM
            SC_NvMService_AC3_SRBS_DID_FD86_FunctionalSettings_SetRamBlockStatus: operation=NvMService_AC3_SRBS_DID_FD86_FunctionalSettings.SetRamBlockStatus
            SC_NvMService_AC3_SRBS_DID_FDF0_SleepProcess_WriteBlock: operation=NvMService_AC3_SRBS_DID_FDF0_SleepProcess.WriteBlock
            SC_Rp2023_ProxiData_WriteData: operation=Rp2023_ProxiData.WriteData
            SC_NvMService_AC3_SRBS_DID_2939_WakeupReason_SetRamBlockStatus: operation=NvMService_AC3_SRBS_DID_2939_WakeupReason.SetRamBlockStatus
            SC_RpIpcTxData_IPC_Write_v: operation=RpIpcTxData.IPC_Write_v
            SC_RpClearDTCSettingStatus_ClearDTCSettingStatus: operation=RpClearDTCSettingStatus.ClearDTCSettingStatus
            SC_NvMService_AC3_SRBS_DID_FDF0_SleepProcess_GetErrorStatus: operation=NvMService_AC3_SRBS_DID_FDF0_SleepProcess.GetErrorStatus
            SC_NvMService_AC3_SRBS_DID_RearBrakeEvent_GetErrorStatus: operation=NvMService_AC3_SRBS_DID_RearBrakeEvent.GetErrorStatus
            SC_NvMService_AC3_SRBS_DID_SPMAbrtEvent_GetErrorStatus: operation=NvMService_AC3_SRBS_DID_SPMAbrtEvent.GetErrorStatus
            SC_NvMService_AC3_SRBS_vRoE_Activation_State_GetErrorStatus: operation=NvMService_AC3_SRBS_vRoE_Activation_State.GetErrorStatus
            SC_RpIntrinsicCameraSN_Readblock: operation=RpIntrinsicCameraSN.Readblock
            SC_RpRunTimeStatCSData_Cdd_RunTimeStatQM_GetData: operation=RpRunTimeStatCSData.Cdd_RunTimeStatQM_GetData
            SC_RpGetTaskStackUsage_Data: operation=RpGetTaskStackUsage.Data
        DataServices_Data_22FD0A_SC_Data_Read_WriteData
        DataServices_Data_22FD0A_SC_Data_Read_ReadData
        DataServices_Data_225500_Trailer_Sense_and_Drive_Function_Data_Read_ReadData
        DataServices_Data_222945_Flow_Control_Test_WriteData
        DataServices_Data_222945_Flow_Control_Test_ReadData
        DataServices_Data_225303_SPM_Event_Abort_1_Read_ReadData
        DataServices_Data_22191D_Time_of_Power_Latch_ReadData
        DataServices_Data_22100B_Diagnostic_Tool_and_Session_Status_ReadData
        DataServices_Data_224451_EOL_Calibration_State_Read_ReadData
        DataServices_Data_22FD1C_Current_Camera_Calibration_Data_Read_ReadData
        DataServices_Data_225304_SPM_Event_Abort_2_Read_ReadData
        DataServices_Data_22FD2D_USS_Sensor_ID_IME_SN_Read_ReadData
        DataServices_Data_22FD0D_Left_Camera_Data_EEPROM_Read_ReadData
        DataServices_Data_22200D_Odometer_Last_Clear_Data_Trouble_Code_DTC_ReadData
        DataServices_Data_22FD0F_Right_Camera_Data_EEPROM_Read_ReadData
        DataServices_Data_225301_Rear_Braking_Event_2_Read_ReadData
        DataServices_Data_225302_Rear_Braking_Event_3_Read_ReadData
        DataServices_Data_22FD08_OC_Data_Read_WriteData
        DataServices_Data_22FD08_OC_Data_Read_ReadData
        DataServices_Data_220107_RoE_Activation_State_WriteData
        DataServices_Data_220107_RoE_Activation_State_ReadData
        DataServices_Data_224423_USS_Sensor_3_Part_Number_Read_ReadData
        DataServices_Data_222010_Programming_Status_ReadData
        DataServices_Data_221008_ECU_Life_Time_ReadData
        DataServices_Data_22FD2C_USS_Temperature_Read_ReadData
        DataServices_Data_22FD2B_USS_Direct_Distance_0xFD2B_Read_ReadData
        DataServices_Data_22FD0E_Rear_Camera_Data_EEPROM_Read_ReadData
        DataServices_Data_22FD42_Failsafe_Behaviour_Read_WriteData
          data-send-points:
            access SEND_PpFailsafeDebug_Debugflag: accessed-variable=PpFailsafeDebug.Debugflag
          sync call SC_NvMService_AC3_SRBS_Defs_DID_FD42_FailsafeDebug_WriteBlock: operation=NvMService_AC3_SRBS_Defs_DID_FD42_FailsafeDebug.WriteBlock
          sync call SC_NvMService_AC3_SRBS_Defs_DID_FD42_FailsafeDebug_GetErrorStatus: operation=NvMService_AC3_SRBS_Defs_DID_FD42_FailsafeDebug.GetErrorStatus
        DataServices_Data_22FD42_Failsafe_Behaviour_Read_ReadData
        DataServices_Data_22F186_Active_Diagnostic_Session_ReadData
          sync call SC_RpSecureAuthenticationStatus_Get_SecureAuthenticationStatus: operation=RpSecureAuthenticationStatus.Get_ADAStatus
        DataServices_Data_22FDF1_CPU_Load_Read_ReadData
        DataServices_Data_22442A_USS_Sensor_10_Part_Number_Read_ReadData
        DataServices_Data_22FD07_OC_Result_Read_ReadData
        DataServices_Data_22FD2E_USS_Sensor_ID_Murata_SN_Read_ReadData
        DataServices_Data_225300_Rear_Braking_Event_1_Read_ReadData
        DataServices_Data_22442B_USS_Sensor_11_Part_Number_Read_ReadData
        DataServices_Data_224429_USS_Sensor_9_Part_Number_Read_ReadData
        DataServices_Data_22FD0C_Front_Camera_Data_EEPROM_Read_ReadData
        DataServices_Data_225100_SPM_status_Read_ReadData
        DataServices_Data_22200B_Time_First_DTC_Detection_ReadData
        DataServices_Data_224425_USS_Sensor_5_Part_Number_Read_ReadData
        DataServices_Data_22FD33_Magna_Testing_2_Read_WriteData
        DataServices_Data_22FD33_Magna_Testing_2_Read_ReadData
        DataServices_Data_22200C_Time_Since_Ignition_ON_of_first_DTC_Detection_ReadData
        DataServices_Data_224421_USS_Sensor_1_Part_Number_Read_ReadData
        DataServices_Data_225501_Trailer_coupler_sense_detection_Function_Data_Read_ReadData
        DataServices_Data_221002_Vehicle_Speed_ReadData
        DataServices_Data_22FD48_PCBA_Temperature_Read_ReadData
        DataServices_Data_221004_Battery_Voltage_ReadData
        DataServices_Data_221921_Operational_Mode_Status_ReadData
        DataServices_Data_2EF185_Application_Data_Software_Fingerprint_Writing_Information_WriteData
        DataServices_Data_22FD20_ECU_PinStates_Read_ReadData
        DataServices_Data_22FDF2_Reset_Reason_Read_ReadData
        DataServices_Data_224426_USS_Sensor_6_Part_Number_Read_ReadData
        DataServices_Data_22FD2A_USS_Ringing_Time_Read_ReadData
        DataServices_Data_224428_USS_Sensor_8_Part_Number_Read_ReadData
        DataServices_Data_22200A_Ignition_ON_Counter_ReadData
        DataServices_Data_222001_Odometer_ReadData
        DataServices_Data_22F1A6_Message_Matrix_ReadData
        DataServices_Data_22442C_USS_Sensor_12_Part_Number_Read_ReadData
        DataServices_Data_224427_USS_Sensor_7_Part_Number_Read_ReadData
        DataServices_Data_222008_ECU_Life_Time_Not_Volatile_Memory_ReadData
        DataServices_Data_22FD28_USS_Ringing_Frequency_Read_ReadData
        DataServices_Data_222002_Odometer_at_last_Flash_programming_ReadData
        DataServices_Data_2EF184_Application_Software_Fingerprint_writing_information_WriteData
        DataServices_Data_22FD1E_Calibration_Status_Read_ReadData
        DataServices_Data_224424_USS_Sensor_4_Part_Number_Read_ReadData
        DataServices_Data_221009_ECU_Time_Since_Ignition_ON_ReadData
        DataServices_Data_22FD29_USS_Driving_Frequency_Read_ReadData
        DataServices_Data_224422_USS_Sensor2_Part_Number_Read_ReadData
        DataServices_Data_225305_SPM_Event_Abort_3_Read_ReadData
        DataServices_Data_22FD01_Previous_Camera_Calibration_Data_ReadData
        DataServices_Data_22FD00_Plant_Camera_Calibration_Data_WriteData
        DataServices_Data_22FD00_Plant_Camera_Calibration_Data_ReadData
        DataServices_Data_22FD86_Functional_Settings_Read_WriteData
        DataServices_Data_22FD86_Functional_Settings_Read_ReadData
        DataServices_Data_22FD46_Camera_Power_Supply_Read_ReadData
        DataServices_Data_225102_FD_CAN14_Rx_Signals_Read_ReadData
        DataServices_Data_2F5001_Gear_Position_Read_ShortTermAdjustment
        DataServices_Data_2F5001_Gear_Position_Read_ReturnControlToECU
        DataServices_Data_2F5001_Gear_Position_Read_ReadData
        DataServices_Data_225105_FD_CAN2_Tx_Signals_Read_ReadData
        DataServices_Data_225103_FD_CAN2_Rx_Signals_Read_ReadData
        DataServices_Data_225104_FD_CAN14_Tx_Signals_Read_ReadData
        DataServices_Data_22FD62_ASIL_QM_Fault_Status_Read_ReadData
        DataServices_Data_222939_FDCAN2_BUS_Network_WakeUp_Reason_ReadData
        DataServices_Data_22FD47_SoC_Temperature_0xFD47_Read_ReadData
        DataServices_Data_22FD60_ECU_Software_Status_Read_ReadData
        DataServices_Data_22FD64_ASIL_B_Fault_Status_Read_ReadData
        DataServices_Data_2EFD4E_Reset_NVM_Write_WriteData
        DataServices_Data_22FD49_SoC_Die_Temperature_ID_0xFD49_Read_ReadData
        DataServices_Data_22FDF0_ECU_shutdown_process_Read_WriteData
        DataServices_Data_22FDF0_ECU_shutdown_process_Read_ReadData
        DataServices_Data_222026_CAN_Overrun_Counters_ReadData
        DataServices_Data_22102A_Check_EOL_Configuration_Data_ReadData
        DataServices_Data_225201_Plant_Mode_Status_Read_ReadData
        DataServices_Data_2E2023_PROXI_Data_WriteData
        DataServices_Data_220103_VIN_Lock_Status_ReadData
        DataServices_Data_222013_VIN_Lock_State_Read_ReadData
        DataServices_Data_22F1A1_Configuration_Code_ReadData
        DataServices_Data_22F190_VIN_Original_ReadData
        DataServices_Data_22FD61_Vehicle_Variant_Coding_Data_Read_ReadData
        DataServices_Data_22F1B0_VIN_Current_ReadData
        DataServices_Data_222024_Read_ECU_PROXI_Data_ReadDataLength
        DataServices_Data_222024_Read_ECU_PROXI_Data_ReadData
        DataServices_Data_22292E_PROXI_Write_Counter_ReadData
        DataServices_Data_22F10B_ECU_Qualification_ReadData
        DataServices_Data_22FD4A_Ultrasonic_Sensors_Power_supply_and_Current_Level_Read_ReadData
        DataServices_Data_225109_Rear_Sensor_HealthBlockage_LiveDetection_Check_Read_ReadData
        DataServices_Data_225107_Front_Sensor_HealthBlockage_LiveDetection_Check_Read_ReadData
        DataServices_Data_22FD65_FuSa_Module_Status_Read_ReadData
        Pp_NVM_Write_ProxiConfigTable_ProxiconfigTable_Nvm_write_confirmation
        DataServices_Data_22FD43_Active_Safe_State_Read
        DataServices_Data_22FD44_Error_Flags_Read
        DataServices_Data_22FD66_Camera_occlusion_and_low_light_status_Read
        DataServices_Data_22FD67_Camera_DLD_Status_Read
        RE_periodic_CPU_Load
        DataServices_Data_22FD74_PHY_Tunning_Error_And_Buffer_Mark_Error_Read_ReadData
          sync call SC_NvMService_AC3_SRBS_DID_FD74_PHY_TuningErr_SetRamBlockStatus: operation=NvMService_AC3_SRBS_DID_FD74_PHY_TuningErr.SetRamBlockStatus
          sync call SC_NvMService_AC3_SRBS_DID_FD74_BuffMarkCompErr_SetRamBlockStatus: operation=NvMService_AC3_SRBS_DID_FD74_BuffMarkCompErr.SetRamBlockStatus
        DataServices_Data_22FDF6_RunTimeStatsData_Read_ReadData
        DataServices_Data_22FDF7_Intrinsic_Camera_NvM_Data_Read_ReadData
        DataServices_Data_22FD04_USS_Sensor_tuning_values_Read_WriteData
        DataServices_Data_22FD04_USS_Sensor_tuning_values_Read_ReadDataLength
        DataServices_Data_22FD04_USS_Sensor_tuning_values_Read_ReadData
        DataServices_Data_22FDF8_StackUsage_Read_ReadData
        DataServices_Data_22FDF5_PerformanceStatEnable_Read_WriteData
        DataServices_Data_22FDF5_PerformanceStatEnable_Read_ReadData
      19 x swc service dependency, all with category=SERVICE:
        DID_FD33_MagnaTesting
          assigned-datas:
            role=ramBlock, used-data-element=DID_FD33_MagnaTesting_MirrorBlock
            role=defaultValue, used-parameter-element=DID_FD33_MagnaTesting_DefaultValue
          assigned-ports:
            NvMService_AC3_SRBS
            port-prototype=NvMService_AC3_SRBS_DID_FD33_MagnaTesting, role=NvMService_AC3_SRBS
          service-needs:
            nv block needs DID_FD33_MagnaTesting: n-data-sets=1, ram-block-status-control=API, reliability=NO-PROTECTION, restore-at-start=true, store-at-shutdown=true
        DID_2002_ProgReqFlag: assigned-ports=role-based-port-assignment={port-prototype=NvMService_AC3_SRBS_DID_2002_ProgReqFlag, role=NvMService_AC3_SRBS}
          assigned-datas:
            role=ramBlock, used-data-element=DID_2002_ProgReqFlag_MirrorBlock
            role=defaultValue, used-parameter-element=DID_2002_ProgReqFlag_DefaultValue
          service-needs:
            nv block needs DID_2002_ProgReqFlag: n-data-sets=1, ram-block-status-control=API, reliability=NO-PROTECTION, restore-at-start=true, store-at-shutdown=true
        DID_2002_OdoFlashing: assigned-ports=role-based-port-assignment={port-prototype=NvMService_AC3_SRBS_DID_2002_OdoFlashing, role=NvMService_AC3_SRBS}
          assigned-datas:
            role=ramBlock, used-data-element=DID_2002_OdoFlashing_MirrorBlock
            role=defaultValue, used-parameter-element=DID_2002_OdoFlashing_DefaultValue
          service-needs:
            nv block needs DID_2002_OdoFlashing: n-data-sets=1, ram-block-status-control=API, reliability=NO-PROTECTION, restore-at-start=true, store-at-shutdown=true
        DID_200D_LastClearDTCOdo: assigned-ports=role-based-port-assignment={port-prototype=NvMService_AC3_SRBS_DID_200D_LastClearDTCOdo, role=NvMService_AC3_SRBS}
          assigned-datas:
            role=ramBlock, used-data-element=DID_200D_LastClearDTCOdo_MirrorBlock
            role=defaultValue, used-parameter-element=DID_200D_LastClearDTCOdo_DefaultValue
          service-needs:
            nv block needs DID_200D_LastClearDTCOdo: n-data-sets=1, ram-block-status-control=API, reliability=NO-PROTECTION, restore-at-start=true, store-at-shutdown=true
        DID_200C_TimeSinceIgnOnFirstDTC: assigned-ports=role-based-port-assignment={port-prototype=NvMService_AC3_SRBS_DID_200C_TimeSinceIgnOnFirstDTC, role=NvMService_AC3_SRBS}
          assigned-datas:
            role=ramBlock, used-data-element=DID_200C_TimeSinceIgnOnFirstDTC_MirrorBlock
            role=defaultValue, used-parameter-element=DID_200C_TimeSinceIgnOnFirstDTC_DefaultValue
          service-needs:
            nv block needs DID_200C_TimeSinceIgnOnFirstDTC: n-data-sets=1, ram-block-status-control=API, reliability=NO-PROTECTION, restore-at-start=true, store-at-shutdown=true
        DID_200B_TimeSinceFirstDTC: assigned-ports=role-based-port-assignment={port-prototype=NvMService_AC3_SRBS_DID_200B_TimeSinceFirstDTC, role=NvMService_AC3_SRBS}
          assigned-datas:
            role=ramBlock, used-data-element=DID_200B_TimeSinceFirstDTC_MirrorBlock
            role=defaultValue, used-parameter-element=DID_200B_TimeSinceFirstDTC_DefaultValue
          service-needs:
            nv block needs DID_200B_TimeSinceFirstDTC: n-data-sets=1, ram-block-status-control=API, reliability=NO-PROTECTION, restore-at-start=true, store-at-shutdown=true
        DID_191D_PowerLatch: assigned-ports=role-based-port-assignment={port-prototype=NvMService_AC3_SRBS_DID_191D_PowerLatch, role=NvMService_AC3_SRBS}
          assigned-datas:
            role=ramBlock, used-data-element=DID_191D_PowerLatch_MirrorBlock
            role=defaultValue, used-parameter-element=DID_191D_PowerLatch_DefaultValue
          service-needs:
            nv block needs DID_191D_PowerLatch: n-data-sets=1, ram-block-status-control=API, reliability=NO-PROTECTION, restore-at-start=true, store-at-shutdown=true
        DID_200A_IgOnCounter: assigned-ports=role-based-port-assignment={port-prototype=NvMService_AC3_SRBS_DID_200A_IgOnCounter, role=NvMService_AC3_SRBS}
          assigned-datas:
            role=ramBlock, used-data-element=DID_200A_IgOnCounter_MirrorBlock
            role=defaultValue, used-parameter-element=DID_200A_IgOnCounter_DefaultValue
          service-needs:
            nv block needs DID_200A_IgOnCounter: n-data-sets=1, ram-block-status-control=API, reliability=NO-PROTECTION, restore-at-start=true, store-at-shutdown=true
        ECU_LifeTime: assigned-ports=role-based-port-assignment={port-prototype=NvMService_AC3_SRBS_ECU_LifeTime, role=NvMService_AC3_SRBS}
          assigned-datas:
            role=ramBlock, used-data-element=ECU_LifeTime_MirrorBlock
            role=defaultValue, used-parameter-element=ECU_LifeTime_DefaultValue
          service-needs:
            nv block needs ECU_LifeTime: n-data-sets=1, ram-block-status-control=API, reliability=NO-PROTECTION, restore-at-start=true, store-at-shutdown=true
        vRoE_Activation_State: assigned-ports=role-based-port-assignment={port-prototype=NvMService_AC3_SRBS_vRoE_Activation_State, role=NvMService_AC3_SRBS}
          assigned-datas:
            role=ramBlock, used-data-element=vRoE_Activation_State_MirrorBlock
            role=defaultValue, used-parameter-element=vRoE_Activation_State_DefaultValue
          service-needs:
            nv block needs vRoE_Activation_State: n-data-sets=1, ram-block-status-control=API, reliability=NO-PROTECTION, restore-at-start=true, store-at-shutdown=false, store-immediate=true
        DID_FD01_PrevCalibDataCopy: assigned-ports=role-based-port-assignment={port-prototype=NvMService_AC3_SRBS_DID_FD01_PrevCalibDataCopy, role=NvMService_AC3_SRBS}
          assigned-datas:
            role=defaultValue, used-parameter-element=DID_FD01_PrevCalibDataCopy_DefaultValue
            role=ramBlock, used-data-element=DID_FD01_PrevCalibDataCopy_MirrorBlock
          service-needs:
            nv block needs DID_FD01_PrevCalibDataCopy: n-data-sets=1, ram-block-status-control=API, reliability=NO-PROTECTION, restore-at-start=true, store-at-shutdown=true
        DID_FD42_FailsafeDebug: assigned-ports=role-based-port-assignment={port-prototype=NvMService_AC3_SRBS_Defs_DID_FD42_FailsafeDebug, role=NvMService_AC3_SRBS_Defs}
          assigned-datas:
            role=ramBlock, used-data-element=DID_FD42_FailsafeDebug_MirrorBlock
            role=defaultValue, used-parameter-element=DID_FD42_FailsafeDebug_DefaultValue
          service-needs:
            nv block needs DID_FD42_FailsafeDebug: n-data-sets=1, ram-block-status-control=API, reliability=NO-PROTECTION, restore-at-start=true, store-at-shutdown=false, store-immediate=true
        DID_RearBrakeEvent: assigned-ports=role-based-port-assignment={port-prototype=NvMService_AC3_SRBS_DID_RearBrakeEvent, role=NvMService_AC3_SRBS}
          assigned-datas:
            role=defaultValue, used-parameter-element=DID_RearBrakeEvent_DefaultValue
            role=ramBlock, used-data-element=DID_RearBrakeEvent_MirrorBlock
          service-needs:
            nv block needs DID_RearBrakeEvent: n-data-sets=1, ram-block-status-control=API, reliability=NO-PROTECTION, restore-at-start=true, store-at-shutdown=false, store-immediate=true
        DID_SPMAbrtEvent: assigned-ports=role-based-port-assignment={port-prototype=NvMService_AC3_SRBS_DID_SPMAbrtEvent, role=NvMService_AC3_SRBS}
          assigned-datas:
            role=defaultValue, used-parameter-element=DID_SPMAbrtEvent_DefaultValue
            role=ramBlock, used-data-element=DID_SPMAbrtEvent_MirrorBlock
          service-needs:
            nv block needs DID_SPMAbrtEvent: n-data-sets=1, ram-block-status-control=API, reliability=NO-PROTECTION, restore-at-start=true, store-at-shutdown=false, store-immediate=true
        DID_FD86_FunctionalSettings: assigned-ports=role-based-port-assignment={port-prototype=NvMService_AC3_SRBS_DID_FD86_FunctionalSettings, role=NvMService_AC3_SRBS}
          assigned-datas:
            role=ramBlock, used-data-element=DID_FD86_FunctionalSettings_MirrorBlock
            role=defaultValue, used-parameter-element=DID_FD86_FunctionalSettings_DefaultValue
          service-needs:
            nv block needs DID_FD86_FunctionalSettings: n-data-sets=1, ram-block-status-control=API, reliability=NO-PROTECTION, restore-at-start=true, store-at-shutdown=true
        DID_FDF0_SleepProcess: assigned-ports=role-based-port-assignment={port-prototype=NvMService_AC3_SRBS_DID_FDF0_SleepProcess, role=NvMService_AC3_SRBS}
          assigned-datas:
            role=ramBlock, used-data-element=DID_FDF0_SleepProcess_MirrorBlock
            role=defaultValue, used-parameter-element=DID_FDF0_SleepProcess_DefaultValue
          service-needs:
            nv block needs DID_FDF0_SleepProcess: n-data-sets=1, ram-block-status-control=API, reliability=NO-PROTECTION, restore-at-start=true, store-immediate=true
        DID_2939_WakeupReason: assigned-ports=role-based-port-assignment={port-prototype=NvMService_AC3_SRBS_DID_2939_WakeupReason, role=NvMService_AC3_SRBS}
          assigned-datas:
            role=ramBlock, used-data-element=DID_2939_WakeupReason_MirrorBlock
            role=defaultValue, used-parameter-element=DID_2939_WakeupReason_DefaultValue
          service-needs:
            nv block needs DID_2939_WakeupReason: n-data-sets=1, ram-block-status-control=API, reliability=NO-PROTECTION, restore-at-start=true, store-at-shutdown=true
        DID_FD74_PHY_TuningErr: assigned-ports=role-based-port-assignment={port-prototype=NvMService_AC3_SRBS_DID_FD74_PHY_TuningErr, role=NvMService_AC3_SRBS}
          assigned-datas:
            role=defaultValue, used-parameter-element=DID_FD74_PHY_TuningErr_DefaultValue
            role=ramBlock, used-data-element=DID_FD74_PHY_TuningErr_MirrorBlock
          service-needs:
            nv block needs DID_FD74_PHY_TuningErr: n-data-sets=1, ram-block-status-control=API, reliability=NO-PROTECTION, restore-at-start=true, store-at-shutdown=true
        DID_FD74_BuffMarkCompErr: assigned-ports=role-based-port-assignment={port-prototype=NvMService_AC3_SRBS_DID_FD74_BuffMarkCompErr, role=NvMService_AC3_SRBS}
          assigned-datas:
            role=defaultValue, used-parameter-element=DID_FD74_BuffMarkCompErr_DefaultValue
            role=ramBlock, used-data-element=DID_FD74_BuffMarkCompErr_MirrorBlock
          service-needs:
            nv block needs DID_FD74_BuffMarkCompErr: n-data-sets=1, ram-block-status-control=API, reliability=NO-PROTECTION, restore-at-start=true, store-at-shutdown=true
  swc implementation SWC_DIDMgr_Implementation: programming-language=C, vendor-id=0, behavior=SWC_DIDMgr_InternalBehavior
    code-descriptors:
      code Default: artifact-descriptors=autosar-engineering-object=category=SWSRC
